VERSION ""

NS_ :

BS_:

BU_:  Inverter  Battery  Charger  Host

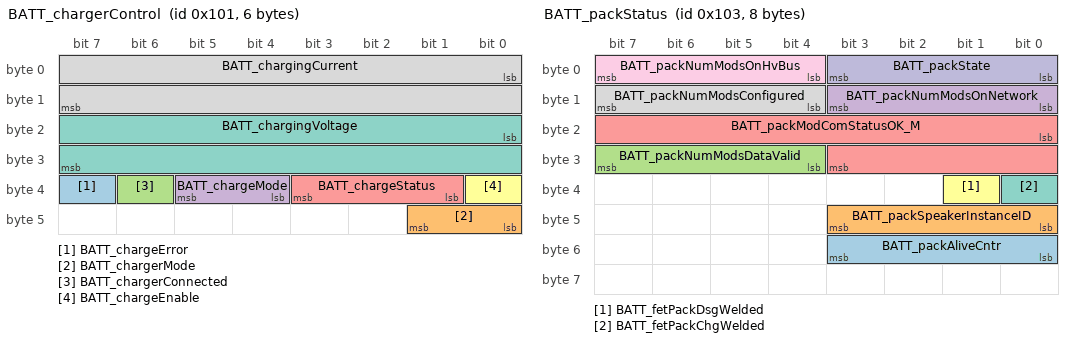
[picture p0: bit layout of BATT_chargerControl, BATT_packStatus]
BO_ 257 BATT_chargerControl: 6 Battery
 SG_ BATT_chargeError : 39|1@1+ (1,0) [0|1] "" Battery,Host
 SG_ BATT_chargerMode : 40|2@1+ (1,0) [0|3] "" Host
 SG_ BATT_chargerConnected : 38|1@1+ (1,0) [0|1] "" Battery,Host
 SG_ BATT_chargeMode : 36|2@1+ (1,0) [0|3] "" Host
 SG_ BATT_chargeStatus : 33|3@1+ (1,0) [0|4] "" Charger,Host
 SG_ BATT_chargeEnable : 32|1@1+ (1,0) [0|1] "" Charger,Host
 SG_ BATT_chargingVoltage : 16|16@1+ (0.005,0) [0|70] "V" Charger,Host
 SG_ BATT_chargingCurrent : 0|16@1+ (0.01,0) [0|40.95] "A" Charger,Host

BO_ 259 BATT_packStatus: 8 Battery
 SG_ BATT_packAliveCntr : 48|4@1+ (1,0) [0|15] "" Host
 SG_ BATT_packSpeakerInstanceID : 40|4@1+ (1,0) [0|15] "" Host
 SG_ BATT_packNumModsDataValid : 28|4@1+ (1,0) [0|15] "" Host
 SG_ BATT_packNumModsOnNetwork : 8|4@1+ (1,0) [0|15] "" Host
 SG_ BATT_packModComStatusOK_M : 16|12@1+ (1,0) [0|4095] "" Host
 SG_ BATT_fetPackDsgWelded : 33|1@1+ (1,0) [0|1] "" Host
 SG_ BATT_fetPackChgWelded : 32|1@1+ (1,0) [0|1] "" Host
 SG_ BATT_packNumModsConfigured : 12|4@1+ (1,0) [0|15] "" Host
 SG_ BATT_packNumModsOnHvBus : 4|4@1+ (1,0) [0|15] "" Host
 SG_ BATT_packState : 0|4@1+ (1,0) [0|15] "" Host

BO_ 260 BATT_packCapacity: 4 Battery
 SG_ BATT_packRemainingCap_Ah : 16|16@1+ (0.005,0) [0|327.675] "Ah" Host
 SG_ BATT_packFullChargeCap_Ah : 0|16@1+ (0.005,0) [0|327.675] "Ah" Host

BO_ 261 BATT_packSOC: 4 Battery
 SG_ BATT_packUserSOC : 0|16@1+ (0.1,0) [0|102.3] "%" Host
 SG_ BATT_packSOC : 16|16@1+ (0.1,0) [0|102.3] "%" Host

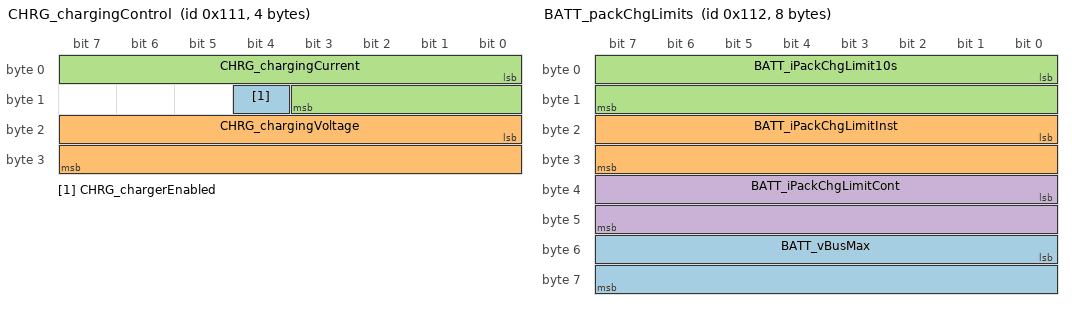
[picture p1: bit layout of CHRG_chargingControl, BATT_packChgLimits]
BO_ 273 CHRG_chargingControl: 4 Charger
 SG_ CHRG_chargerEnabled : 12|1@1+ (1,0) [0|1] "" Battery
 SG_ CHRG_chargingVoltage : 16|16@1+ (0.00076,0) [0|49.8066] "V" Battery
 SG_ CHRG_chargingCurrent : 0|12@1+ (0.01,0) [0|40.95] "A" Battery

BO_ 274 BATT_packChgLimits: 8 Battery
 SG_ BATT_vBusMax : 48|16@1+ (0.005,0) [0|70] "V" Inverter,Host
 SG_ BATT_iPackChgLimitInst : 16|16@1+ (0.01,0) [0|650] "A" Inverter,Host
 SG_ BATT_iPackChgLimit10s : 0|16@1+ (0.01,0) [0|650] "A" Inverter,Host
 SG_ BATT_iPackChgLimitCont : 32|16@1+ (0.01,0) [0|650] "A" Inverter,Host

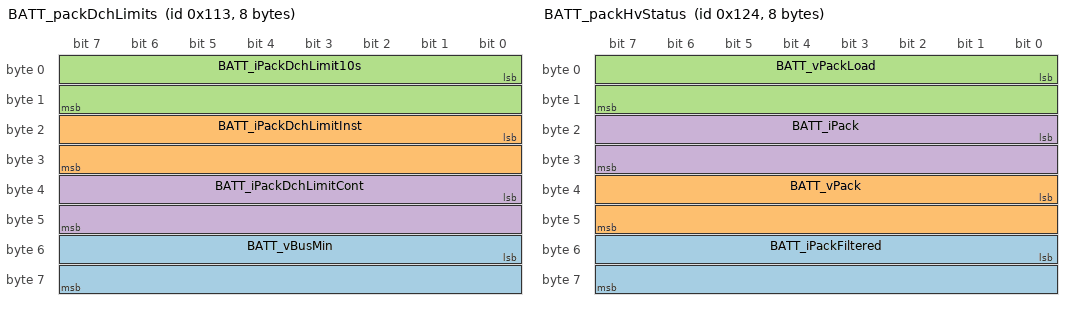
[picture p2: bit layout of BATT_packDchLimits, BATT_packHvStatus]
BO_ 275 BATT_packDchLimits: 8 Battery
 SG_ BATT_vBusMin : 48|16@1+ (0.005,0) [0|70] "V" Inverter,Host
 SG_ BATT_iPackDchLimitInst : 16|16@1- (0.03,0) [-1600|4] "A" Inverter,Host
 SG_ BATT_iPackDchLimit10s : 0|16@1- (0.03,0) [-1600|4] "A" Inverter,Host
 SG_ BATT_iPackDchLimitCont : 32|16@1- (0.03,0) [-1600|4] "A" Inverter,Host

BO_ 276 BATT_packPwrAvailable: 4 Battery
 SG_ BATT_pwrPackDchLimit : 16|16@1+ (0.02,0) [0|1200] "kW" Inverter,Host
 SG_ BATT_pwrPackChgLimit : 0|16@1+ (0.02,0) [0|1200] "kW" Inverter,Host

BO_ 277 INV_power: 4 Inverter
 SG_ INV_voltage : 0|16@1+ (0.00076,0) [0|49.8066] "V" Battery
 SG_ INV_current : 16|12@1+ (0.01,0) [0|40.95] "A" Battery

BO_ 292 BATT_packHvStatus: 8 Battery
 SG_ BATT_iPackFiltered : 48|16@1- (0.02,0) [-480|240] "A" Host
 SG_ BATT_vPack : 32|16@1+ (0.01,0) [0|70] "V" Host
 SG_ BATT_vPackLoad : 0|16@1+ (0.01,0) [0|70] "V" Host
 SG_ BATT_iPack : 16|16@1- (0.02,0) [-480|240] "" Host

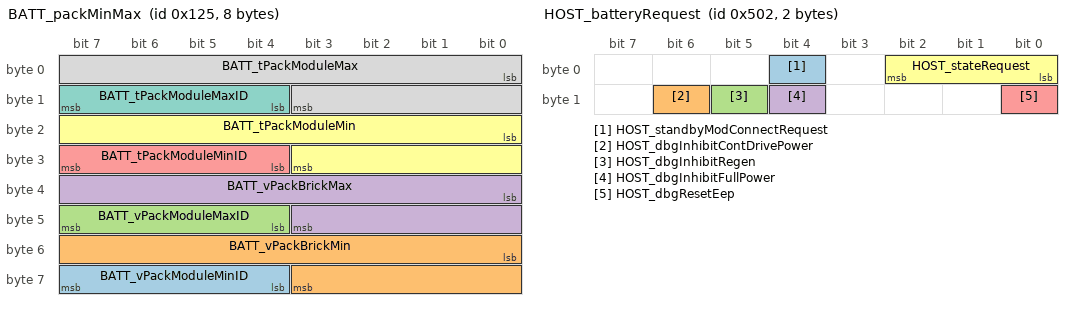
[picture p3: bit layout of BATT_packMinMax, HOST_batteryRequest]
BO_ 293 BATT_packMinMax: 8 Battery
 SG_ BATT_vPackModuleMinID : 60|4@1+ (1,0) [0|10] "" Host
 SG_ BATT_vPackBrickMin : 48|12@1+ (0.002,0) [0|4.98066] "V" Host
 SG_ BATT_vPackModuleMaxID : 44|4@1+ (1,0) [0|10] "" Host
 SG_ BATT_vPackBrickMax : 32|12@1+ (0.002,0) [0|4.98066] "V" Host
 SG_ BATT_tPackModuleMinID : 28|4@1+ (1,0) [0|10] "" Host
 SG_ BATT_tPackModuleMin : 16|12@1- (0.1,0) [-40|125] "deg C" Host
 SG_ BATT_tPackModuleMaxID : 12|4@1+ (1,0) [0|10] "" Host
 SG_ BATT_tPackModuleMax : 0|12@1- (0.1,0) [-40|125] "deg C" Host

BO_ 1282 HOST_batteryRequest: 2 Host
 SG_ HOST_standbyModConnectRequest : 4|1@1+ (1,0) [0|1] "" Battery
 SG_ HOST_dbgInhibitContDrivePower : 14|1@1+ (1,0) [0|1] "" Battery
 SG_ HOST_dbgInhibitRegen : 13|1@1+ (1,0) [0|1] "" Battery
 SG_ HOST_dbgInhibitFullPower : 12|1@1+ (1,0) [0|1] "" Battery
 SG_ HOST_dbgResetEep : 8|1@1+ (1,0) [0|1] "" Battery
 SG_ HOST_stateRequest : 0|3@1+ (1,0) [0|4] "" Battery

BO_ 1296 HOST_boardIO: 4 Host
 SG_ HOST_boardIO_PROTECTION_CHECK : 11|1@1+ (1,0) [0|0] "" Battery
 SG_ HOST_boardIO_BAL14 : 29|1@1+ (1,0) [0|0] "" Battery
 SG_ HOST_boardIO_BAL13 : 28|1@1+ (1,0) [0|0] "" Battery
 SG_ HOST_boardIO_BAL12 : 27|1@1+ (1,0) [0|0] "" Battery
 SG_ HOST_boardIO_BAL11 : 26|1@1+ (1,0) [0|0] "" Battery
 SG_ HOST_boardIO_BAL10 : 25|1@1+ (1,0) [0|0] "" Battery
 SG_ HOST_boardIO_BAL09 : 24|1@1+ (1,0) [0|0] "" Battery
 SG_ HOST_boardIO_BAL08 : 23|1@1+ (1,0) [0|0] "" Battery
 SG_ HOST_boardIO_BAL07 : 22|1@1+ (1,0) [0|0] "" Battery
 SG_ HOST_boardIO_BAL06 : 21|1@1+ (1,0) [0|0] "" Battery
 SG_ HOST_boardIO_BAL05 : 20|1@1+ (1,0) [0|0] "" Battery
 SG_ HOST_boardIO_BAL04 : 19|1@1+ (1,0) [0|0] "" Battery
 SG_ HOST_boardIO_BAL03 : 18|1@1+ (1,0) [0|0] "" Battery
 SG_ HOST_boardIO_BAL02 : 17|1@1+ (1,0) [0|0] "" Battery
 SG_ HOST_boardIO_BAL01 : 16|1@1+ (1,0) [0|0] "" Battery
 SG_ HOST_boardIO_LED4 : 8|1@1+ (1,0) [0|0] "" Battery
 SG_ HOST_boardIO_LED3 : 6|1@1+ (1,0) [0|0] "" Battery
 SG_ HOST_boardIO_LED2 : 2|1@1+ (1,0) [0|0] "" Battery
 SG_ HOST_boardIO_LED1 : 0|1@1+ (1,0) [0|0] "" Battery
 SG_ HOST_boardIO_PCHG : 7|1@1+ (1,0) [0|0] "" Battery
 SG_ HOST_boardIO_nFLT_CLR : 5|1@1+ (1,0) [0|0] "" Battery
 SG_ HOST_boardIO_DSG_EN : 4|1@1+ (1,0) [0|0] "" Battery
 SG_ HOST_boardIO_CHG_EN : 1|1@1+ (1,0) [0|0] "" Battery

BO_ 1632 BATT_BOOT_INFO_MSG_0: 8 Battery

BO_ 1633 BATT_BOOT_INFO_MSG_1: 8 Battery

BO_ 1634 BATT_BOOT_INFO_MSG_2: 8 Battery

BO_ 1635 BATT_BOOT_INFO_MSG_3: 8 Battery

BO_ 1636 BATT_BOOT_INFO_MSG_4: 8 Battery

BO_ 1637 BATT_BOOT_INFO_MSG_5: 8 Battery

BO_ 1638 BATT_BOOT_INFO_MSG_6: 8 Battery

BO_ 1639 BATT_BOOT_INFO_MSG_7: 8 Battery

BO_ 1640 BATT_BOOT_INFO_MSG_8: 8 Battery

BO_ 1641 BATT_BOOT_INFO_MSG_9: 8 Battery

BO_ 1642 BATT_BOOT_INFO_MSG_10: 8 Battery

BO_ 1643 BATT_BOOT_INFO_MSG_11: 8 Battery

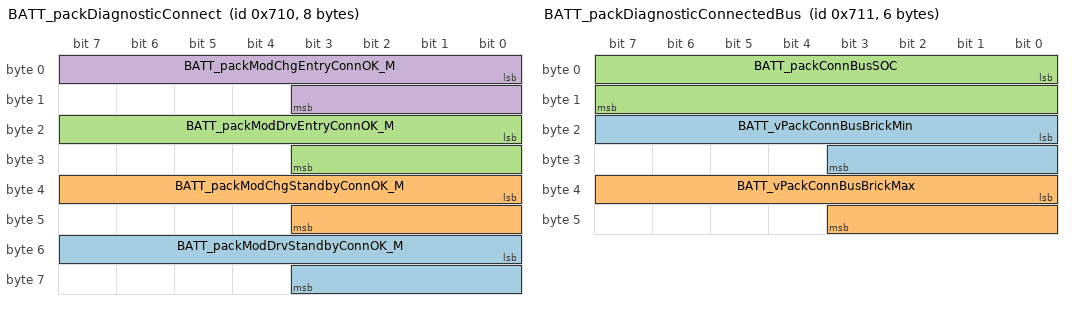
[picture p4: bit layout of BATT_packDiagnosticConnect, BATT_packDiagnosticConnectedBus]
BO_ 1808 BATT_packDiagnosticConnect: 8 Battery
 SG_ BATT_packModDrvStandbyConnOK_M : 48|12@1+ (1,0) [0|4095] "" Host
 SG_ BATT_packModChgStandbyConnOK_M : 32|12@1+ (1,0) [0|4095] "" Host
 SG_ BATT_packModDrvEntryConnOK_M : 16|12@1+ (1,0) [0|4095] "" Host
 SG_ BATT_packModChgEntryConnOK_M : 0|12@1+ (1,0) [0|4095] "" Host

BO_ 1809 BATT_packDiagnosticConnectedBus: 6 Battery
 SG_ BATT_vPackConnBusBrickMin : 16|12@1+ (0.002,0) [0|4.98066] "V" Host
 SG_ BATT_vPackConnBusBrickMax : 32|12@1+ (0.002,0) [0|4.98066] "V" Host
 SG_ BATT_packConnBusSOC : 0|16@1+ (0.1,0) [0|102.3] "%" Host

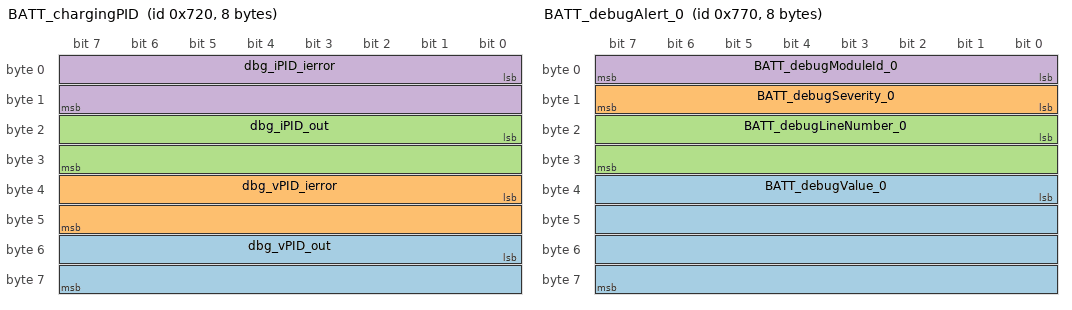
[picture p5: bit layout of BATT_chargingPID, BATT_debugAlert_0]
BO_ 1824 BATT_chargingPID: 8 Battery
 SG_ dbg_vPID_out : 48|16@1+ (0.01,0) [0|100] "" Host
 SG_ dbg_vPID_ierror : 32|16@1+ (0.1,0) [0|2000] "" Host
 SG_ dbg_iPID_out : 16|16@1+ (0.01,0) [0|100] "" Host
 SG_ dbg_iPID_ierror : 0|16@1+ (0.1,0) [0|2000] "" Host

BO_ 1904 BATT_debugAlert_0: 8 Battery
 SG_ BATT_debugValue_0 : 32|32@1+ (1,0) [0|4294967295] "" Host
 SG_ BATT_debugSeverity_0 : 8|8@1+ (1,0) [0|255] "" Host
 SG_ BATT_debugLineNumber_0 : 16|16@1+ (1,0) [0|65535] "" Host
 SG_ BATT_debugModuleId_0 : 0|8@1+ (1,0) [0|255] "" Host

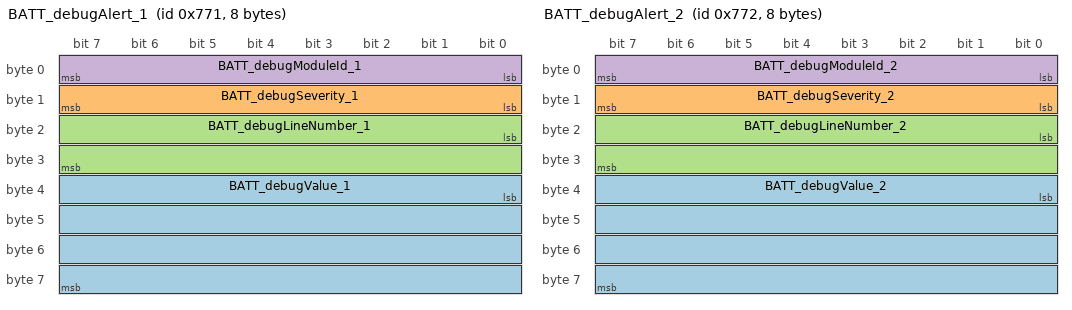
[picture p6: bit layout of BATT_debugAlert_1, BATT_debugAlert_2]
BO_ 1905 BATT_debugAlert_1: 8 Battery
 SG_ BATT_debugValue_1 : 32|32@1+ (1,0) [0|4294967295] "" Host
 SG_ BATT_debugSeverity_1 : 8|8@1+ (1,0) [0|255] "" Host
 SG_ BATT_debugLineNumber_1 : 16|16@1+ (1,0) [0|65535] "" Host
 SG_ BATT_debugModuleId_1 : 0|8@1+ (1,0) [0|255] "" Host

BO_ 1906 BATT_debugAlert_2: 8 Battery
 SG_ BATT_debugValue_2 : 32|32@1+ (1,0) [0|4294967295] "" Host
 SG_ BATT_debugSeverity_2 : 8|8@1+ (1,0) [0|255] "" Host
 SG_ BATT_debugLineNumber_2 : 16|16@1+ (1,0) [0|65535] "" Host
 SG_ BATT_debugModuleId_2 : 0|8@1+ (1,0) [0|255] "" Host

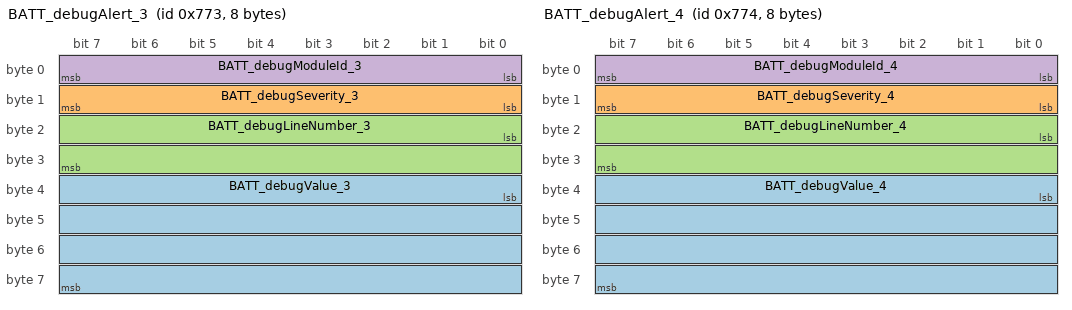
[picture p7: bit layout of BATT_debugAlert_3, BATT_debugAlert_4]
BO_ 1907 BATT_debugAlert_3: 8 Battery
 SG_ BATT_debugValue_3 : 32|32@1+ (1,0) [0|4294967295] "" Host
 SG_ BATT_debugSeverity_3 : 8|8@1+ (1,0) [0|255] "" Host
 SG_ BATT_debugLineNumber_3 : 16|16@1+ (1,0) [0|65535] "" Host
 SG_ BATT_debugModuleId_3 : 0|8@1+ (1,0) [0|255] "" Host

BO_ 1908 BATT_debugAlert_4: 8 Battery
 SG_ BATT_debugValue_4 : 32|32@1+ (1,0) [0|4294967295] "" Host
 SG_ BATT_debugSeverity_4 : 8|8@1+ (1,0) [0|255] "" Host
 SG_ BATT_debugLineNumber_4 : 16|16@1+ (1,0) [0|65535] "" Host
 SG_ BATT_debugModuleId_4 : 0|8@1+ (1,0) [0|255] "" Host

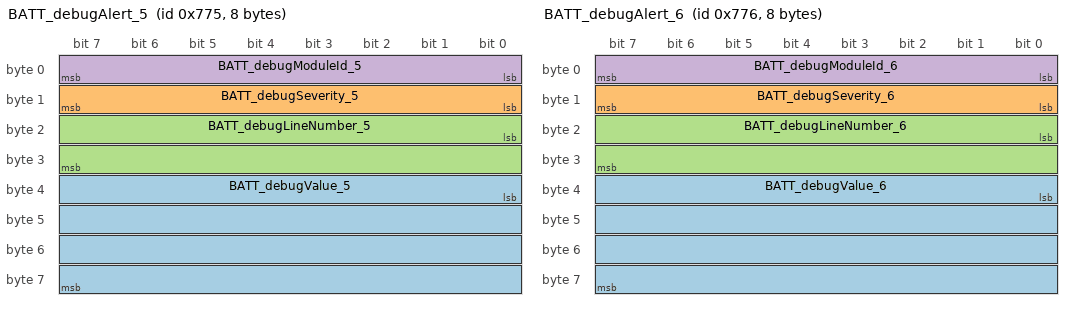
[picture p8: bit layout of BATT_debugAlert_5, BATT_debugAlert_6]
BO_ 1909 BATT_debugAlert_5: 8 Battery
 SG_ BATT_debugValue_5 : 32|32@1+ (1,0) [0|4294967295] "" Host
 SG_ BATT_debugSeverity_5 : 8|8@1+ (1,0) [0|255] "" Host
 SG_ BATT_debugLineNumber_5 : 16|16@1+ (1,0) [0|65535] "" Host
 SG_ BATT_debugModuleId_5 : 0|8@1+ (1,0) [0|255] "" Host

BO_ 1910 BATT_debugAlert_6: 8 Battery
 SG_ BATT_debugValue_6 : 32|32@1+ (1,0) [0|4294967295] "" Host
 SG_ BATT_debugSeverity_6 : 8|8@1+ (1,0) [0|255] "" Host
 SG_ BATT_debugLineNumber_6 : 16|16@1+ (1,0) [0|65535] "" Host
 SG_ BATT_debugModuleId_6 : 0|8@1+ (1,0) [0|255] "" Host

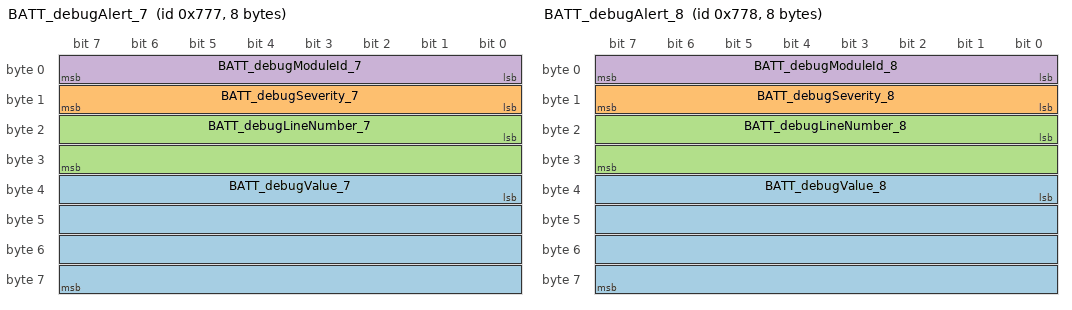
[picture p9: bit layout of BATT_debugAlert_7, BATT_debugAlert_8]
BO_ 1911 BATT_debugAlert_7: 8 Battery
 SG_ BATT_debugValue_7 : 32|32@1+ (1,0) [0|4294967295] "" Host
 SG_ BATT_debugSeverity_7 : 8|8@1+ (1,0) [0|255] "" Host
 SG_ BATT_debugLineNumber_7 : 16|16@1+ (1,0) [0|65535] "" Host
 SG_ BATT_debugModuleId_7 : 0|8@1+ (1,0) [0|255] "" Host

BO_ 1912 BATT_debugAlert_8: 8 Battery
 SG_ BATT_debugValue_8 : 32|32@1+ (1,0) [0|4294967295] "" Host
 SG_ BATT_debugSeverity_8 : 8|8@1+ (1,0) [0|255] "" Host
 SG_ BATT_debugLineNumber_8 : 16|16@1+ (1,0) [0|65535] "" Host
 SG_ BATT_debugModuleId_8 : 0|8@1+ (1,0) [0|255] "" Host

BO_ 1913 BATT_debugAlert_9: 8 Battery
 SG_ BATT_debugValue_9 : 32|32@1+ (1,0) [0|4294967295] "" Host
 SG_ BATT_debugSeverity_9 : 8|8@1+ (1,0) [0|255] "" Host
 SG_ BATT_debugLineNumber_9 : 16|16@1+ (1,0) [0|65535] "" Host
 SG_ BATT_debugModuleId_9 : 0|8@1+ (1,0) [0|255] "" Host

BO_ 1914 BATT_debugAlert_10: 8 Battery
 SG_ BATT_debugValue_10 : 32|32@1+ (1,0) [0|4294967295] "" Host
 SG_ BATT_debugSeverity_10 : 8|8@1+ (1,0) [0|255] "" Host
 SG_ BATT_debugLineNumber_10 : 16|16@1+ (1,0) [0|65535] "" Host
 SG_ BATT_debugModuleId_10 : 0|8@1+ (1,0) [0|255] "" Host

BO_ 1915 BATT_debugAlert_11: 8 Battery
 SG_ BATT_debugValue_11 : 32|32@1+ (1,0) [0|4294967295] "" Host
 SG_ BATT_debugSeverity_11 : 8|8@1+ (1,0) [0|255] "" Host
 SG_ BATT_debugLineNumber_11 : 16|16@1+ (1,0) [0|65535] "" Host
 SG_ BATT_debugModuleId_11 : 0|8@1+ (1,0) [0|255] "" Host

BO_ 1952 HOST_dbgChargePID: 8 Host
 SG_ dbg_iPID_ki : 48|16@1+ (0.01,0) [0|10] "" Battery
 SG_ dbg_iPID_kp : 32|16@1+ (0.01,0) [0|10] "" Battery
 SG_ dbg_vPID_ki : 16|16@1+ (0.01,0) [0|10] "" Battery
 SG_ dbg_vPID_kp : 0|16@1+ (0.01,0) [0|10] "" Battery

BO_ 1953 HOST_dbgChargeCtrl: 8 Host
 SG_ dbg_chargeCtrl_vTarget : 16|16@1+ (7.6e-05,0) [0|4.98066] "V" Battery
 SG_ dbg_chargeCtrl_iChgLimit : 0|16@1+ (0.01,0) [0|16] "A" Battery

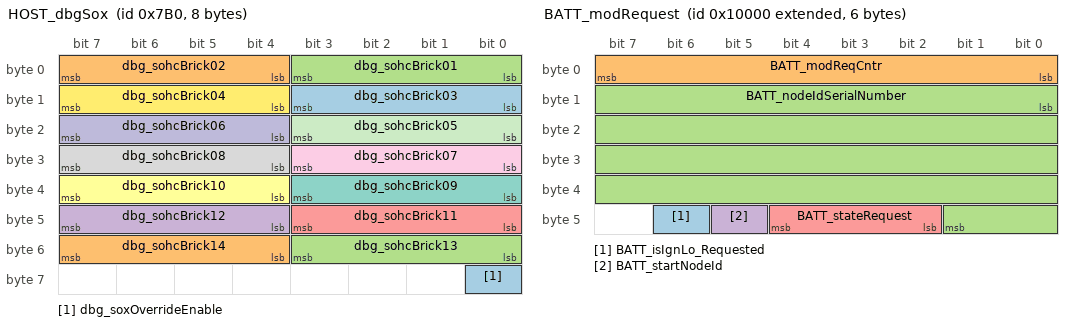
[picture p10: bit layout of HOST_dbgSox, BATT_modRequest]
BO_ 1968 HOST_dbgSox: 8 Host
 SG_ dbg_soxOverrideEnable : 56|1@1+ (1,0) [0|1] "" Battery
 SG_ dbg_sohcBrick14 : 52|4@1+ (0.015,0.775) [0.775|1] "" Battery
 SG_ dbg_sohcBrick13 : 48|4@1+ (0.015,0.775) [0.775|1] "" Battery
 SG_ dbg_sohcBrick12 : 44|4@1+ (0.015,0.775) [0.775|1] "" Battery
 SG_ dbg_sohcBrick11 : 40|4@1+ (0.015,0.775) [0.775|1] "" Battery
 SG_ dbg_sohcBrick10 : 36|4@1+ (0.015,0.775) [0.775|1] "" Battery
 SG_ dbg_sohcBrick09 : 32|4@1+ (0.015,0.775) [0.775|1] "" Battery
 SG_ dbg_sohcBrick08 : 28|4@1+ (0.015,0.775) [0.775|1] "" Battery
 SG_ dbg_sohcBrick07 : 24|4@1+ (0.015,0.775) [0.775|1] "" Battery
 SG_ dbg_sohcBrick06 : 20|4@1+ (0.015,0.775) [0.775|1] "" Battery
 SG_ dbg_sohcBrick05 : 16|4@1+ (0.015,0.775) [0.775|1] "" Battery
 SG_ dbg_sohcBrick04 : 12|4@1+ (0.015,0.775) [0.775|1] "" Battery
 SG_ dbg_sohcBrick03 : 8|4@1+ (0.015,0.775) [0.775|1] "" Battery
 SG_ dbg_sohcBrick02 : 4|4@1+ (0.015,0.775) [0.775|1] "" Battery
 SG_ dbg_sohcBrick01 : 0|4@1+ (0.015,0.775) [0.775|1] "" Battery

BO_ 2147500032 NODE_ID_CLAIM: 8 Battery
 SG_ NODE_ID_CLAIM_RND : 34|30@1+ (1,0) [0|4294967295] "" Battery,Host
 SG_ NODE_ID_CLAIM_SN : 0|34@1+ (1,0) [0|4294967295] "" Battery,Host

BO_ 2147516416 HOST_nodeRequest: 8 Host
 SG_ HOST_securityKey : 16|48@1+ (1,0) [0|281474976710655] "" Battery
 SG_ HOST_startNodeId : 0|1@1+ (1,0) [0|1] "" Battery

BO_ 2147549184 BATT_modRequest: 6 Battery
 SG_ BATT_isIgnLo_Requested : 46|1@1+ (1,0) [0|1] "" Battery,Host
 SG_ BATT_modReqCntr : 0|8@1+ (1,0) [0|255] "" Battery,Host
 SG_ BATT_nodeIdSerialNumber : 8|34@1+ (1,0) [0|17179869183] "" Battery,Host
 SG_ BATT_startNodeId : 45|1@1+ (1,0) [0|1] "" Battery,Host
 SG_ BATT_stateRequest : 42|3@1+ (1,0) [0|7] "" Battery,Host

BO_ 2176909312 BATT_diagnosticModBusStatus_0: 2 Battery
 SG_ BATT_timeBusQuietStandby_0 : 0|10@1+ (1,0) [0|1023] "seconds" Host
 SG_ BATT_timeBusQuietSleep_0 : 10|6@1+ (1,0) [0|63] "seconds" Host

BO_ 2176909313 BATT_diagnosticModBusStatus_1: 2 Battery
 SG_ BATT_timeBusQuietStandby_1 : 0|10@1+ (1,0) [0|1023] "seconds" Host
 SG_ BATT_timeBusQuietSleep_1 : 10|6@1+ (1,0) [0|63] "seconds" Host

BO_ 2176909314 BATT_diagnosticModBusStatus_2: 2 Battery
 SG_ BATT_timeBusQuietStandby_2 : 0|10@1+ (1,0) [0|1023] "seconds" Host
 SG_ BATT_timeBusQuietSleep_2 : 10|6@1+ (1,0) [0|63] "seconds" Host

BO_ 2176909315 BATT_diagnosticModBusStatus_3: 2 Battery
 SG_ BATT_timeBusQuietStandby_3 : 0|10@1+ (1,0) [0|1023] "seconds" Host
 SG_ BATT_timeBusQuietSleep_3 : 10|6@1+ (1,0) [0|63] "seconds" Host

BO_ 2176909316 BATT_diagnosticModBusStatus_4: 2 Battery
 SG_ BATT_timeBusQuietStandby_4 : 0|10@1+ (1,0) [0|1023] "seconds" Host
 SG_ BATT_timeBusQuietSleep_4 : 10|6@1+ (1,0) [0|63] "seconds" Host

BO_ 2176909317 BATT_diagnosticModBusStatus_5: 2 Battery
 SG_ BATT_timeBusQuietStandby_5 : 0|10@1+ (1,0) [0|1023] "seconds" Host
 SG_ BATT_timeBusQuietSleep_5 : 10|6@1+ (1,0) [0|63] "seconds" Host

BO_ 2176909318 BATT_diagnosticModBusStatus_6: 2 Battery
 SG_ BATT_timeBusQuietStandby_6 : 0|10@1+ (1,0) [0|1023] "seconds" Host
 SG_ BATT_timeBusQuietSleep_6 : 10|6@1+ (1,0) [0|63] "seconds" Host

BO_ 2176909319 BATT_diagnosticModBusStatus_7: 2 Battery
 SG_ BATT_timeBusQuietStandby_7 : 0|10@1+ (1,0) [0|1023] "seconds" Host
 SG_ BATT_timeBusQuietSleep_7 : 10|6@1+ (1,0) [0|63] "seconds" Host

BO_ 2176909320 BATT_diagnosticModBusStatus_8: 2 Battery
 SG_ BATT_timeBusQuietStandby_8 : 0|10@1+ (1,0) [0|1023] "seconds" Host
 SG_ BATT_timeBusQuietSleep_8 : 10|6@1+ (1,0) [0|63] "seconds" Host

BO_ 2176909321 BATT_diagnosticModBusStatus_9: 2 Battery
 SG_ BATT_timeBusQuietStandby_9 : 0|10@1+ (1,0) [0|1023] "seconds" Host
 SG_ BATT_timeBusQuietSleep_9 : 10|6@1+ (1,0) [0|63] "seconds" Host

BO_ 2176909322 BATT_diagnosticModBusStatus_10: 2 Battery
 SG_ BATT_timeBusQuietStandby_10 : 0|10@1+ (1,0) [0|1023] "seconds" Host
 SG_ BATT_timeBusQuietSleep_10 : 10|6@1+ (1,0) [0|63] "seconds" Host

BO_ 2176909323 BATT_diagnosticModBusStatus_11: 2 Battery
 SG_ BATT_timeBusQuietStandby_11 : 0|10@1+ (1,0) [0|1023] "seconds" Host
 SG_ BATT_timeBusQuietSleep_11 : 10|6@1+ (1,0) [0|63] "seconds" Host

BO_ 2215116800 BATT_modCapacity_0: 8 Battery
 SG_ BATT_modFullChargeCap_Ah_0 : 16|16@1+ (0.005,0) [0|327.675] "Ah" Battery,Host
 SG_ BATT_modRemainingCap_Ah_0 : 0|16@1+ (0.005,0) [0|327.675] "Ah" Battery,Host

BO_ 2215116801 BATT_modCapacity_1: 8 Battery
 SG_ BATT_modFullChargeCap_Ah_1 : 16|16@1+ (0.005,0) [0|327.675] "Ah" Battery,Host
 SG_ BATT_modRemainingCap_Ah_1 : 0|16@1+ (0.005,0) [0|327.675] "Ah" Battery,Host

BO_ 2215116802 BATT_modCapacity_2: 8 Battery
 SG_ BATT_modFullChargeCap_Ah_2 : 16|16@1+ (0.005,0) [0|327.675] "Ah" Battery,Host
 SG_ BATT_modRemainingCap_Ah_2 : 0|16@1+ (0.005,0) [0|327.675] "Ah" Battery,Host

BO_ 2215116803 BATT_modCapacity_3: 8 Battery
 SG_ BATT_modFullChargeCap_Ah_3 : 16|16@1+ (0.005,0) [0|327.675] "Ah" Battery,Host
 SG_ BATT_modRemainingCap_Ah_3 : 0|16@1+ (0.005,0) [0|327.675] "Ah" Battery,Host

BO_ 2215116804 BATT_modCapacity_4: 8 Battery
 SG_ BATT_modFullChargeCap_Ah_4 : 16|16@1+ (0.005,0) [0|327.675] "Ah" Battery,Host
 SG_ BATT_modRemainingCap_Ah_4 : 0|16@1+ (0.005,0) [0|327.675] "Ah" Battery,Host

BO_ 2215116805 BATT_modCapacity_5: 8 Battery
 SG_ BATT_modFullChargeCap_Ah_5 : 16|16@1+ (0.005,0) [0|327.675] "Ah" Battery,Host
 SG_ BATT_modRemainingCap_Ah_5 : 0|16@1+ (0.005,0) [0|327.675] "Ah" Battery,Host

BO_ 2215116806 BATT_modCapacity_6: 8 Battery
 SG_ BATT_modFullChargeCap_Ah_6 : 16|16@1+ (0.005,0) [0|327.675] "Ah" Battery,Host
 SG_ BATT_modRemainingCap_Ah_6 : 0|16@1+ (0.005,0) [0|327.675] "Ah" Battery,Host

BO_ 2215116807 BATT_modCapacity_7: 8 Battery
 SG_ BATT_modFullChargeCap_Ah_7 : 16|16@1+ (0.005,0) [0|327.675] "Ah" Battery,Host
 SG_ BATT_modRemainingCap_Ah_7 : 0|16@1+ (0.005,0) [0|327.675] "Ah" Battery,Host

BO_ 2215116808 BATT_modCapacity_8: 8 Battery
 SG_ BATT_modFullChargeCap_Ah_8 : 16|16@1+ (0.005,0) [0|327.675] "Ah" Battery,Host
 SG_ BATT_modRemainingCap_Ah_8 : 0|16@1+ (0.005,0) [0|327.675] "Ah" Battery,Host

BO_ 2215116809 BATT_modCapacity_9: 8 Battery
 SG_ BATT_modFullChargeCap_Ah_9 : 16|16@1+ (0.005,0) [0|327.675] "Ah" Battery,Host
 SG_ BATT_modRemainingCap_Ah_9 : 0|16@1+ (0.005,0) [0|327.675] "Ah" Battery,Host

BO_ 2215116810 BATT_modCapacity_10: 8 Battery
 SG_ BATT_modFullChargeCap_Ah_10 : 16|16@1+ (0.005,0) [0|327.675] "Ah" Battery,Host
 SG_ BATT_modRemainingCap_Ah_10 : 0|16@1+ (0.005,0) [0|327.675] "Ah" Battery,Host

BO_ 2215116811 BATT_modCapacity_11: 8 Battery
 SG_ BATT_modFullChargeCap_Ah_11 : 16|16@1+ (0.005,0) [0|327.675] "Ah" Battery,Host
 SG_ BATT_modRemainingCap_Ah_11 : 0|16@1+ (0.005,0) [0|327.675] "Ah" Battery,Host

BO_ 2215378944 BATT_modHvStatus_0: 8 Battery
 SG_ BATT_vMod_0 : 32|16@1+ (0.01,0) [0|70] "V" Battery,Host
 SG_ BATT_vModSumOfCells_0 : 48|16@1+ (0.01,0) [0|70] "V" Battery,Host
 SG_ BATT_iMod_0 : 16|16@1- (0.005,0) [-120|60] "A" Battery,Host
 SG_ BATT_iModFiltered_0 : 0|16@1- (0.005,0) [-120|60] "A" Battery,Host

BO_ 2215378945 BATT_modHvStatus_1: 8 Battery
 SG_ BATT_vMod_1 : 32|16@1+ (0.01,0) [0|70] "V" Battery,Host
 SG_ BATT_vModSumOfCells_1 : 48|16@1+ (0.01,0) [0|70] "V" Battery,Host
 SG_ BATT_iMod_1 : 16|16@1- (0.005,0) [-120|60] "A" Battery,Host
 SG_ BATT_iModFiltered_1 : 0|16@1- (0.005,0) [-120|60] "A" Battery,Host

BO_ 2215378946 BATT_modHvStatus_2: 8 Battery
 SG_ BATT_vMod_2 : 32|16@1+ (0.01,0) [0|70] "V" Battery,Host
 SG_ BATT_vModSumOfCells_2 : 48|16@1+ (0.01,0) [0|70] "V" Battery,Host
 SG_ BATT_iMod_2 : 16|16@1- (0.005,0) [-120|60] "A" Battery,Host
 SG_ BATT_iModFiltered_2 : 0|16@1- (0.005,0) [-120|60] "A" Battery,Host

BO_ 2215378947 BATT_modHvStatus_3: 8 Battery
 SG_ BATT_vMod_3 : 32|16@1+ (0.01,0) [0|70] "V" Battery,Host
 SG_ BATT_vModSumOfCells_3 : 48|16@1+ (0.01,0) [0|70] "V" Battery,Host
 SG_ BATT_iMod_3 : 16|16@1- (0.005,0) [-120|60] "A" Battery,Host
 SG_ BATT_iModFiltered_3 : 0|16@1- (0.005,0) [-120|60] "A" Battery,Host

BO_ 2215378948 BATT_modHvStatus_4: 8 Battery
 SG_ BATT_vMod_4 : 32|16@1+ (0.01,0) [0|70] "V" Battery,Host
 SG_ BATT_vModSumOfCells_4 : 48|16@1+ (0.01,0) [0|70] "V" Battery,Host
 SG_ BATT_iMod_4 : 16|16@1- (0.005,0) [-120|60] "A" Battery,Host
 SG_ BATT_iModFiltered_4 : 0|16@1- (0.005,0) [-120|60] "A" Battery,Host

BO_ 2215378949 BATT_modHvStatus_5: 8 Battery
 SG_ BATT_vMod_5 : 32|16@1+ (0.01,0) [0|70] "V" Battery,Host
 SG_ BATT_vModSumOfCells_5 : 48|16@1+ (0.01,0) [0|70] "V" Battery,Host
 SG_ BATT_iMod_5 : 16|16@1- (0.005,0) [-120|60] "A" Battery,Host
 SG_ BATT_iModFiltered_5 : 0|16@1- (0.005,0) [-120|60] "A" Battery,Host

BO_ 2215378950 BATT_modHvStatus_6: 8 Battery
 SG_ BATT_vMod_6 : 32|16@1+ (0.01,0) [0|70] "V" Battery,Host
 SG_ BATT_vModSumOfCells_6 : 48|16@1+ (0.01,0) [0|70] "V" Battery,Host
 SG_ BATT_iMod_6 : 16|16@1- (0.005,0) [-120|60] "A" Battery,Host
 SG_ BATT_iModFiltered_6 : 0|16@1- (0.005,0) [-120|60] "A" Battery,Host

BO_ 2215378951 BATT_modHvStatus_7: 8 Battery
 SG_ BATT_vMod_7 : 32|16@1+ (0.01,0) [0|70] "V" Battery,Host
 SG_ BATT_vModSumOfCells_7 : 48|16@1+ (0.01,0) [0|70] "V" Battery,Host
 SG_ BATT_iMod_7 : 16|16@1- (0.005,0) [-120|60] "A" Battery,Host
 SG_ BATT_iModFiltered_7 : 0|16@1- (0.005,0) [-120|60] "A" Battery,Host

BO_ 2215378952 BATT_modHvStatus_8: 8 Battery
 SG_ BATT_vMod_8 : 32|16@1+ (0.01,0) [0|70] "V" Battery,Host
 SG_ BATT_vModSumOfCells_8 : 48|16@1+ (0.01,0) [0|70] "V" Battery,Host
 SG_ BATT_iMod_8 : 16|16@1- (0.005,0) [-120|60] "A" Battery,Host
 SG_ BATT_iModFiltered_8 : 0|16@1- (0.005,0) [-120|60] "A" Battery,Host

BO_ 2215378953 BATT_modHvStatus_9: 8 Battery
 SG_ BATT_vMod_9 : 32|16@1+ (0.01,0) [0|70] "V" Battery,Host
 SG_ BATT_vModSumOfCells_9 : 48|16@1+ (0.01,0) [0|70] "V" Battery,Host
 SG_ BATT_iMod_9 : 16|16@1- (0.005,0) [-120|60] "A" Battery,Host
 SG_ BATT_iModFiltered_9 : 0|16@1- (0.005,0) [-120|60] "A" Battery,Host

BO_ 2215378954 BATT_modHvStatus_10: 8 Battery
 SG_ BATT_vMod_10 : 32|16@1+ (0.01,0) [0|70] "V" Battery,Host
 SG_ BATT_vModSumOfCells_10 : 48|16@1+ (0.01,0) [0|70] "V" Battery,Host
 SG_ BATT_iMod_10 : 16|16@1- (0.005,0) [-120|60] "A" Battery,Host
 SG_ BATT_iModFiltered_10 : 0|16@1- (0.005,0) [-120|60] "A" Battery,Host

BO_ 2215378955 BATT_modHvStatus_11: 8 Battery
 SG_ BATT_vMod_11 : 32|16@1+ (0.01,0) [0|70] "V" Battery,Host
 SG_ BATT_vModSumOfCells_11 : 48|16@1+ (0.01,0) [0|70] "V" Battery,Host
 SG_ BATT_iMod_11 : 16|16@1- (0.005,0) [-120|60] "A" Battery,Host
 SG_ BATT_iModFiltered_11 : 0|16@1- (0.005,0) [-120|60] "A" Battery,Host

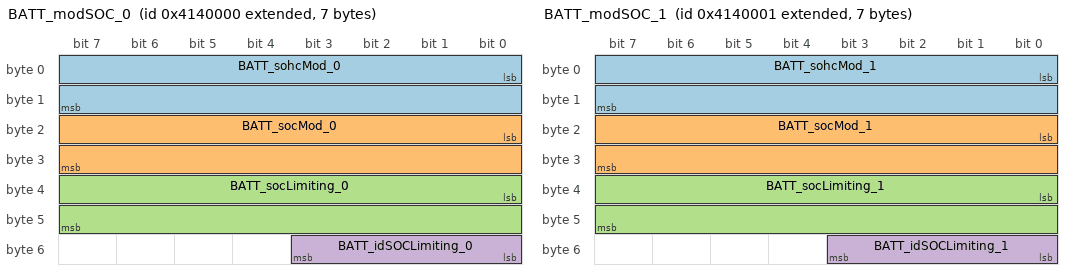
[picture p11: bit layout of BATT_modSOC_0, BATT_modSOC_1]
BO_ 2215903232 BATT_modSOC_0: 7 Battery
 SG_ BATT_sohcMod_0 : 0|16@1+ (0.01,0) [0|100] "%" Battery,Host
 SG_ BATT_socMod_0 : 16|16@1+ (0.01,0) [0|102.3] "%" Battery,Host
 SG_ BATT_socLimiting_0 : 32|16@1+ (0.01,0) [0|102.3] "%" Battery,Host
 SG_ BATT_idSOCLimiting_0 : 48|4@1+ (1,0) [0|14] "" Battery,Host

BO_ 2215903233 BATT_modSOC_1: 7 Battery
 SG_ BATT_sohcMod_1 : 0|16@1+ (0.01,0) [0|100] "%" Battery,Host
 SG_ BATT_socMod_1 : 16|16@1+ (0.01,0) [0|102.3] "%" Battery,Host
 SG_ BATT_socLimiting_1 : 32|16@1+ (0.01,0) [0|102.3] "%" Battery,Host
 SG_ BATT_idSOCLimiting_1 : 48|4@1+ (1,0) [0|14] "" Battery,Host

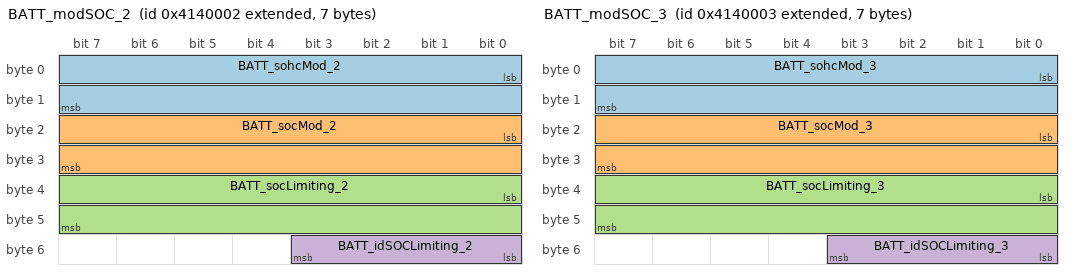
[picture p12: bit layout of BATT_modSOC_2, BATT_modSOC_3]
BO_ 2215903234 BATT_modSOC_2: 7 Battery
 SG_ BATT_sohcMod_2 : 0|16@1+ (0.01,0) [0|100] "%" Battery,Host
 SG_ BATT_socMod_2 : 16|16@1+ (0.01,0) [0|102.3] "%" Battery,Host
 SG_ BATT_socLimiting_2 : 32|16@1+ (0.01,0) [0|102.3] "%" Battery,Host
 SG_ BATT_idSOCLimiting_2 : 48|4@1+ (1,0) [0|14] "" Battery,Host

BO_ 2215903235 BATT_modSOC_3: 7 Battery
 SG_ BATT_sohcMod_3 : 0|16@1+ (0.01,0) [0|100] "%" Battery,Host
 SG_ BATT_socMod_3 : 16|16@1+ (0.01,0) [0|102.3] "%" Battery,Host
 SG_ BATT_socLimiting_3 : 32|16@1+ (0.01,0) [0|102.3] "%" Battery,Host
 SG_ BATT_idSOCLimiting_3 : 48|4@1+ (1,0) [0|14] "" Battery,Host

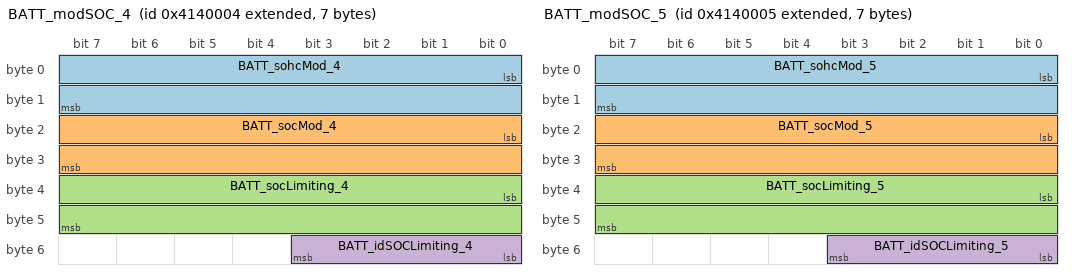
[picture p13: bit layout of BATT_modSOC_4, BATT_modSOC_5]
BO_ 2215903236 BATT_modSOC_4: 7 Battery
 SG_ BATT_sohcMod_4 : 0|16@1+ (0.01,0) [0|100] "%" Battery,Host
 SG_ BATT_socMod_4 : 16|16@1+ (0.01,0) [0|102.3] "%" Battery,Host
 SG_ BATT_socLimiting_4 : 32|16@1+ (0.01,0) [0|102.3] "%" Battery,Host
 SG_ BATT_idSOCLimiting_4 : 48|4@1+ (1,0) [0|14] "" Battery,Host

BO_ 2215903237 BATT_modSOC_5: 7 Battery
 SG_ BATT_sohcMod_5 : 0|16@1+ (0.01,0) [0|100] "%" Battery,Host
 SG_ BATT_socMod_5 : 16|16@1+ (0.01,0) [0|102.3] "%" Battery,Host
 SG_ BATT_socLimiting_5 : 32|16@1+ (0.01,0) [0|102.3] "%" Battery,Host
 SG_ BATT_idSOCLimiting_5 : 48|4@1+ (1,0) [0|14] "" Battery,Host

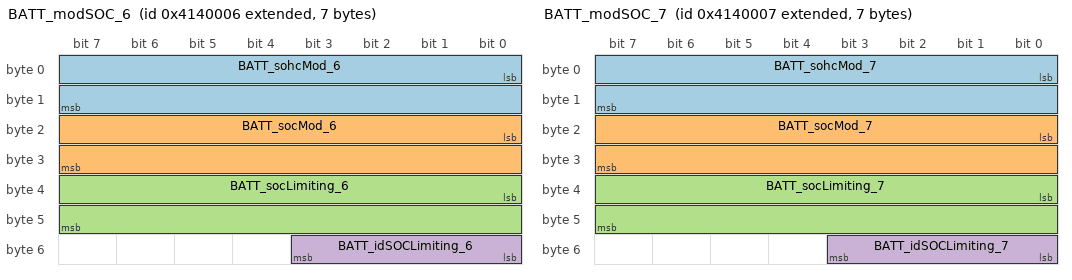
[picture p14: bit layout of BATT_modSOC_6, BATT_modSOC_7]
BO_ 2215903238 BATT_modSOC_6: 7 Battery
 SG_ BATT_sohcMod_6 : 0|16@1+ (0.01,0) [0|100] "%" Battery,Host
 SG_ BATT_socMod_6 : 16|16@1+ (0.01,0) [0|102.3] "%" Battery,Host
 SG_ BATT_socLimiting_6 : 32|16@1+ (0.01,0) [0|102.3] "%" Battery,Host
 SG_ BATT_idSOCLimiting_6 : 48|4@1+ (1,0) [0|14] "" Battery,Host

BO_ 2215903239 BATT_modSOC_7: 7 Battery
 SG_ BATT_sohcMod_7 : 0|16@1+ (0.01,0) [0|100] "%" Battery,Host
 SG_ BATT_socMod_7 : 16|16@1+ (0.01,0) [0|102.3] "%" Battery,Host
 SG_ BATT_socLimiting_7 : 32|16@1+ (0.01,0) [0|102.3] "%" Battery,Host
 SG_ BATT_idSOCLimiting_7 : 48|4@1+ (1,0) [0|14] "" Battery,Host

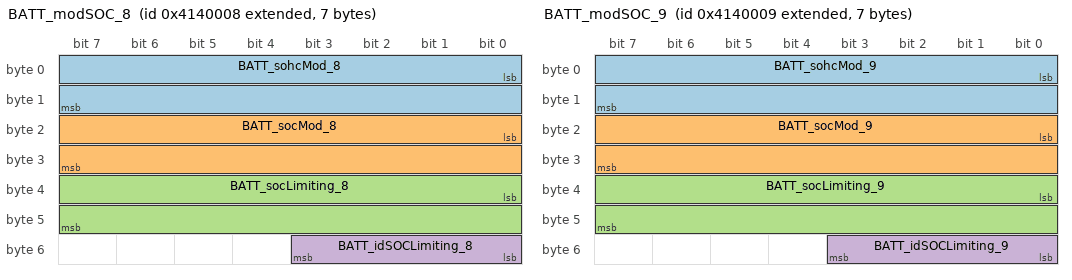
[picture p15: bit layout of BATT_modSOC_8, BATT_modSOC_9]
BO_ 2215903240 BATT_modSOC_8: 7 Battery
 SG_ BATT_sohcMod_8 : 0|16@1+ (0.01,0) [0|100] "%" Battery,Host
 SG_ BATT_socMod_8 : 16|16@1+ (0.01,0) [0|102.3] "%" Battery,Host
 SG_ BATT_socLimiting_8 : 32|16@1+ (0.01,0) [0|102.3] "%" Battery,Host
 SG_ BATT_idSOCLimiting_8 : 48|4@1+ (1,0) [0|14] "" Battery,Host

BO_ 2215903241 BATT_modSOC_9: 7 Battery
 SG_ BATT_sohcMod_9 : 0|16@1+ (0.01,0) [0|100] "%" Battery,Host
 SG_ BATT_socMod_9 : 16|16@1+ (0.01,0) [0|102.3] "%" Battery,Host
 SG_ BATT_socLimiting_9 : 32|16@1+ (0.01,0) [0|102.3] "%" Battery,Host
 SG_ BATT_idSOCLimiting_9 : 48|4@1+ (1,0) [0|14] "" Battery,Host

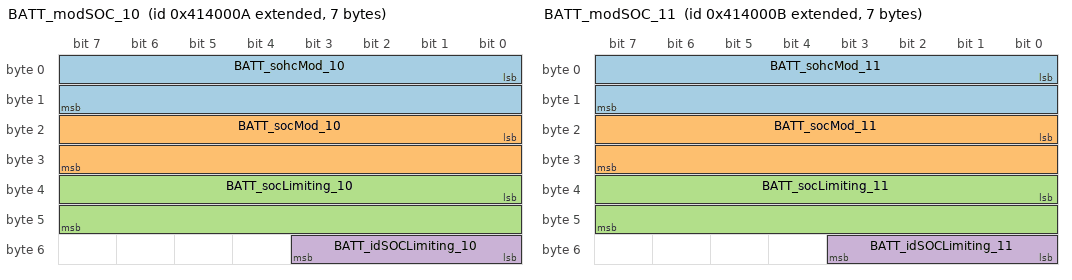
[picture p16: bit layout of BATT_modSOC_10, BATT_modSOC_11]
BO_ 2215903242 BATT_modSOC_10: 7 Battery
 SG_ BATT_sohcMod_10 : 0|16@1+ (0.01,0) [0|100] "%" Battery,Host
 SG_ BATT_socMod_10 : 16|16@1+ (0.01,0) [0|102.3] "%" Battery,Host
 SG_ BATT_socLimiting_10 : 32|16@1+ (0.01,0) [0|102.3] "%" Battery,Host
 SG_ BATT_idSOCLimiting_10 : 48|4@1+ (1,0) [0|14] "" Battery,Host

BO_ 2215903243 BATT_modSOC_11: 7 Battery
 SG_ BATT_sohcMod_11 : 0|16@1+ (0.01,0) [0|100] "%" Battery,Host
 SG_ BATT_socMod_11 : 16|16@1+ (0.01,0) [0|102.3] "%" Battery,Host
 SG_ BATT_socLimiting_11 : 32|16@1+ (0.01,0) [0|102.3] "%" Battery,Host
 SG_ BATT_idSOCLimiting_11 : 48|4@1+ (1,0) [0|14] "" Battery,Host

BO_ 2219376640 BATT_modChgLimits_0: 8 Battery
 SG_ BATT_vModChgLimit_0 : 48|16@1+ (0.005,0) [0|70] "V" Host,Battery
 SG_ BATT_iModChgLimitInst_0 : 32|16@1+ (0.01,0) [0|75] "A" Host,Battery
 SG_ BATT_iModChgLimit10s_0 : 0|16@1+ (0.01,0) [0|75] "A" Host,Battery
 SG_ BATT_iModChgLimitCont_0 : 16|16@1+ (0.01,0) [0|60] "A" Battery,Host

BO_ 2219376641 BATT_modChgLimits_1: 8 Battery
 SG_ BATT_vModChgLimit_1 : 48|16@1+ (0.005,0) [0|70] "V" Host,Battery
 SG_ BATT_iModChgLimitInst_1 : 32|16@1+ (0.01,0) [0|75] "A" Host,Battery
 SG_ BATT_iModChgLimit10s_1 : 0|16@1+ (0.01,0) [0|75] "A" Host,Battery
 SG_ BATT_iModChgLimitCont_1 : 16|16@1+ (0.01,0) [0|60] "A" Battery,Host

BO_ 2219376642 BATT_modChgLimits_2: 8 Battery
 SG_ BATT_vModChgLimit_2 : 48|16@1+ (0.005,0) [0|70] "V" Host,Battery
 SG_ BATT_iModChgLimitInst_2 : 32|16@1+ (0.01,0) [0|75] "A" Host,Battery
 SG_ BATT_iModChgLimit10s_2 : 0|16@1+ (0.01,0) [0|75] "A" Host,Battery
 SG_ BATT_iModChgLimitCont_2 : 16|16@1+ (0.01,0) [0|60] "A" Battery,Host

BO_ 2219376643 BATT_modChgLimits_3: 8 Battery
 SG_ BATT_vModChgLimit_3 : 48|16@1+ (0.005,0) [0|70] "V" Host,Battery
 SG_ BATT_iModChgLimitInst_3 : 32|16@1+ (0.01,0) [0|75] "A" Host,Battery
 SG_ BATT_iModChgLimit10s_3 : 0|16@1+ (0.01,0) [0|75] "A" Host,Battery
 SG_ BATT_iModChgLimitCont_3 : 16|16@1+ (0.01,0) [0|60] "A" Battery,Host

BO_ 2219376644 BATT_modChgLimits_4: 8 Battery
 SG_ BATT_vModChgLimit_4 : 48|16@1+ (0.005,0) [0|70] "V" Host,Battery
 SG_ BATT_iModChgLimitInst_4 : 32|16@1+ (0.01,0) [0|75] "A" Host,Battery
 SG_ BATT_iModChgLimit10s_4 : 0|16@1+ (0.01,0) [0|75] "A" Host,Battery
 SG_ BATT_iModChgLimitCont_4 : 16|16@1+ (0.01,0) [0|60] "A" Battery,Host

BO_ 2219376645 BATT_modChgLimits_5: 8 Battery
 SG_ BATT_vModChgLimit_5 : 48|16@1+ (0.005,0) [0|70] "V" Host,Battery
 SG_ BATT_iModChgLimitInst_5 : 32|16@1+ (0.01,0) [0|75] "A" Host,Battery
 SG_ BATT_iModChgLimit10s_5 : 0|16@1+ (0.01,0) [0|75] "A" Host,Battery
 SG_ BATT_iModChgLimitCont_5 : 16|16@1+ (0.01,0) [0|60] "A" Battery,Host

BO_ 2219376646 BATT_modChgLimits_6: 8 Battery
 SG_ BATT_vModChgLimit_6 : 48|16@1+ (0.005,0) [0|70] "V" Host,Battery
 SG_ BATT_iModChgLimitInst_6 : 32|16@1+ (0.01,0) [0|75] "A" Host,Battery
 SG_ BATT_iModChgLimit10s_6 : 0|16@1+ (0.01,0) [0|75] "A" Host,Battery
 SG_ BATT_iModChgLimitCont_6 : 16|16@1+ (0.01,0) [0|60] "A" Battery,Host

BO_ 2219376647 BATT_modChgLimits_7: 8 Battery
 SG_ BATT_vModChgLimit_7 : 48|16@1+ (0.005,0) [0|70] "V" Host,Battery
 SG_ BATT_iModChgLimitInst_7 : 32|16@1+ (0.01,0) [0|75] "A" Host,Battery
 SG_ BATT_iModChgLimit10s_7 : 0|16@1+ (0.01,0) [0|75] "A" Host,Battery
 SG_ BATT_iModChgLimitCont_7 : 16|16@1+ (0.01,0) [0|60] "A" Battery,Host

BO_ 2219376648 BATT_modChgLimits_8: 8 Battery
 SG_ BATT_vModChgLimit_8 : 48|16@1+ (0.005,0) [0|70] "V" Host,Battery
 SG_ BATT_iModChgLimitInst_8 : 32|16@1+ (0.01,0) [0|75] "A" Host,Battery
 SG_ BATT_iModChgLimit10s_8 : 0|16@1+ (0.01,0) [0|75] "A" Host,Battery
 SG_ BATT_iModChgLimitCont_8 : 16|16@1+ (0.01,0) [0|60] "A" Battery,Host

BO_ 2219376649 BATT_modChgLimits_9: 8 Battery
 SG_ BATT_vModChgLimit_9 : 48|16@1+ (0.005,0) [0|70] "V" Host,Battery
 SG_ BATT_iModChgLimitInst_9 : 32|16@1+ (0.01,0) [0|75] "A" Host,Battery
 SG_ BATT_iModChgLimit10s_9 : 0|16@1+ (0.01,0) [0|75] "A" Host,Battery
 SG_ BATT_iModChgLimitCont_9 : 16|16@1+ (0.01,0) [0|60] "A" Battery,Host

BO_ 2219376650 BATT_modChgLimits_10: 8 Battery
 SG_ BATT_vModChgLimit_10 : 48|16@1+ (0.005,0) [0|70] "V" Host,Battery
 SG_ BATT_iModChgLimitInst_10 : 32|16@1+ (0.01,0) [0|75] "A" Host,Battery
 SG_ BATT_iModChgLimit10s_10 : 0|16@1+ (0.01,0) [0|75] "A" Host,Battery
 SG_ BATT_iModChgLimitCont_10 : 16|16@1+ (0.01,0) [0|60] "A" Battery,Host

BO_ 2219376651 BATT_modChgLimits_11: 8 Battery
 SG_ BATT_vModChgLimit_11 : 48|16@1+ (0.005,0) [0|70] "V" Host,Battery
 SG_ BATT_iModChgLimitInst_11 : 32|16@1+ (0.01,0) [0|75] "A" Host,Battery
 SG_ BATT_iModChgLimit10s_11 : 0|16@1+ (0.01,0) [0|75] "A" Host,Battery
 SG_ BATT_iModChgLimitCont_11 : 16|16@1+ (0.01,0) [0|60] "A" Battery,Host

BO_ 2219573248 BATT_modDchLimits_0: 8 Battery
 SG_ BATT_vModDchLimit_0 : 48|16@1+ (0.005,0) [0|70] "V" Host,Battery
 SG_ BATT_iModDchLimitInst_0 : 32|16@1- (0.01,0) [-200|1] "A" Host,Battery
 SG_ BATT_iModDchLimit10s_0 : 16|16@1- (0.01,0) [-200|1] "A" Host,Battery
 SG_ BATT_iModDchLimitCont_0 : 0|16@1- (0.01,0) [-120|1] "A" Host,Battery

BO_ 2219573249 BATT_modDchLimits_1: 8 Battery
 SG_ BATT_vModDchLimit_1 : 48|16@1+ (0.005,0) [0|70] "V" Host,Battery
 SG_ BATT_iModDchLimitInst_1 : 32|16@1- (0.01,0) [-200|1] "A" Host,Battery
 SG_ BATT_iModDchLimit10s_1 : 16|16@1- (0.01,0) [-200|1] "A" Host,Battery
 SG_ BATT_iModDchLimitCont_1 : 0|16@1- (0.01,0) [-120|1] "A" Host,Battery

BO_ 2219573250 BATT_modDchLimits_2: 8 Battery
 SG_ BATT_vModDchLimit_2 : 48|16@1+ (0.005,0) [0|70] "V" Host,Battery
 SG_ BATT_iModDchLimitInst_2 : 32|16@1- (0.01,0) [-200|1] "A" Host,Battery
 SG_ BATT_iModDchLimit10s_2 : 16|16@1- (0.01,0) [-200|1] "A" Host,Battery
 SG_ BATT_iModDchLimitCont_2 : 0|16@1- (0.01,0) [-120|1] "A" Host,Battery

BO_ 2219573251 BATT_modDchLimits_3: 8 Battery
 SG_ BATT_vModDchLimit_3 : 48|16@1+ (0.005,0) [0|70] "V" Host,Battery
 SG_ BATT_iModDchLimitInst_3 : 32|16@1- (0.01,0) [-200|1] "A" Host,Battery
 SG_ BATT_iModDchLimit10s_3 : 16|16@1- (0.01,0) [-200|1] "A" Host,Battery
 SG_ BATT_iModDchLimitCont_3 : 0|16@1- (0.01,0) [-120|1] "A" Host,Battery

BO_ 2219573252 BATT_modDchLimits_4: 8 Battery
 SG_ BATT_vModDchLimit_4 : 48|16@1+ (0.005,0) [0|70] "V" Host,Battery
 SG_ BATT_iModDchLimitInst_4 : 32|16@1- (0.01,0) [-200|1] "A" Host,Battery
 SG_ BATT_iModDchLimit10s_4 : 16|16@1- (0.01,0) [-200|1] "A" Host,Battery
 SG_ BATT_iModDchLimitCont_4 : 0|16@1- (0.01,0) [-120|1] "A" Host,Battery

BO_ 2219573253 BATT_modDchLimits_5: 8 Battery
 SG_ BATT_vModDchLimit_5 : 48|16@1+ (0.005,0) [0|70] "V" Host,Battery
 SG_ BATT_iModDchLimitInst_5 : 32|16@1- (0.01,0) [-200|1] "A" Host,Battery
 SG_ BATT_iModDchLimit10s_5 : 16|16@1- (0.01,0) [-200|1] "A" Host,Battery
 SG_ BATT_iModDchLimitCont_5 : 0|16@1- (0.01,0) [-120|1] "A" Host,Battery

BO_ 2219573254 BATT_modDchLimits_6: 8 Battery
 SG_ BATT_vModDchLimit_6 : 48|16@1+ (0.005,0) [0|70] "V" Host,Battery
 SG_ BATT_iModDchLimitInst_6 : 32|16@1- (0.01,0) [-200|1] "A" Host,Battery
 SG_ BATT_iModDchLimit10s_6 : 16|16@1- (0.01,0) [-200|1] "A" Host,Battery
 SG_ BATT_iModDchLimitCont_6 : 0|16@1- (0.01,0) [-120|1] "A" Host,Battery

BO_ 2219573255 BATT_modDchLimits_7: 8 Battery
 SG_ BATT_vModDchLimit_7 : 48|16@1+ (0.005,0) [0|70] "V" Host,Battery
 SG_ BATT_iModDchLimitInst_7 : 32|16@1- (0.01,0) [-200|1] "A" Host,Battery
 SG_ BATT_iModDchLimit10s_7 : 16|16@1- (0.01,0) [-200|1] "A" Host,Battery
 SG_ BATT_iModDchLimitCont_7 : 0|16@1- (0.01,0) [-120|1] "A" Host,Battery

BO_ 2219573256 BATT_modDchLimits_8: 8 Battery
 SG_ BATT_vModDchLimit_8 : 48|16@1+ (0.005,0) [0|70] "V" Host,Battery
 SG_ BATT_iModDchLimitInst_8 : 32|16@1- (0.01,0) [-200|1] "A" Host,Battery
 SG_ BATT_iModDchLimit10s_8 : 16|16@1- (0.01,0) [-200|1] "A" Host,Battery
 SG_ BATT_iModDchLimitCont_8 : 0|16@1- (0.01,0) [-120|1] "A" Host,Battery

BO_ 2219573257 BATT_modDchLimits_9: 8 Battery
 SG_ BATT_vModDchLimit_9 : 48|16@1+ (0.005,0) [0|70] "V" Host,Battery
 SG_ BATT_iModDchLimitInst_9 : 32|16@1- (0.01,0) [-200|1] "A" Host,Battery
 SG_ BATT_iModDchLimit10s_9 : 16|16@1- (0.01,0) [-200|1] "A" Host,Battery
 SG_ BATT_iModDchLimitCont_9 : 0|16@1- (0.01,0) [-120|1] "A" Host,Battery

BO_ 2219573258 BATT_modDchLimits_10: 8 Battery
 SG_ BATT_vModDchLimit_10 : 48|16@1+ (0.005,0) [0|70] "V" Host,Battery
 SG_ BATT_iModDchLimitInst_10 : 32|16@1- (0.01,0) [-200|1] "A" Host,Battery
 SG_ BATT_iModDchLimit10s_10 : 16|16@1- (0.01,0) [-200|1] "A" Host,Battery
 SG_ BATT_iModDchLimitCont_10 : 0|16@1- (0.01,0) [-120|1] "A" Host,Battery

BO_ 2219573259 BATT_modDchLimits_11: 8 Battery
 SG_ BATT_vModDchLimit_11 : 48|16@1+ (0.005,0) [0|70] "V" Host,Battery
 SG_ BATT_iModDchLimitInst_11 : 32|16@1- (0.01,0) [-200|1] "A" Host,Battery
 SG_ BATT_iModDchLimit10s_11 : 16|16@1- (0.01,0) [-200|1] "A" Host,Battery
 SG_ BATT_iModDchLimitCont_11 : 0|16@1- (0.01,0) [-120|1] "A" Host,Battery

BO_ 2219835392 BATT_modPwrAvailable_0: 4 Battery
 SG_ BATT_pwrModDchLimit_0 : 16|16@1+ (0.01,0) [0|655.35] "kW" Host,Battery
 SG_ BATT_pwrModChgLimit_0 : 0|16@1+ (0.01,0) [0|655.35] "kW" Host,Battery

BO_ 2219835393 BATT_modPwrAvailable_1: 4 Battery
 SG_ BATT_pwrModDchLimit_1 : 16|16@1+ (0.01,0) [0|655.35] "kW" Host,Battery
 SG_ BATT_pwrModChgLimit_1 : 0|16@1+ (0.01,0) [0|655.35] "kW" Host,Battery

BO_ 2219835394 BATT_modPwrAvailable_2: 4 Battery
 SG_ BATT_pwrModDchLimit_2 : 16|16@1+ (0.01,0) [0|655.35] "kW" Host,Battery
 SG_ BATT_pwrModChgLimit_2 : 0|16@1+ (0.01,0) [0|655.35] "kW" Host,Battery

BO_ 2219835395 BATT_modPwrAvailable_3: 4 Battery
 SG_ BATT_pwrModDchLimit_3 : 16|16@1+ (0.01,0) [0|655.35] "kW" Host,Battery
 SG_ BATT_pwrModChgLimit_3 : 0|16@1+ (0.01,0) [0|655.35] "kW" Host,Battery

BO_ 2219835396 BATT_modPwrAvailable_4: 4 Battery
 SG_ BATT_pwrModDchLimit_4 : 16|16@1+ (0.01,0) [0|655.35] "kW" Host,Battery
 SG_ BATT_pwrModChgLimit_4 : 0|16@1+ (0.01,0) [0|655.35] "kW" Host,Battery

BO_ 2219835397 BATT_modPwrAvailable_5: 4 Battery
 SG_ BATT_pwrModDchLimit_5 : 16|16@1+ (0.01,0) [0|655.35] "kW" Host,Battery
 SG_ BATT_pwrModChgLimit_5 : 0|16@1+ (0.01,0) [0|655.35] "kW" Host,Battery

BO_ 2219835398 BATT_modPwrAvailable_6: 4 Battery
 SG_ BATT_pwrModDchLimit_6 : 16|16@1+ (0.01,0) [0|655.35] "kW" Host,Battery
 SG_ BATT_pwrModChgLimit_6 : 0|16@1+ (0.01,0) [0|655.35] "kW" Host,Battery

BO_ 2219835399 BATT_modPwrAvailable_7: 4 Battery
 SG_ BATT_pwrModDchLimit_7 : 16|16@1+ (0.01,0) [0|655.35] "kW" Host,Battery
 SG_ BATT_pwrModChgLimit_7 : 0|16@1+ (0.01,0) [0|655.35] "kW" Host,Battery

BO_ 2219835400 BATT_modPwrAvailable_8: 4 Battery
 SG_ BATT_pwrModDchLimit_8 : 16|16@1+ (0.01,0) [0|655.35] "kW" Host,Battery
 SG_ BATT_pwrModChgLimit_8 : 0|16@1+ (0.01,0) [0|655.35] "kW" Host,Battery

BO_ 2219835401 BATT_modPwrAvailable_9: 4 Battery
 SG_ BATT_pwrModDchLimit_9 : 16|16@1+ (0.01,0) [0|655.35] "kW" Host,Battery
 SG_ BATT_pwrModChgLimit_9 : 0|16@1+ (0.01,0) [0|655.35] "kW" Host,Battery

BO_ 2219835402 BATT_modPwrAvailable_10: 4 Battery
 SG_ BATT_pwrModDchLimit_10 : 16|16@1+ (0.01,0) [0|655.35] "kW" Host,Battery
 SG_ BATT_pwrModChgLimit_10 : 0|16@1+ (0.01,0) [0|655.35] "kW" Host,Battery

BO_ 2219835403 BATT_modPwrAvailable_11: 4 Battery
 SG_ BATT_pwrModDchLimit_11 : 16|16@1+ (0.01,0) [0|655.35] "kW" Host,Battery
 SG_ BATT_pwrModChgLimit_11 : 0|16@1+ (0.01,0) [0|655.35] "kW" Host,Battery

BO_ 2221146112 BATT_modTemperaturesA_0: 8 Battery
 SG_ BATT_tModule2_0 : 32|16@1- (0.1,0) [-40|125] "deg C" Host
 SG_ BATT_tModule1_0 : 16|16@1- (0.1,0) [-40|125] "deg C" Host
 SG_ BATT_tAmbient_0 : 0|16@1- (0.1,0) [-40|125] "deg C" Host

BO_ 2221146113 BATT_modTemperaturesA_1: 8 Battery
 SG_ BATT_tModule2_1 : 32|16@1- (0.1,0) [-40|125] "deg C" Host
 SG_ BATT_tModule1_1 : 16|16@1- (0.1,0) [-40|125] "deg C" Host
 SG_ BATT_tAmbient_1 : 0|16@1- (0.1,0) [-40|125] "deg C" Host

BO_ 2221146114 BATT_modTemperaturesA_2: 8 Battery
 SG_ BATT_tModule2_2 : 32|16@1- (0.1,0) [-40|125] "deg C" Host
 SG_ BATT_tModule1_2 : 16|16@1- (0.1,0) [-40|125] "deg C" Host
 SG_ BATT_tAmbient_2 : 0|16@1- (0.1,0) [-40|125] "deg C" Host

BO_ 2221146115 BATT_modTemperaturesA_3: 8 Battery
 SG_ BATT_tModule2_3 : 32|16@1- (0.1,0) [-40|125] "deg C" Host
 SG_ BATT_tModule1_3 : 16|16@1- (0.1,0) [-40|125] "deg C" Host
 SG_ BATT_tAmbient_3 : 0|16@1- (0.1,0) [-40|125] "deg C" Host

BO_ 2221146116 BATT_modTemperaturesA_4: 8 Battery
 SG_ BATT_tModule2_4 : 32|16@1- (0.1,0) [-40|125] "deg C" Host
 SG_ BATT_tModule1_4 : 16|16@1- (0.1,0) [-40|125] "deg C" Host
 SG_ BATT_tAmbient_4 : 0|16@1- (0.1,0) [-40|125] "deg C" Host

BO_ 2221146117 BATT_modTemperaturesA_5: 8 Battery
 SG_ BATT_tModule2_5 : 32|16@1- (0.1,0) [-40|125] "deg C" Host
 SG_ BATT_tModule1_5 : 16|16@1- (0.1,0) [-40|125] "deg C" Host
 SG_ BATT_tAmbient_5 : 0|16@1- (0.1,0) [-40|125] "deg C" Host

BO_ 2221146118 BATT_modTemperaturesA_6: 8 Battery
 SG_ BATT_tModule2_6 : 32|16@1- (0.1,0) [-40|125] "deg C" Host
 SG_ BATT_tModule1_6 : 16|16@1- (0.1,0) [-40|125] "deg C" Host
 SG_ BATT_tAmbient_6 : 0|16@1- (0.1,0) [-40|125] "deg C" Host

BO_ 2221146119 BATT_modTemperaturesA_7: 8 Battery
 SG_ BATT_tModule2_7 : 32|16@1- (0.1,0) [-40|125] "deg C" Host
 SG_ BATT_tModule1_7 : 16|16@1- (0.1,0) [-40|125] "deg C" Host
 SG_ BATT_tAmbient_7 : 0|16@1- (0.1,0) [-40|125] "deg C" Host

BO_ 2221146120 BATT_modTemperaturesA_8: 8 Battery
 SG_ BATT_tModule2_8 : 32|16@1- (0.1,0) [-40|125] "deg C" Host
 SG_ BATT_tModule1_8 : 16|16@1- (0.1,0) [-40|125] "deg C" Host
 SG_ BATT_tAmbient_8 : 0|16@1- (0.1,0) [-40|125] "deg C" Host

BO_ 2221146121 BATT_modTemperaturesA_9: 8 Battery
 SG_ BATT_tModule2_9 : 32|16@1- (0.1,0) [-40|125] "deg C" Host
 SG_ BATT_tModule1_9 : 16|16@1- (0.1,0) [-40|125] "deg C" Host
 SG_ BATT_tAmbient_9 : 0|16@1- (0.1,0) [-40|125] "deg C" Host

BO_ 2221146122 BATT_modTemperaturesA_10: 8 Battery
 SG_ BATT_tModule2_10 : 32|16@1- (0.1,0) [-40|125] "deg C" Host
 SG_ BATT_tModule1_10 : 16|16@1- (0.1,0) [-40|125] "deg C" Host
 SG_ BATT_tAmbient_10 : 0|16@1- (0.1,0) [-40|125] "deg C" Host

BO_ 2221146123 BATT_modTemperaturesA_11: 8 Battery
 SG_ BATT_tModule2_11 : 32|16@1- (0.1,0) [-40|125] "deg C" Host
 SG_ BATT_tModule1_11 : 16|16@1- (0.1,0) [-40|125] "deg C" Host
 SG_ BATT_tAmbient_11 : 0|16@1- (0.1,0) [-40|125] "deg C" Host

BO_ 2222981120 BATT_modTemperaturesB_0: 8 Battery
 SG_ BATT_tShunt_0 : 48|16@1- (0.1,0) [-40|125] "deg C" Host
 SG_ BATT_tFET_0 : 32|16@1- (0.1,0) [-40|125] "deg C" Host

BO_ 2222981121 BATT_modTemperaturesB_1: 8 Battery
 SG_ BATT_tShunt_1 : 48|16@1- (0.1,0) [-40|125] "deg C" Host
 SG_ BATT_tFET_1 : 32|16@1- (0.1,0) [-40|125] "deg C" Host

BO_ 2222981122 BATT_modTemperaturesB_2: 8 Battery
 SG_ BATT_tShunt_2 : 48|16@1- (0.1,0) [-40|125] "deg C" Host
 SG_ BATT_tFET_2 : 32|16@1- (0.1,0) [-40|125] "deg C" Host

BO_ 2222981123 BATT_modTemperaturesB_3: 8 Battery
 SG_ BATT_tShunt_3 : 48|16@1- (0.1,0) [-40|125] "deg C" Host
 SG_ BATT_tFET_3 : 32|16@1- (0.1,0) [-40|125] "deg C" Host

BO_ 2222981124 BATT_modTemperaturesB_4: 8 Battery
 SG_ BATT_tShunt_4 : 48|16@1- (0.1,0) [-40|125] "deg C" Host
 SG_ BATT_tFET_4 : 32|16@1- (0.1,0) [-40|125] "deg C" Host

BO_ 2222981125 BATT_modTemperaturesB_5: 8 Battery
 SG_ BATT_tShunt_5 : 48|16@1- (0.1,0) [-40|125] "deg C" Host
 SG_ BATT_tFET_5 : 32|16@1- (0.1,0) [-40|125] "deg C" Host

BO_ 2222981126 BATT_modTemperaturesB_6: 8 Battery
 SG_ BATT_tShunt_6 : 48|16@1- (0.1,0) [-40|125] "deg C" Host
 SG_ BATT_tFET_6 : 32|16@1- (0.1,0) [-40|125] "deg C" Host

BO_ 2222981127 BATT_modTemperaturesB_7: 8 Battery
 SG_ BATT_tShunt_7 : 48|16@1- (0.1,0) [-40|125] "deg C" Host
 SG_ BATT_tFET_7 : 32|16@1- (0.1,0) [-40|125] "deg C" Host

BO_ 2222981128 BATT_modTemperaturesB_8: 8 Battery
 SG_ BATT_tShunt_8 : 48|16@1- (0.1,0) [-40|125] "deg C" Host
 SG_ BATT_tFET_8 : 32|16@1- (0.1,0) [-40|125] "deg C" Host

BO_ 2222981129 BATT_modTemperaturesB_9: 8 Battery
 SG_ BATT_tShunt_9 : 48|16@1- (0.1,0) [-40|125] "deg C" Host
 SG_ BATT_tFET_9 : 32|16@1- (0.1,0) [-40|125] "deg C" Host

BO_ 2222981130 BATT_modTemperaturesB_10: 8 Battery
 SG_ BATT_tShunt_10 : 48|16@1- (0.1,0) [-40|125] "deg C" Host
 SG_ BATT_tFET_10 : 32|16@1- (0.1,0) [-40|125] "deg C" Host

BO_ 2222981131 BATT_modTemperaturesB_11: 8 Battery
 SG_ BATT_tShunt_11 : 48|16@1- (0.1,0) [-40|125] "deg C" Host
 SG_ BATT_tFET_11 : 32|16@1- (0.1,0) [-40|125] "deg C" Host

BO_ 2224029696 BATT_modLoadStatus_0: 6 Battery
 SG_ BATT_resMod_0 : 32|16@1+ (0.01,0) [0|655.35] "mOhms" Host
 SG_ BATT_voirMod_0 : 16|16@1+ (0.01,0) [0|70] "V" Host
 SG_ BATT_vModLoad_0 : 0|16@1+ (0.01,0) [0|70] "V" Battery,Host

BO_ 2224029697 BATT_modLoadStatus_1: 6 Battery
 SG_ BATT_resMod_1 : 32|16@1+ (0.01,0) [0|655.35] "mOhms" Host
 SG_ BATT_voirMod_1 : 16|16@1+ (0.01,0) [0|70] "V" Host
 SG_ BATT_vModLoad_1 : 0|16@1+ (0.01,0) [0|70] "V" Battery,Host

BO_ 2224029698 BATT_modLoadStatus_2: 6 Battery
 SG_ BATT_resMod_2 : 32|16@1+ (0.01,0) [0|655.35] "mOhms" Host
 SG_ BATT_voirMod_2 : 16|16@1+ (0.01,0) [0|70] "V" Host
 SG_ BATT_vModLoad_2 : 0|16@1+ (0.01,0) [0|70] "V" Battery,Host

BO_ 2224029699 BATT_modLoadStatus_3: 6 Battery
 SG_ BATT_resMod_3 : 32|16@1+ (0.01,0) [0|655.35] "mOhms" Host
 SG_ BATT_voirMod_3 : 16|16@1+ (0.01,0) [0|70] "V" Host
 SG_ BATT_vModLoad_3 : 0|16@1+ (0.01,0) [0|70] "V" Battery,Host

BO_ 2224029700 BATT_modLoadStatus_4: 6 Battery
 SG_ BATT_resMod_4 : 32|16@1+ (0.01,0) [0|655.35] "mOhms" Host
 SG_ BATT_voirMod_4 : 16|16@1+ (0.01,0) [0|70] "V" Host
 SG_ BATT_vModLoad_4 : 0|16@1+ (0.01,0) [0|70] "V" Battery,Host

BO_ 2224029701 BATT_modLoadStatus_5: 6 Battery
 SG_ BATT_resMod_5 : 32|16@1+ (0.01,0) [0|655.35] "mOhms" Host
 SG_ BATT_voirMod_5 : 16|16@1+ (0.01,0) [0|70] "V" Host
 SG_ BATT_vModLoad_5 : 0|16@1+ (0.01,0) [0|70] "V" Battery,Host

BO_ 2224029702 BATT_modLoadStatus_6: 6 Battery
 SG_ BATT_resMod_6 : 32|16@1+ (0.01,0) [0|655.35] "mOhms" Host
 SG_ BATT_voirMod_6 : 16|16@1+ (0.01,0) [0|70] "V" Host
 SG_ BATT_vModLoad_6 : 0|16@1+ (0.01,0) [0|70] "V" Battery,Host

BO_ 2224029703 BATT_modLoadStatus_7: 6 Battery
 SG_ BATT_resMod_7 : 32|16@1+ (0.01,0) [0|655.35] "mOhms" Host
 SG_ BATT_voirMod_7 : 16|16@1+ (0.01,0) [0|70] "V" Host
 SG_ BATT_vModLoad_7 : 0|16@1+ (0.01,0) [0|70] "V" Battery,Host

BO_ 2224029704 BATT_modLoadStatus_8: 6 Battery
 SG_ BATT_resMod_8 : 32|16@1+ (0.01,0) [0|655.35] "mOhms" Host
 SG_ BATT_voirMod_8 : 16|16@1+ (0.01,0) [0|70] "V" Host
 SG_ BATT_vModLoad_8 : 0|16@1+ (0.01,0) [0|70] "V" Battery,Host

BO_ 2224029705 BATT_modLoadStatus_9: 6 Battery
 SG_ BATT_resMod_9 : 32|16@1+ (0.01,0) [0|655.35] "mOhms" Host
 SG_ BATT_voirMod_9 : 16|16@1+ (0.01,0) [0|70] "V" Host
 SG_ BATT_vModLoad_9 : 0|16@1+ (0.01,0) [0|70] "V" Battery,Host

BO_ 2224029706 BATT_modLoadStatus_10: 6 Battery
 SG_ BATT_resMod_10 : 32|16@1+ (0.01,0) [0|655.35] "mOhms" Host
 SG_ BATT_voirMod_10 : 16|16@1+ (0.01,0) [0|70] "V" Host
 SG_ BATT_vModLoad_10 : 0|16@1+ (0.01,0) [0|70] "V" Battery,Host

BO_ 2224029707 BATT_modLoadStatus_11: 6 Battery
 SG_ BATT_resMod_11 : 32|16@1+ (0.01,0) [0|655.35] "mOhms" Host
 SG_ BATT_voirMod_11 : 16|16@1+ (0.01,0) [0|70] "V" Host
 SG_ BATT_vModLoad_11 : 0|16@1+ (0.01,0) [0|70] "V" Battery,Host

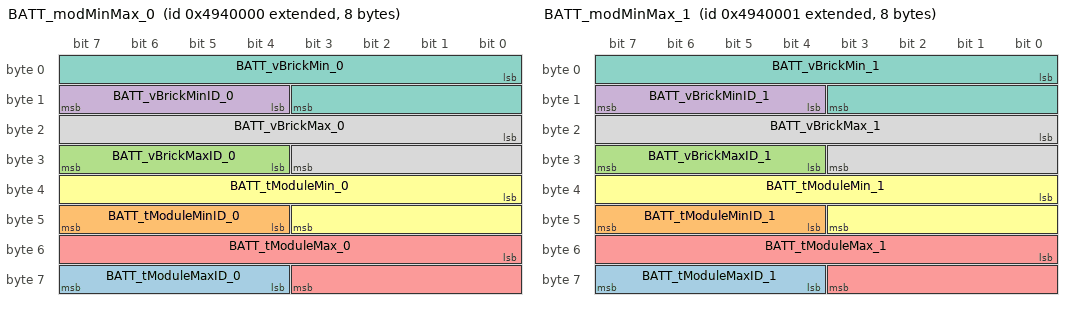
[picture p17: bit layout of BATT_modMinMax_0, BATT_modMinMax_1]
BO_ 2224291840 BATT_modMinMax_0: 8 Battery
 SG_ BATT_tModuleMaxID_0 : 60|4@1+ (1,0) [0|14] "" Battery,Host
 SG_ BATT_tModuleMinID_0 : 44|4@1+ (1,0) [0|14] "" Battery,Host
 SG_ BATT_vBrickMaxID_0 : 28|4@1+ (1,0) [0|14] "" Battery,Host
 SG_ BATT_vBrickMinID_0 : 12|4@1+ (1,0) [0|14] "" Battery,Host
 SG_ BATT_tModuleMax_0 : 48|12@1- (0.1,0) [-40|125] "deg C" Battery,Host
 SG_ BATT_tModuleMin_0 : 32|12@1- (0.1,0) [-40|125] "deg C" Battery,Host
 SG_ BATT_vBrickMin_0 : 0|12@1+ (0.002,0) [0|4.98066] "V" Battery,Host
 SG_ BATT_vBrickMax_0 : 16|12@1+ (0.002,0) [0|4.98066] "V" Battery,Host

BO_ 2224291841 BATT_modMinMax_1: 8 Battery
 SG_ BATT_tModuleMaxID_1 : 60|4@1+ (1,0) [0|14] "" Battery,Host
 SG_ BATT_tModuleMinID_1 : 44|4@1+ (1,0) [0|14] "" Battery,Host
 SG_ BATT_vBrickMaxID_1 : 28|4@1+ (1,0) [0|14] "" Battery,Host
 SG_ BATT_vBrickMinID_1 : 12|4@1+ (1,0) [0|14] "" Battery,Host
 SG_ BATT_tModuleMax_1 : 48|12@1- (0.1,0) [-40|125] "deg C" Battery,Host
 SG_ BATT_tModuleMin_1 : 32|12@1- (0.1,0) [-40|125] "deg C" Battery,Host
 SG_ BATT_vBrickMin_1 : 0|12@1+ (0.002,0) [0|4.98066] "V" Battery,Host
 SG_ BATT_vBrickMax_1 : 16|12@1+ (0.002,0) [0|4.98066] "V" Battery,Host

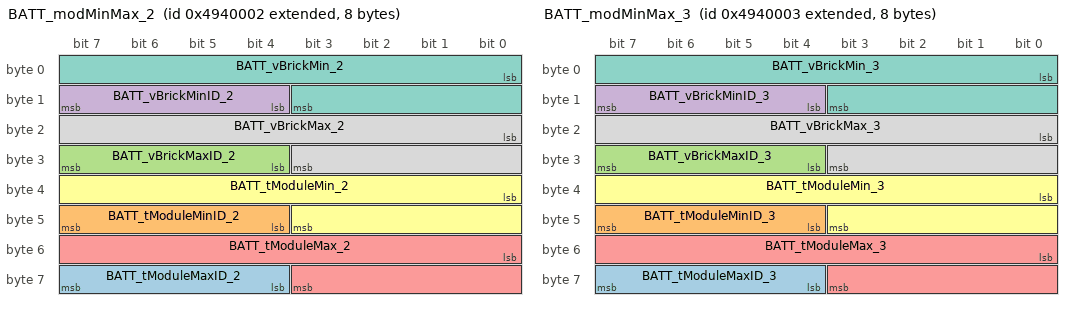
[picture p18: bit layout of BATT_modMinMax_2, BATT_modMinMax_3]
BO_ 2224291842 BATT_modMinMax_2: 8 Battery
 SG_ BATT_tModuleMaxID_2 : 60|4@1+ (1,0) [0|14] "" Battery,Host
 SG_ BATT_tModuleMinID_2 : 44|4@1+ (1,0) [0|14] "" Battery,Host
 SG_ BATT_vBrickMaxID_2 : 28|4@1+ (1,0) [0|14] "" Battery,Host
 SG_ BATT_vBrickMinID_2 : 12|4@1+ (1,0) [0|14] "" Battery,Host
 SG_ BATT_tModuleMax_2 : 48|12@1- (0.1,0) [-40|125] "deg C" Battery,Host
 SG_ BATT_tModuleMin_2 : 32|12@1- (0.1,0) [-40|125] "deg C" Battery,Host
 SG_ BATT_vBrickMin_2 : 0|12@1+ (0.002,0) [0|4.98066] "V" Battery,Host
 SG_ BATT_vBrickMax_2 : 16|12@1+ (0.002,0) [0|4.98066] "V" Battery,Host

BO_ 2224291843 BATT_modMinMax_3: 8 Battery
 SG_ BATT_tModuleMaxID_3 : 60|4@1+ (1,0) [0|14] "" Battery,Host
 SG_ BATT_tModuleMinID_3 : 44|4@1+ (1,0) [0|14] "" Battery,Host
 SG_ BATT_vBrickMaxID_3 : 28|4@1+ (1,0) [0|14] "" Battery,Host
 SG_ BATT_vBrickMinID_3 : 12|4@1+ (1,0) [0|14] "" Battery,Host
 SG_ BATT_tModuleMax_3 : 48|12@1- (0.1,0) [-40|125] "deg C" Battery,Host
 SG_ BATT_tModuleMin_3 : 32|12@1- (0.1,0) [-40|125] "deg C" Battery,Host
 SG_ BATT_vBrickMin_3 : 0|12@1+ (0.002,0) [0|4.98066] "V" Battery,Host
 SG_ BATT_vBrickMax_3 : 16|12@1+ (0.002,0) [0|4.98066] "V" Battery,Host

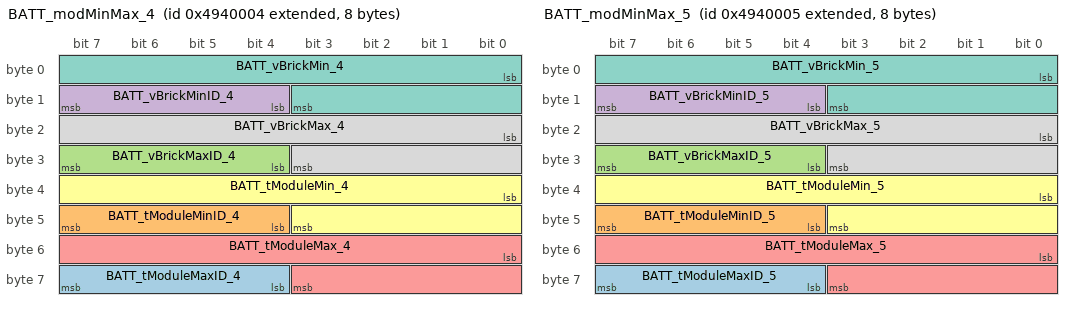
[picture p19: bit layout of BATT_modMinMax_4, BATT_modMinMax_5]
BO_ 2224291844 BATT_modMinMax_4: 8 Battery
 SG_ BATT_tModuleMaxID_4 : 60|4@1+ (1,0) [0|14] "" Battery,Host
 SG_ BATT_tModuleMinID_4 : 44|4@1+ (1,0) [0|14] "" Battery,Host
 SG_ BATT_vBrickMaxID_4 : 28|4@1+ (1,0) [0|14] "" Battery,Host
 SG_ BATT_vBrickMinID_4 : 12|4@1+ (1,0) [0|14] "" Battery,Host
 SG_ BATT_tModuleMax_4 : 48|12@1- (0.1,0) [-40|125] "deg C" Battery,Host
 SG_ BATT_tModuleMin_4 : 32|12@1- (0.1,0) [-40|125] "deg C" Battery,Host
 SG_ BATT_vBrickMin_4 : 0|12@1+ (0.002,0) [0|4.98066] "V" Battery,Host
 SG_ BATT_vBrickMax_4 : 16|12@1+ (0.002,0) [0|4.98066] "V" Battery,Host

BO_ 2224291845 BATT_modMinMax_5: 8 Battery
 SG_ BATT_tModuleMaxID_5 : 60|4@1+ (1,0) [0|14] "" Battery,Host
 SG_ BATT_tModuleMinID_5 : 44|4@1+ (1,0) [0|14] "" Battery,Host
 SG_ BATT_vBrickMaxID_5 : 28|4@1+ (1,0) [0|14] "" Battery,Host
 SG_ BATT_vBrickMinID_5 : 12|4@1+ (1,0) [0|14] "" Battery,Host
 SG_ BATT_tModuleMax_5 : 48|12@1- (0.1,0) [-40|125] "deg C" Battery,Host
 SG_ BATT_tModuleMin_5 : 32|12@1- (0.1,0) [-40|125] "deg C" Battery,Host
 SG_ BATT_vBrickMin_5 : 0|12@1+ (0.002,0) [0|4.98066] "V" Battery,Host
 SG_ BATT_vBrickMax_5 : 16|12@1+ (0.002,0) [0|4.98066] "V" Battery,Host

CM_ "Version 0.2.0";
CM_ SG_ 257 BATT_chargeError "0 - NO Charge Error
1 - Charge Error";
CM_ SG_ 257 BATT_chargerMode "Charge Mode (CC-CV)";
CM_ SG_ 257 BATT_chargerConnected "Charger connected status";
CM_ SG_ 257 BATT_chargeMode "Charge Mode (CC-CV)";
CM_ SG_ 257 BATT_chargeStatus "Charge Status";
CM_ SG_ 257 BATT_chargeEnable "0 - Request to disable charger if enabled
1 - Request to enable charger if disabled";
CM_ SG_ 257 BATT_chargingVoltage "Charger output voltage as measured by battery";
CM_ SG_ 257 BATT_chargingCurrent "Maximum charger output current as requested by battery";
CM_ SG_ 259 BATT_packAliveCntr "Battery Pack Alive Counter";
CM_ SG_ 259 BATT_packSpeakerInstanceID "Battery Pack Master Module Instance ID";
CM_ SG_ 259 BATT_packNumModsDataValid "Number of parallel modules with valid data";
CM_ SG_ 259 BATT_packNumModsOnNetwork "Number of modules on the network";
CM_ SG_ 259 BATT_packModComStatusOK_M "Bit mask for module communications status (1 = OK)";
CM_ SG_ 259 BATT_fetPackDsgWelded "Pack DSG FETs welded status";
CM_ SG_ 259 BATT_fetPackChgWelded "Pack CHG FETs welded status";
CM_ SG_ 259 BATT_packNumModsConfigured "Number of parallel modules configured for the pack";
CM_ SG_ 259 BATT_packNumModsOnHvBus "Number of modules on the HV bus";
CM_ SG_ 259 BATT_packState "Reports the current state of the battery";
CM_ BO_ 260 "Pack capacity";
CM_ SG_ 260 BATT_packRemainingCap_Ah "Remaining charge";
CM_ SG_ 260 BATT_packFullChargeCap_Ah "Estimated full charge capacity";
CM_ SG_ 261 BATT_packUserSOC "User state of charge for the battery pack";
CM_ SG_ 261 BATT_packSOC "State of Charge for the battery pack";
CM_ SG_ 273 CHRG_chargerEnabled "0 - Charger is disabled
1 - Charger is enabled";
CM_ SG_ 273 CHRG_chargingVoltage "Output voltage from charger";
CM_ SG_ 273 CHRG_chargingCurrent "Output current from charger";
CM_ BO_ 274 "Battery limits";
CM_ SG_ 274 BATT_vBusMax "Maximum voltage limit sent to inverter";
CM_ SG_ 274 BATT_iPackChgLimitInst "Current recharge limit in A";
CM_ SG_ 274 BATT_iPackChgLimit10s "Current recharge limit in A";
CM_ SG_ 274 BATT_iPackChgLimitCont "Current recharge limit in A";
CM_ BO_ 275 "Battery limits";
CM_ SG_ 275 BATT_vBusMin "Minimum voltage limit sent to inverter";
CM_ SG_ 275 BATT_iPackDchLimitInst "Current discharge limit in A";
CM_ SG_ 275 BATT_iPackDchLimit10s "Current discharge limit in A";
CM_ SG_ 275 BATT_iPackDchLimitCont "Current discharge limit in A";
CM_ BO_ 276 "Pack power available";
CM_ SG_ 276 BATT_pwrPackDchLimit "Pack discharge power available in kW";
CM_ SG_ 276 BATT_pwrPackChgLimit "Pack charge power available in kW";
CM_ SG_ 277 INV_voltage "Voltage measured by motor";
CM_ SG_ 277 INV_current "Current measured by motor";
CM_ SG_ 292 BATT_iPackFiltered "Filtered charge/discharge rate in ampere - positive for charge, negative for discharge.";
CM_ SG_ 292 BATT_vPack "Voltage of the pack";
CM_ SG_ 292 BATT_vPackLoad "Voltage measured across load";
CM_ SG_ 292 BATT_iPack "Pack current - combined current of all modules";
CM_ BO_ 293 "Battery min-max data";
CM_ SG_ 293 BATT_vPackModuleMinID "ID of minimum brick voltage ";
CM_ SG_ 293 BATT_vPackBrickMin "Minimum brick voltage ";
CM_ SG_ 293 BATT_vPackModuleMaxID "ID of maximum brick voltage ";
CM_ SG_ 293 BATT_vPackBrickMax "Maximum brick voltage ";
CM_ SG_ 293 BATT_tPackModuleMinID "ID of minimum Battery temperature ";
CM_ SG_ 293 BATT_tPackModuleMin "Minimum Battery temperature";
CM_ SG_ 293 BATT_tPackModuleMaxID "ID of maximum Battery temperature ";
CM_ SG_ 293 BATT_tPackModuleMax "Maximum Battery temperature";
CM_ BO_ 1282 "HOST battery request";
CM_ SG_ 1282 HOST_standbyModConnectRequest "Multi-module request standby module to join bus";
CM_ SG_ 1282 HOST_dbgInhibitContDrivePower "Debug Force Inhibit Allow Continuous Drive Power";
CM_ SG_ 1282 HOST_dbgInhibitRegen "Debug Force Inhibit Allow Regen";
CM_ SG_ 1282 HOST_dbgInhibitFullPower "Debug Force Inhibit Allow Full Power";
CM_ SG_ 1282 HOST_dbgResetEep "Debug reset EEPROM (1 = reset)";
CM_ SG_ 1282 HOST_stateRequest "State to be requested from battery by host";
CM_ SG_ 1296 HOST_boardIO_PROTECTION_CHECK "PROTECTION_CHECK output control state";
CM_ SG_ 1296 HOST_boardIO_BAL14 "BAL14 output control state";
CM_ SG_ 1296 HOST_boardIO_BAL13 "BAL13 output control state";
CM_ SG_ 1296 HOST_boardIO_BAL12 "BAL12 output control state";
CM_ SG_ 1296 HOST_boardIO_BAL11 "BAL11 output control state";
CM_ SG_ 1296 HOST_boardIO_BAL10 "BAL10 output control state";
CM_ SG_ 1296 HOST_boardIO_BAL09 "BAL08 output control state";
CM_ SG_ 1296 HOST_boardIO_BAL08 "BAL08 output control state";
CM_ SG_ 1296 HOST_boardIO_BAL07 "BAL07 output control state";
CM_ SG_ 1296 HOST_boardIO_BAL06 "BAL06 output control state";
CM_ SG_ 1296 HOST_boardIO_BAL05 "BAL05 output control state";
CM_ SG_ 1296 HOST_boardIO_BAL04 "BAL04 output control state";
CM_ SG_ 1296 HOST_boardIO_BAL03 "BAL03 output control state";
CM_ SG_ 1296 HOST_boardIO_BAL02 "BAL02 output control state";
CM_ SG_ 1296 HOST_boardIO_BAL01 "BAL01 output control state";
CM_ SG_ 1296 HOST_boardIO_LED4 "LED4 output control state";
CM_ SG_ 1296 HOST_boardIO_LED3 "LED3 output control state";
CM_ SG_ 1296 HOST_boardIO_LED2 "LED2 output control state";
CM_ SG_ 1296 HOST_boardIO_LED1 "LED1 output control state";
CM_ SG_ 1296 HOST_boardIO_PCHG "PCHG output control state";
CM_ SG_ 1296 HOST_boardIO_nFLT_CLR "nFLT_CLR output control state";
CM_ SG_ 1296 HOST_boardIO_DSG_EN "DSG_EN output control state";
CM_ SG_ 1296 HOST_boardIO_CHG_EN "CHG_EN output control state";
CM_ BO_ 1808 "Pack diagnostic status";
CM_ SG_ 1808 BATT_packModDrvStandbyConnOK_M "Bit mask for modules permitted to enter drive from standby during drive (1 = permit drive)";
CM_ SG_ 1808 BATT_packModChgStandbyConnOK_M "Bit mask for modules permitted to enter charge from standby during charge (1 = permit charge)";
CM_ SG_ 1808 BATT_packModDrvEntryConnOK_M "Bit mask for modules permitted to enter drive (1 = permit drive)";
CM_ SG_ 1808 BATT_packModChgEntryConnOK_M "Bit mask for modules permitted to enter charge (1 = permit charge)";
CM_ BO_ 1809 "Pack connected data diagnostic";
CM_ SG_ 1809 BATT_vPackConnBusBrickMin "Minimum brick voltage (connected modules only)";
CM_ SG_ 1809 BATT_vPackConnBusBrickMax "Maximum brick voltage (connected modules only)";
CM_ SG_ 1809 BATT_packConnBusSOC "State of Charge for the battery pack (connected modules only)";
CM_ BO_ 1904 "Debug Alert msg";
CM_ BO_ 1905 "Debug Alert msg";
CM_ BO_ 1906 "Debug Alert msg";
CM_ BO_ 1907 "Debug Alert msg";
CM_ BO_ 1908 "Debug Alert msg";
CM_ BO_ 1909 "Debug Alert msg";
CM_ BO_ 1910 "Debug Alert msg";
CM_ BO_ 1911 "Debug Alert msg";
CM_ BO_ 1912 "Debug Alert msg";
CM_ BO_ 1913 "Debug Alert msg";
CM_ BO_ 1914 "Debug Alert msg";
CM_ BO_ 1915 "Debug Alert msg";
CM_ SG_ 2147500032 NODE_ID_CLAIM_RND "Node ID Claim Number RND";
CM_ SG_ 2147500032 NODE_ID_CLAIM_SN "Node ID Claim Number SN";
CM_ BO_ 2147516416 "HOST node request";
CM_ SG_ 2147516416 HOST_securityKey "Security Key";
CM_ SG_ 2147516416 HOST_startNodeId "Start node ID claim flag";
CM_ BO_ 2147549184 "BATT battery request";
CM_ SG_ 2147549184 BATT_isIgnLo_Requested "0 if IGN_LO pin is NOT triggered
1 if IGN_LO pin is triggered ";
CM_ SG_ 2147549184 BATT_modReqCntr "BATT_modRequest msg counter";
CM_ SG_ 2147549184 BATT_nodeIdSerialNumber "Unique serial number";
CM_ SG_ 2147549184 BATT_startNodeId "Start node ID claim flag from BATT";
CM_ SG_ 2147549184 BATT_stateRequest "State to be requested from battery module";
CM_ BO_ 2176909312 "Balancing status";
CM_ SG_ 2176909312 BATT_timeBusQuietStandby_0 "Bus quiet standby time";
CM_ SG_ 2176909312 BATT_timeBusQuietSleep_0 "Bus quiet sleep time";
CM_ BO_ 2176909313 "Balancing status";
CM_ SG_ 2176909313 BATT_timeBusQuietStandby_1 "Bus quiet standby time";
CM_ SG_ 2176909313 BATT_timeBusQuietSleep_1 "Bus quiet sleep time";
CM_ BO_ 2176909314 "Balancing status";
CM_ SG_ 2176909314 BATT_timeBusQuietStandby_2 "Bus quiet standby time";
CM_ SG_ 2176909314 BATT_timeBusQuietSleep_2 "Bus quiet sleep time";
CM_ BO_ 2176909315 "Balancing status";
CM_ SG_ 2176909315 BATT_timeBusQuietStandby_3 "Bus quiet standby time";
CM_ SG_ 2176909315 BATT_timeBusQuietSleep_3 "Bus quiet sleep time";
CM_ BO_ 2176909316 "Balancing status";
CM_ SG_ 2176909316 BATT_timeBusQuietStandby_4 "Bus quiet standby time";
CM_ SG_ 2176909316 BATT_timeBusQuietSleep_4 "Bus quiet sleep time";
CM_ BO_ 2176909317 "Balancing status";
CM_ SG_ 2176909317 BATT_timeBusQuietStandby_5 "Bus quiet standby time";
CM_ SG_ 2176909317 BATT_timeBusQuietSleep_5 "Bus quiet sleep time";
CM_ BO_ 2176909318 "Balancing status";
CM_ SG_ 2176909318 BATT_timeBusQuietStandby_6 "Bus quiet standby time";
CM_ SG_ 2176909318 BATT_timeBusQuietSleep_6 "Bus quiet sleep time";
CM_ BO_ 2176909319 "Balancing status";
CM_ SG_ 2176909319 BATT_timeBusQuietStandby_7 "Bus quiet standby time";
CM_ SG_ 2176909319 BATT_timeBusQuietSleep_7 "Bus quiet sleep time";
CM_ BO_ 2176909320 "Balancing status";
CM_ SG_ 2176909320 BATT_timeBusQuietStandby_8 "Bus quiet standby time";
CM_ SG_ 2176909320 BATT_timeBusQuietSleep_8 "Bus quiet sleep time";
CM_ BO_ 2176909321 "Balancing status";
CM_ SG_ 2176909321 BATT_timeBusQuietStandby_9 "Bus quiet standby time";
CM_ SG_ 2176909321 BATT_timeBusQuietSleep_9 "Bus quiet sleep time";
CM_ BO_ 2176909322 "Balancing status";
CM_ SG_ 2176909322 BATT_timeBusQuietStandby_10 "Bus quiet standby time";
CM_ SG_ 2176909322 BATT_timeBusQuietSleep_10 "Bus quiet sleep time";
CM_ BO_ 2176909323 "Balancing status";
CM_ SG_ 2176909323 BATT_timeBusQuietStandby_11 "Bus quiet standby time";
CM_ SG_ 2176909323 BATT_timeBusQuietSleep_11 "Bus quiet sleep time";
CM_ BO_ 2215116800 "Battery capacity";
CM_ SG_ 2215116800 BATT_modFullChargeCap_Ah_0 "Estimated full charge capacity";
CM_ SG_ 2215116800 BATT_modRemainingCap_Ah_0 "Remaining charge";
CM_ BO_ 2215116801 "Battery capacity";
CM_ SG_ 2215116801 BATT_modFullChargeCap_Ah_1 "Estimated full charge capacity";
CM_ SG_ 2215116801 BATT_modRemainingCap_Ah_1 "Remaining charge";
CM_ BO_ 2215116802 "Battery capacity";
CM_ SG_ 2215116802 BATT_modFullChargeCap_Ah_2 "Estimated full charge capacity";
CM_ SG_ 2215116802 BATT_modRemainingCap_Ah_2 "Remaining charge";
CM_ BO_ 2215116803 "Battery capacity";
CM_ SG_ 2215116803 BATT_modFullChargeCap_Ah_3 "Estimated full charge capacity";
CM_ SG_ 2215116803 BATT_modRemainingCap_Ah_3 "Remaining charge";
CM_ BO_ 2215116804 "Battery capacity";
CM_ SG_ 2215116804 BATT_modFullChargeCap_Ah_4 "Estimated full charge capacity";
CM_ SG_ 2215116804 BATT_modRemainingCap_Ah_4 "Remaining charge";
CM_ BO_ 2215116805 "Battery capacity";
CM_ SG_ 2215116805 BATT_modFullChargeCap_Ah_5 "Estimated full charge capacity";
CM_ SG_ 2215116805 BATT_modRemainingCap_Ah_5 "Remaining charge";
CM_ BO_ 2215116806 "Battery capacity";
CM_ SG_ 2215116806 BATT_modFullChargeCap_Ah_6 "Estimated full charge capacity";
CM_ SG_ 2215116806 BATT_modRemainingCap_Ah_6 "Remaining charge";
CM_ BO_ 2215116807 "Battery capacity";
CM_ SG_ 2215116807 BATT_modFullChargeCap_Ah_7 "Estimated full charge capacity";
CM_ SG_ 2215116807 BATT_modRemainingCap_Ah_7 "Remaining charge";
CM_ BO_ 2215116808 "Battery capacity";
CM_ SG_ 2215116808 BATT_modFullChargeCap_Ah_8 "Estimated full charge capacity";
CM_ SG_ 2215116808 BATT_modRemainingCap_Ah_8 "Remaining charge";
CM_ BO_ 2215116809 "Battery capacity";
CM_ SG_ 2215116809 BATT_modFullChargeCap_Ah_9 "Estimated full charge capacity";
CM_ SG_ 2215116809 BATT_modRemainingCap_Ah_9 "Remaining charge";
CM_ BO_ 2215116810 "Battery capacity";
CM_ SG_ 2215116810 BATT_modFullChargeCap_Ah_10 "Estimated full charge capacity";
CM_ SG_ 2215116810 BATT_modRemainingCap_Ah_10 "Remaining charge";
CM_ BO_ 2215116811 "Battery capacity";
CM_ SG_ 2215116811 BATT_modFullChargeCap_Ah_11 "Estimated full charge capacity";
CM_ SG_ 2215116811 BATT_modRemainingCap_Ah_11 "Remaining charge";
CM_ SG_ 2215378944 BATT_vMod_0 "Battery terminal voltage";
CM_ SG_ 2215378944 BATT_vModSumOfCells_0 "Battery pack voltage in volts, sum of brick voltages";
CM_ SG_ 2215378944 BATT_iMod_0 "Charge/discharge rate in ampere - positive for charge, negative for discharge.";
CM_ SG_ 2215378944 BATT_iModFiltered_0 "Filtered charge/discharge rate in ampere - positive for charge, negative for discharge.";
CM_ SG_ 2215378945 BATT_vMod_1 "Battery terminal voltage";
CM_ SG_ 2215378945 BATT_vModSumOfCells_1 "Battery pack voltage in volts, sum of brick voltages";
CM_ SG_ 2215378945 BATT_iMod_1 "Charge/discharge rate in ampere - positive for charge, negative for discharge.";
CM_ SG_ 2215378945 BATT_iModFiltered_1 "Filtered charge/discharge rate in ampere - positive for charge, negative for discharge.";
CM_ SG_ 2215378946 BATT_vMod_2 "Battery terminal voltage";
CM_ SG_ 2215378946 BATT_vModSumOfCells_2 "Battery pack voltage in volts, sum of brick voltages";
CM_ SG_ 2215378946 BATT_iMod_2 "Charge/discharge rate in ampere - positive for charge, negative for discharge.";
CM_ SG_ 2215378946 BATT_iModFiltered_2 "Filtered charge/discharge rate in ampere - positive for charge, negative for discharge.";
CM_ SG_ 2215378947 BATT_vMod_3 "Battery terminal voltage";
CM_ SG_ 2215378947 BATT_vModSumOfCells_3 "Battery pack voltage in volts, sum of brick voltages";
CM_ SG_ 2215378947 BATT_iMod_3 "Charge/discharge rate in ampere - positive for charge, negative for discharge.";
CM_ SG_ 2215378947 BATT_iModFiltered_3 "Filtered charge/discharge rate in ampere - positive for charge, negative for discharge.";
CM_ SG_ 2215378948 BATT_vMod_4 "Battery terminal voltage";
CM_ SG_ 2215378948 BATT_vModSumOfCells_4 "Battery pack voltage in volts, sum of brick voltages";
CM_ SG_ 2215378948 BATT_iMod_4 "Charge/discharge rate in ampere - positive for charge, negative for discharge.";
CM_ SG_ 2215378948 BATT_iModFiltered_4 "Filtered charge/discharge rate in ampere - positive for charge, negative for discharge.";
CM_ SG_ 2215378949 BATT_vMod_5 "Battery terminal voltage";
CM_ SG_ 2215378949 BATT_vModSumOfCells_5 "Battery pack voltage in volts, sum of brick voltages";
CM_ SG_ 2215378949 BATT_iMod_5 "Charge/discharge rate in ampere - positive for charge, negative for discharge.";
CM_ SG_ 2215378949 BATT_iModFiltered_5 "Filtered charge/discharge rate in ampere - positive for charge, negative for discharge.";
CM_ SG_ 2215378950 BATT_vMod_6 "Battery terminal voltage";
CM_ SG_ 2215378950 BATT_vModSumOfCells_6 "Battery pack voltage in volts, sum of brick voltages";
CM_ SG_ 2215378950 BATT_iMod_6 "Charge/discharge rate in ampere - positive for charge, negative for discharge.";
CM_ SG_ 2215378950 BATT_iModFiltered_6 "Filtered charge/discharge rate in ampere - positive for charge, negative for discharge.";
CM_ SG_ 2215378951 BATT_vMod_7 "Battery terminal voltage";
CM_ SG_ 2215378951 BATT_vModSumOfCells_7 "Battery pack voltage in volts, sum of brick voltages";
CM_ SG_ 2215378951 BATT_iMod_7 "Charge/discharge rate in ampere - positive for charge, negative for discharge.";
CM_ SG_ 2215378951 BATT_iModFiltered_7 "Filtered charge/discharge rate in ampere - positive for charge, negative for discharge.";
CM_ SG_ 2215378952 BATT_vMod_8 "Battery terminal voltage";
CM_ SG_ 2215378952 BATT_vModSumOfCells_8 "Battery pack voltage in volts, sum of brick voltages";
CM_ SG_ 2215378952 BATT_iMod_8 "Charge/discharge rate in ampere - positive for charge, negative for discharge.";
CM_ SG_ 2215378952 BATT_iModFiltered_8 "Filtered charge/discharge rate in ampere - positive for charge, negative for discharge.";
CM_ SG_ 2215378953 BATT_vMod_9 "Battery terminal voltage";
CM_ SG_ 2215378953 BATT_vModSumOfCells_9 "Battery pack voltage in volts, sum of brick voltages";
CM_ SG_ 2215378953 BATT_iMod_9 "Charge/discharge rate in ampere - positive for charge, negative for discharge.";
CM_ SG_ 2215378953 BATT_iModFiltered_9 "Filtered charge/discharge rate in ampere - positive for charge, negative for discharge.";
CM_ SG_ 2215378954 BATT_vMod_10 "Battery terminal voltage";
CM_ SG_ 2215378954 BATT_vModSumOfCells_10 "Battery pack voltage in volts, sum of brick voltages";
CM_ SG_ 2215378954 BATT_iMod_10 "Charge/discharge rate in ampere - positive for charge, negative for discharge.";
CM_ SG_ 2215378954 BATT_iModFiltered_10 "Filtered charge/discharge rate in ampere - positive for charge, negative for discharge.";
CM_ SG_ 2215378955 BATT_vMod_11 "Battery terminal voltage";
CM_ SG_ 2215378955 BATT_vModSumOfCells_11 "Battery pack voltage in volts, sum of brick voltages";
CM_ SG_ 2215378955 BATT_iMod_11 "Charge/discharge rate in ampere - positive for charge, negative for discharge.";
CM_ SG_ 2215378955 BATT_iModFiltered_11 "Filtered charge/discharge rate in ampere - positive for charge, negative for discharge.";
CM_ BO_ 2215903232 "Battery SOC";
CM_ SG_ 2215903232 BATT_sohcMod_0 "State of Charge for the battery pack";
CM_ SG_ 2215903232 BATT_socMod_0 "State of Charge for the battery pack";
CM_ SG_ 2215903232 BATT_socLimiting_0 "State of charge of battery brick which is the limiting";
CM_ SG_ 2215903232 BATT_idSOCLimiting_0 "ID of limiting brick";
CM_ BO_ 2215903233 "Battery SOC";
CM_ SG_ 2215903233 BATT_sohcMod_1 "State of Charge for the battery pack";
CM_ SG_ 2215903233 BATT_socMod_1 "State of Charge for the battery pack";
CM_ SG_ 2215903233 BATT_socLimiting_1 "State of charge of battery brick which is the limiting";
CM_ SG_ 2215903233 BATT_idSOCLimiting_1 "ID of limiting brick";
CM_ BO_ 2215903234 "Battery SOC";
CM_ SG_ 2215903234 BATT_sohcMod_2 "State of Charge for the battery pack";
CM_ SG_ 2215903234 BATT_socMod_2 "State of Charge for the battery pack";
CM_ SG_ 2215903234 BATT_socLimiting_2 "State of charge of battery brick which is the limiting";
CM_ SG_ 2215903234 BATT_idSOCLimiting_2 "ID of limiting brick";
CM_ BO_ 2215903235 "Battery SOC";
CM_ SG_ 2215903235 BATT_sohcMod_3 "State of Charge for the battery pack";
CM_ SG_ 2215903235 BATT_socMod_3 "State of Charge for the battery pack";
CM_ SG_ 2215903235 BATT_socLimiting_3 "State of charge of battery brick which is the limiting";
CM_ SG_ 2215903235 BATT_idSOCLimiting_3 "ID of limiting brick";
CM_ BO_ 2215903236 "Battery SOC";
CM_ SG_ 2215903236 BATT_sohcMod_4 "State of Charge for the battery pack";
CM_ SG_ 2215903236 BATT_socMod_4 "State of Charge for the battery pack";
CM_ SG_ 2215903236 BATT_socLimiting_4 "State of charge of battery brick which is the limiting";
CM_ SG_ 2215903236 BATT_idSOCLimiting_4 "ID of limiting brick";
CM_ BO_ 2215903237 "Battery SOC";
CM_ SG_ 2215903237 BATT_sohcMod_5 "State of Charge for the battery pack";
CM_ SG_ 2215903237 BATT_socMod_5 "State of Charge for the battery pack";
CM_ SG_ 2215903237 BATT_socLimiting_5 "State of charge of battery brick which is the limiting";
CM_ SG_ 2215903237 BATT_idSOCLimiting_5 "ID of limiting brick";
CM_ BO_ 2215903238 "Battery SOC";
CM_ SG_ 2215903238 BATT_sohcMod_6 "State of Charge for the battery pack";
CM_ SG_ 2215903238 BATT_socMod_6 "State of Charge for the battery pack";
CM_ SG_ 2215903238 BATT_socLimiting_6 "State of charge of battery brick which is the limiting";
CM_ SG_ 2215903238 BATT_idSOCLimiting_6 "ID of limiting brick";
CM_ BO_ 2215903239 "Battery SOC";
CM_ SG_ 2215903239 BATT_sohcMod_7 "State of Charge for the battery pack";
CM_ SG_ 2215903239 BATT_socMod_7 "State of Charge for the battery pack";
CM_ SG_ 2215903239 BATT_socLimiting_7 "State of charge of battery brick which is the limiting";
CM_ SG_ 2215903239 BATT_idSOCLimiting_7 "ID of limiting brick";
CM_ BO_ 2215903240 "Battery SOC";
CM_ SG_ 2215903240 BATT_sohcMod_8 "State of Charge for the battery pack";
CM_ SG_ 2215903240 BATT_socMod_8 "State of Charge for the battery pack";
CM_ SG_ 2215903240 BATT_socLimiting_8 "State of charge of battery brick which is the limiting";
CM_ SG_ 2215903240 BATT_idSOCLimiting_8 "ID of limiting brick";
CM_ BO_ 2215903241 "Battery SOC";
CM_ SG_ 2215903241 BATT_sohcMod_9 "State of Charge for the battery pack";
CM_ SG_ 2215903241 BATT_socMod_9 "State of Charge for the battery pack";
CM_ SG_ 2215903241 BATT_socLimiting_9 "State of charge of battery brick which is the limiting";
CM_ SG_ 2215903241 BATT_idSOCLimiting_9 "ID of limiting brick";
CM_ BO_ 2215903242 "Battery SOC";
CM_ SG_ 2215903242 BATT_sohcMod_10 "State of Charge for the battery pack";
CM_ SG_ 2215903242 BATT_socMod_10 "State of Charge for the battery pack";
CM_ SG_ 2215903242 BATT_socLimiting_10 "State of charge of battery brick which is the limiting";
CM_ SG_ 2215903242 BATT_idSOCLimiting_10 "ID of limiting brick";
CM_ BO_ 2215903243 "Battery SOC";
CM_ SG_ 2215903243 BATT_sohcMod_11 "State of Charge for the battery pack";
CM_ SG_ 2215903243 BATT_socMod_11 "State of Charge for the battery pack";
CM_ SG_ 2215903243 BATT_socLimiting_11 "State of charge of battery brick which is the limiting";
CM_ SG_ 2215903243 BATT_idSOCLimiting_11 "ID of limiting brick";
CM_ BO_ 2219376640 "Battery limits";
CM_ SG_ 2219376640 BATT_vModChgLimit_0 "Voltage recharge limit sent to inverter";
CM_ SG_ 2219376640 BATT_iModChgLimitInst_0 "Current recharge limit in A";
CM_ SG_ 2219376640 BATT_iModChgLimit10s_0 "Current recharge limit in A";
CM_ SG_ 2219376640 BATT_iModChgLimitCont_0 "Current recharge limit in A";
CM_ BO_ 2219376641 "Battery limits";
CM_ SG_ 2219376641 BATT_vModChgLimit_1 "Voltage recharge limit sent to inverter";
CM_ SG_ 2219376641 BATT_iModChgLimitInst_1 "Current recharge limit in A";
CM_ SG_ 2219376641 BATT_iModChgLimit10s_1 "Current recharge limit in A";
CM_ SG_ 2219376641 BATT_iModChgLimitCont_1 "Current recharge limit in A";
CM_ BO_ 2219376642 "Battery limits";
CM_ SG_ 2219376642 BATT_vModChgLimit_2 "Voltage recharge limit sent to inverter";
CM_ SG_ 2219376642 BATT_iModChgLimitInst_2 "Current recharge limit in A";
CM_ SG_ 2219376642 BATT_iModChgLimit10s_2 "Current recharge limit in A";
CM_ SG_ 2219376642 BATT_iModChgLimitCont_2 "Current recharge limit in A";
CM_ BO_ 2219376643 "Battery limits";
CM_ SG_ 2219376643 BATT_vModChgLimit_3 "Voltage recharge limit sent to inverter";
CM_ SG_ 2219376643 BATT_iModChgLimitInst_3 "Current recharge limit in A";
CM_ SG_ 2219376643 BATT_iModChgLimit10s_3 "Current recharge limit in A";
CM_ SG_ 2219376643 BATT_iModChgLimitCont_3 "Current recharge limit in A";
CM_ BO_ 2219376644 "Battery limits";
CM_ SG_ 2219376644 BATT_vModChgLimit_4 "Voltage recharge limit sent to inverter";
CM_ SG_ 2219376644 BATT_iModChgLimitInst_4 "Current recharge limit in A";
CM_ SG_ 2219376644 BATT_iModChgLimit10s_4 "Current recharge limit in A";
CM_ SG_ 2219376644 BATT_iModChgLimitCont_4 "Current recharge limit in A";
CM_ BO_ 2219376645 "Battery limits";
CM_ SG_ 2219376645 BATT_vModChgLimit_5 "Voltage recharge limit sent to inverter";
CM_ SG_ 2219376645 BATT_iModChgLimitInst_5 "Current recharge limit in A";
CM_ SG_ 2219376645 BATT_iModChgLimit10s_5 "Current recharge limit in A";
CM_ SG_ 2219376645 BATT_iModChgLimitCont_5 "Current recharge limit in A";
CM_ BO_ 2219376646 "Battery limits";
CM_ SG_ 2219376646 BATT_vModChgLimit_6 "Voltage recharge limit sent to inverter";
CM_ SG_ 2219376646 BATT_iModChgLimitInst_6 "Current recharge limit in A";
CM_ SG_ 2219376646 BATT_iModChgLimit10s_6 "Current recharge limit in A";
CM_ SG_ 2219376646 BATT_iModChgLimitCont_6 "Current recharge limit in A";
CM_ BO_ 2219376647 "Battery limits";
CM_ SG_ 2219376647 BATT_vModChgLimit_7 "Voltage recharge limit sent to inverter";
CM_ SG_ 2219376647 BATT_iModChgLimitInst_7 "Current recharge limit in A";
CM_ SG_ 2219376647 BATT_iModChgLimit10s_7 "Current recharge limit in A";
CM_ SG_ 2219376647 BATT_iModChgLimitCont_7 "Current recharge limit in A";
CM_ BO_ 2219376648 "Battery limits";
CM_ SG_ 2219376648 BATT_vModChgLimit_8 "Voltage recharge limit sent to inverter";
CM_ SG_ 2219376648 BATT_iModChgLimitInst_8 "Current recharge limit in A";
CM_ SG_ 2219376648 BATT_iModChgLimit10s_8 "Current recharge limit in A";
CM_ SG_ 2219376648 BATT_iModChgLimitCont_8 "Current recharge limit in A";
CM_ BO_ 2219376649 "Battery limits";
CM_ SG_ 2219376649 BATT_vModChgLimit_9 "Voltage recharge limit sent to inverter";
CM_ SG_ 2219376649 BATT_iModChgLimitInst_9 "Current recharge limit in A";
CM_ SG_ 2219376649 BATT_iModChgLimit10s_9 "Current recharge limit in A";
CM_ SG_ 2219376649 BATT_iModChgLimitCont_9 "Current recharge limit in A";
CM_ BO_ 2219376650 "Battery limits";
CM_ SG_ 2219376650 BATT_vModChgLimit_10 "Voltage recharge limit sent to inverter";
CM_ SG_ 2219376650 BATT_iModChgLimitInst_10 "Current recharge limit in A";
CM_ SG_ 2219376650 BATT_iModChgLimit10s_10 "Current recharge limit in A";
CM_ SG_ 2219376650 BATT_iModChgLimitCont_10 "Current recharge limit in A";
CM_ BO_ 2219376651 "Battery limits";
CM_ SG_ 2219376651 BATT_vModChgLimit_11 "Voltage recharge limit sent to inverter";
CM_ SG_ 2219376651 BATT_iModChgLimitInst_11 "Current recharge limit in A";
CM_ SG_ 2219376651 BATT_iModChgLimit10s_11 "Current recharge limit in A";
CM_ SG_ 2219376651 BATT_iModChgLimitCont_11 "Current recharge limit in A";
CM_ BO_ 2219573248 "Battery limits";
CM_ SG_ 2219573248 BATT_vModDchLimit_0 "Voltage discharge limit sent to inverter";
CM_ SG_ 2219573248 BATT_iModDchLimitInst_0 "Current discharge limit in A";
CM_ SG_ 2219573248 BATT_iModDchLimit10s_0 "Current discharge limit in A";
CM_ SG_ 2219573248 BATT_iModDchLimitCont_0 "Current discharge limit in A";
CM_ BO_ 2219573249 "Battery limits";
CM_ SG_ 2219573249 BATT_vModDchLimit_1 "Voltage discharge limit sent to inverter";
CM_ SG_ 2219573249 BATT_iModDchLimitInst_1 "Current discharge limit in A";
CM_ SG_ 2219573249 BATT_iModDchLimit10s_1 "Current discharge limit in A";
CM_ SG_ 2219573249 BATT_iModDchLimitCont_1 "Current discharge limit in A";
CM_ BO_ 2219573250 "Battery limits";
CM_ SG_ 2219573250 BATT_vModDchLimit_2 "Voltage discharge limit sent to inverter";
CM_ SG_ 2219573250 BATT_iModDchLimitInst_2 "Current discharge limit in A";
CM_ SG_ 2219573250 BATT_iModDchLimit10s_2 "Current discharge limit in A";
CM_ SG_ 2219573250 BATT_iModDchLimitCont_2 "Current discharge limit in A";
CM_ BO_ 2219573251 "Battery limits";
CM_ SG_ 2219573251 BATT_vModDchLimit_3 "Voltage discharge limit sent to inverter";
CM_ SG_ 2219573251 BATT_iModDchLimitInst_3 "Current discharge limit in A";
CM_ SG_ 2219573251 BATT_iModDchLimit10s_3 "Current discharge limit in A";
CM_ SG_ 2219573251 BATT_iModDchLimitCont_3 "Current discharge limit in A";
CM_ BO_ 2219573252 "Battery limits";
CM_ SG_ 2219573252 BATT_vModDchLimit_4 "Voltage discharge limit sent to inverter";
CM_ SG_ 2219573252 BATT_iModDchLimitInst_4 "Current discharge limit in A";
CM_ SG_ 2219573252 BATT_iModDchLimit10s_4 "Current discharge limit in A";
CM_ SG_ 2219573252 BATT_iModDchLimitCont_4 "Current discharge limit in A";
CM_ BO_ 2219573253 "Battery limits";
CM_ SG_ 2219573253 BATT_vModDchLimit_5 "Voltage discharge limit sent to inverter";
CM_ SG_ 2219573253 BATT_iModDchLimitInst_5 "Current discharge limit in A";
CM_ SG_ 2219573253 BATT_iModDchLimit10s_5 "Current discharge limit in A";
CM_ SG_ 2219573253 BATT_iModDchLimitCont_5 "Current discharge limit in A";
CM_ BO_ 2219573254 "Battery limits";
CM_ SG_ 2219573254 BATT_vModDchLimit_6 "Voltage discharge limit sent to inverter";
CM_ SG_ 2219573254 BATT_iModDchLimitInst_6 "Current discharge limit in A";
CM_ SG_ 2219573254 BATT_iModDchLimit10s_6 "Current discharge limit in A";
CM_ SG_ 2219573254 BATT_iModDchLimitCont_6 "Current discharge limit in A";
CM_ BO_ 2219573255 "Battery limits";
CM_ SG_ 2219573255 BATT_vModDchLimit_7 "Voltage discharge limit sent to inverter";
CM_ SG_ 2219573255 BATT_iModDchLimitInst_7 "Current discharge limit in A";
CM_ SG_ 2219573255 BATT_iModDchLimit10s_7 "Current discharge limit in A";
CM_ SG_ 2219573255 BATT_iModDchLimitCont_7 "Current discharge limit in A";
CM_ BO_ 2219573256 "Battery limits";
CM_ SG_ 2219573256 BATT_vModDchLimit_8 "Voltage discharge limit sent to inverter";
CM_ SG_ 2219573256 BATT_iModDchLimitInst_8 "Current discharge limit in A";
CM_ SG_ 2219573256 BATT_iModDchLimit10s_8 "Current discharge limit in A";
CM_ SG_ 2219573256 BATT_iModDchLimitCont_8 "Current discharge limit in A";
CM_ BO_ 2219573257 "Battery limits";
CM_ SG_ 2219573257 BATT_vModDchLimit_9 "Voltage discharge limit sent to inverter";
CM_ SG_ 2219573257 BATT_iModDchLimitInst_9 "Current discharge limit in A";
CM_ SG_ 2219573257 BATT_iModDchLimit10s_9 "Current discharge limit in A";
CM_ SG_ 2219573257 BATT_iModDchLimitCont_9 "Current discharge limit in A";
CM_ BO_ 2219573258 "Battery limits";
CM_ SG_ 2219573258 BATT_vModDchLimit_10 "Voltage discharge limit sent to inverter";
CM_ SG_ 2219573258 BATT_iModDchLimitInst_10 "Current discharge limit in A";
CM_ SG_ 2219573258 BATT_iModDchLimit10s_10 "Current discharge limit in A";
CM_ SG_ 2219573258 BATT_iModDchLimitCont_10 "Current discharge limit in A";
CM_ BO_ 2219573259 "Battery limits";
CM_ SG_ 2219573259 BATT_vModDchLimit_11 "Voltage discharge limit sent to inverter";
CM_ SG_ 2219573259 BATT_iModDchLimitInst_11 "Current discharge limit in A";
CM_ SG_ 2219573259 BATT_iModDchLimit10s_11 "Current discharge limit in A";
CM_ SG_ 2219573259 BATT_iModDchLimitCont_11 "Current discharge limit in A";
CM_ BO_ 2219835392 "Module power available";
CM_ SG_ 2219835392 BATT_pwrModDchLimit_0 "Module discharge power available in kW";
CM_ SG_ 2219835392 BATT_pwrModChgLimit_0 "Module charge power available in kW";
CM_ BO_ 2219835393 "Module power available";
CM_ SG_ 2219835393 BATT_pwrModDchLimit_1 "Module discharge power available in kW";
CM_ SG_ 2219835393 BATT_pwrModChgLimit_1 "Module charge power available in kW";
CM_ BO_ 2219835394 "Module power available";
CM_ SG_ 2219835394 BATT_pwrModDchLimit_2 "Module discharge power available in kW";
CM_ SG_ 2219835394 BATT_pwrModChgLimit_2 "Module charge power available in kW";
CM_ BO_ 2219835395 "Module power available";
CM_ SG_ 2219835395 BATT_pwrModDchLimit_3 "Module discharge power available in kW";
CM_ SG_ 2219835395 BATT_pwrModChgLimit_3 "Module charge power available in kW";
CM_ BO_ 2219835396 "Module power available";
CM_ SG_ 2219835396 BATT_pwrModDchLimit_4 "Module discharge power available in kW";
CM_ SG_ 2219835396 BATT_pwrModChgLimit_4 "Module charge power available in kW";
CM_ BO_ 2219835397 "Module power available";
CM_ SG_ 2219835397 BATT_pwrModDchLimit_5 "Module discharge power available in kW";
CM_ SG_ 2219835397 BATT_pwrModChgLimit_5 "Module charge power available in kW";
CM_ BO_ 2219835398 "Module power available";
CM_ SG_ 2219835398 BATT_pwrModDchLimit_6 "Module discharge power available in kW";
CM_ SG_ 2219835398 BATT_pwrModChgLimit_6 "Module charge power available in kW";
CM_ BO_ 2219835399 "Module power available";
CM_ SG_ 2219835399 BATT_pwrModDchLimit_7 "Module discharge power available in kW";
CM_ SG_ 2219835399 BATT_pwrModChgLimit_7 "Module charge power available in kW";
CM_ BO_ 2219835400 "Module power available";
CM_ SG_ 2219835400 BATT_pwrModDchLimit_8 "Module discharge power available in kW";
CM_ SG_ 2219835400 BATT_pwrModChgLimit_8 "Module charge power available in kW";
CM_ BO_ 2219835401 "Module power available";
CM_ SG_ 2219835401 BATT_pwrModDchLimit_9 "Module discharge power available in kW";
CM_ SG_ 2219835401 BATT_pwrModChgLimit_9 "Module charge power available in kW";
CM_ BO_ 2219835402 "Module power available";
CM_ SG_ 2219835402 BATT_pwrModDchLimit_10 "Module discharge power available in kW";
CM_ SG_ 2219835402 BATT_pwrModChgLimit_10 "Module charge power available in kW";
CM_ BO_ 2219835403 "Module power available";
CM_ SG_ 2219835403 BATT_pwrModDchLimit_11 "Module discharge power available in kW";
CM_ SG_ 2219835403 BATT_pwrModChgLimit_11 "Module charge power available in kW";
CM_ SG_ 2221146112 BATT_tModule2_0 "Battery temperature as measured by thermistor two";
CM_ SG_ 2221146112 BATT_tModule1_0 "Battery temperature as measured by thermistor one";
CM_ SG_ 2221146112 BATT_tAmbient_0 "Ambient/Board temperature measured";
CM_ SG_ 2221146113 BATT_tModule2_1 "Battery temperature as measured by thermistor two";
CM_ SG_ 2221146113 BATT_tModule1_1 "Battery temperature as measured by thermistor one";
CM_ SG_ 2221146113 BATT_tAmbient_1 "Ambient/Board temperature measured";
CM_ SG_ 2221146114 BATT_tModule2_2 "Battery temperature as measured by thermistor two";
CM_ SG_ 2221146114 BATT_tModule1_2 "Battery temperature as measured by thermistor one";
CM_ SG_ 2221146114 BATT_tAmbient_2 "Ambient/Board temperature measured";
CM_ SG_ 2221146115 BATT_tModule2_3 "Battery temperature as measured by thermistor two";
CM_ SG_ 2221146115 BATT_tModule1_3 "Battery temperature as measured by thermistor one";
CM_ SG_ 2221146115 BATT_tAmbient_3 "Ambient/Board temperature measured";
CM_ SG_ 2221146116 BATT_tModule2_4 "Battery temperature as measured by thermistor two";
CM_ SG_ 2221146116 BATT_tModule1_4 "Battery temperature as measured by thermistor one";
CM_ SG_ 2221146116 BATT_tAmbient_4 "Ambient/Board temperature measured";
CM_ SG_ 2221146117 BATT_tModule2_5 "Battery temperature as measured by thermistor two";
CM_ SG_ 2221146117 BATT_tModule1_5 "Battery temperature as measured by thermistor one";
CM_ SG_ 2221146117 BATT_tAmbient_5 "Ambient/Board temperature measured";
CM_ SG_ 2221146118 BATT_tModule2_6 "Battery temperature as measured by thermistor two";
CM_ SG_ 2221146118 BATT_tModule1_6 "Battery temperature as measured by thermistor one";
CM_ SG_ 2221146118 BATT_tAmbient_6 "Ambient/Board temperature measured";
CM_ SG_ 2221146119 BATT_tModule2_7 "Battery temperature as measured by thermistor two";
CM_ SG_ 2221146119 BATT_tModule1_7 "Battery temperature as measured by thermistor one";
CM_ SG_ 2221146119 BATT_tAmbient_7 "Ambient/Board temperature measured";
CM_ SG_ 2221146120 BATT_tModule2_8 "Battery temperature as measured by thermistor two";
CM_ SG_ 2221146120 BATT_tModule1_8 "Battery temperature as measured by thermistor one";
CM_ SG_ 2221146120 BATT_tAmbient_8 "Ambient/Board temperature measured";
CM_ SG_ 2221146121 BATT_tModule2_9 "Battery temperature as measured by thermistor two";
CM_ SG_ 2221146121 BATT_tModule1_9 "Battery temperature as measured by thermistor one";
CM_ SG_ 2221146121 BATT_tAmbient_9 "Ambient/Board temperature measured";
CM_ SG_ 2221146122 BATT_tModule2_10 "Battery temperature as measured by thermistor two";
CM_ SG_ 2221146122 BATT_tModule1_10 "Battery temperature as measured by thermistor one";
CM_ SG_ 2221146122 BATT_tAmbient_10 "Ambient/Board temperature measured";
CM_ SG_ 2221146123 BATT_tModule2_11 "Battery temperature as measured by thermistor two";
CM_ SG_ 2221146123 BATT_tModule1_11 "Battery temperature as measured by thermistor one";
CM_ SG_ 2221146123 BATT_tAmbient_11 "Ambient/Board temperature measured";
CM_ SG_ 2222981120 BATT_tShunt_0 "Temperature of current shunt";
CM_ SG_ 2222981120 BATT_tFET_0 "Temperature of FETs";
CM_ SG_ 2222981121 BATT_tShunt_1 "Temperature of current shunt";
CM_ SG_ 2222981121 BATT_tFET_1 "Temperature of FETs";
CM_ SG_ 2222981122 BATT_tShunt_2 "Temperature of current shunt";
CM_ SG_ 2222981122 BATT_tFET_2 "Temperature of FETs";
CM_ SG_ 2222981123 BATT_tShunt_3 "Temperature of current shunt";
CM_ SG_ 2222981123 BATT_tFET_3 "Temperature of FETs";
CM_ SG_ 2222981124 BATT_tShunt_4 "Temperature of current shunt";
CM_ SG_ 2222981124 BATT_tFET_4 "Temperature of FETs";
CM_ SG_ 2222981125 BATT_tShunt_5 "Temperature of current shunt";
CM_ SG_ 2222981125 BATT_tFET_5 "Temperature of FETs";
CM_ SG_ 2222981126 BATT_tShunt_6 "Temperature of current shunt";
CM_ SG_ 2222981126 BATT_tFET_6 "Temperature of FETs";
CM_ SG_ 2222981127 BATT_tShunt_7 "Temperature of current shunt";
CM_ SG_ 2222981127 BATT_tFET_7 "Temperature of FETs";
CM_ SG_ 2222981128 BATT_tShunt_8 "Temperature of current shunt";
CM_ SG_ 2222981128 BATT_tFET_8 "Temperature of FETs";
CM_ SG_ 2222981129 BATT_tShunt_9 "Temperature of current shunt";
CM_ SG_ 2222981129 BATT_tFET_9 "Temperature of FETs";
CM_ SG_ 2222981130 BATT_tShunt_10 "Temperature of current shunt";
CM_ SG_ 2222981130 BATT_tFET_10 "Temperature of FETs";
CM_ SG_ 2222981131 BATT_tShunt_11 "Temperature of current shunt";
CM_ SG_ 2222981131 BATT_tFET_11 "Temperature of FETs";
CM_ BO_ 2224029696 "Battery load status";
CM_ SG_ 2224029696 BATT_resMod_0 "Impedance of module";
CM_ SG_ 2224029696 BATT_voirMod_0 "Battery Voir Voltage";
CM_ SG_ 2224029696 BATT_vModLoad_0 "Voltage measured across load";
CM_ BO_ 2224029697 "Battery load status";
CM_ SG_ 2224029697 BATT_resMod_1 "Impedance of module";
CM_ SG_ 2224029697 BATT_voirMod_1 "Battery Voir Voltage";
CM_ SG_ 2224029697 BATT_vModLoad_1 "Voltage measured across load";
CM_ BO_ 2224029698 "Battery load status";
CM_ SG_ 2224029698 BATT_resMod_2 "Impedance of module";
CM_ SG_ 2224029698 BATT_voirMod_2 "Battery Voir Voltage";
CM_ SG_ 2224029698 BATT_vModLoad_2 "Voltage measured across load";
CM_ BO_ 2224029699 "Battery load status";
CM_ SG_ 2224029699 BATT_resMod_3 "Impedance of module";
CM_ SG_ 2224029699 BATT_voirMod_3 "Battery Voir Voltage";
CM_ SG_ 2224029699 BATT_vModLoad_3 "Voltage measured across load";
CM_ BO_ 2224029700 "Battery load status";
CM_ SG_ 2224029700 BATT_resMod_4 "Impedance of module";
CM_ SG_ 2224029700 BATT_voirMod_4 "Battery Voir Voltage";
CM_ SG_ 2224029700 BATT_vModLoad_4 "Voltage measured across load";
CM_ BO_ 2224029701 "Battery load status";
CM_ SG_ 2224029701 BATT_resMod_5 "Impedance of module";
CM_ SG_ 2224029701 BATT_voirMod_5 "Battery Voir Voltage";
CM_ SG_ 2224029701 BATT_vModLoad_5 "Voltage measured across load";
CM_ BO_ 2224029702 "Battery load status";
CM_ SG_ 2224029702 BATT_resMod_6 "Impedance of module";
CM_ SG_ 2224029702 BATT_voirMod_6 "Battery Voir Voltage";
CM_ SG_ 2224029702 BATT_vModLoad_6 "Voltage measured across load";
CM_ BO_ 2224029703 "Battery load status";
CM_ SG_ 2224029703 BATT_resMod_7 "Impedance of module";
CM_ SG_ 2224029703 BATT_voirMod_7 "Battery Voir Voltage";
CM_ SG_ 2224029703 BATT_vModLoad_7 "Voltage measured across load";
CM_ BO_ 2224029704 "Battery load status";
CM_ SG_ 2224029704 BATT_resMod_8 "Impedance of module";
CM_ SG_ 2224029704 BATT_voirMod_8 "Battery Voir Voltage";
CM_ SG_ 2224029704 BATT_vModLoad_8 "Voltage measured across load";
CM_ BO_ 2224029705 "Battery load status";
CM_ SG_ 2224029705 BATT_resMod_9 "Impedance of module";
CM_ SG_ 2224029705 BATT_voirMod_9 "Battery Voir Voltage";
CM_ SG_ 2224029705 BATT_vModLoad_9 "Voltage measured across load";
CM_ BO_ 2224029706 "Battery load status";
CM_ SG_ 2224029706 BATT_resMod_10 "Impedance of module";
CM_ SG_ 2224029706 BATT_voirMod_10 "Battery Voir Voltage";
CM_ SG_ 2224029706 BATT_vModLoad_10 "Voltage measured across load";
CM_ BO_ 2224029707 "Battery load status";
CM_ SG_ 2224029707 BATT_resMod_11 "Impedance of module";
CM_ SG_ 2224029707 BATT_voirMod_11 "Battery Voir Voltage";
CM_ SG_ 2224029707 BATT_vModLoad_11 "Voltage measured across load";
CM_ BO_ 2224291840 "Battery min-max data";
CM_ SG_ 2224291840 BATT_tModuleMaxID_0 "ID of maximum Battery temperature ";
CM_ SG_ 2224291840 BATT_tModuleMinID_0 "ID of minimum Battery temperature ";
CM_ SG_ 2224291840 BATT_vBrickMaxID_0 "ID of maximum brick voltage ";
CM_ SG_ 2224291840 BATT_vBrickMinID_0 "ID of minimum brick voltage ";
CM_ SG_ 2224291840 BATT_tModuleMax_0 "Maximum Battery temperature";
CM_ SG_ 2224291840 BATT_tModuleMin_0 "Minimum Battery temperature";
CM_ SG_ 2224291840 BATT_vBrickMin_0 "Minimum brick voltage ";
CM_ SG_ 2224291840 BATT_vBrickMax_0 "Maximum brick voltage ";
CM_ BO_ 2224291841 "Battery min-max data";
CM_ SG_ 2224291841 BATT_tModuleMaxID_1 "ID of maximum Battery temperature ";
CM_ SG_ 2224291841 BATT_tModuleMinID_1 "ID of minimum Battery temperature ";
CM_ SG_ 2224291841 BATT_vBrickMaxID_1 "ID of maximum brick voltage ";
CM_ SG_ 2224291841 BATT_vBrickMinID_1 "ID of minimum brick voltage ";
CM_ SG_ 2224291841 BATT_tModuleMax_1 "Maximum Battery temperature";
CM_ SG_ 2224291841 BATT_tModuleMin_1 "Minimum Battery temperature";
CM_ SG_ 2224291841 BATT_vBrickMin_1 "Minimum brick voltage ";
CM_ SG_ 2224291841 BATT_vBrickMax_1 "Maximum brick voltage ";
CM_ BO_ 2224291842 "Battery min-max data";
CM_ SG_ 2224291842 BATT_tModuleMaxID_2 "ID of maximum Battery temperature ";
CM_ SG_ 2224291842 BATT_tModuleMinID_2 "ID of minimum Battery temperature ";
CM_ SG_ 2224291842 BATT_vBrickMaxID_2 "ID of maximum brick voltage ";
CM_ SG_ 2224291842 BATT_vBrickMinID_2 "ID of minimum brick voltage ";
CM_ SG_ 2224291842 BATT_tModuleMax_2 "Maximum Battery temperature";
CM_ SG_ 2224291842 BATT_tModuleMin_2 "Minimum Battery temperature";
CM_ SG_ 2224291842 BATT_vBrickMin_2 "Minimum brick voltage ";
CM_ SG_ 2224291842 BATT_vBrickMax_2 "Maximum brick voltage ";
CM_ BO_ 2224291843 "Battery min-max data";
CM_ SG_ 2224291843 BATT_tModuleMaxID_3 "ID of maximum Battery temperature ";
CM_ SG_ 2224291843 BATT_tModuleMinID_3 "ID of minimum Battery temperature ";
CM_ SG_ 2224291843 BATT_vBrickMaxID_3 "ID of maximum brick voltage ";
CM_ SG_ 2224291843 BATT_vBrickMinID_3 "ID of minimum brick voltage ";
CM_ SG_ 2224291843 BATT_tModuleMax_3 "Maximum Battery temperature";
CM_ SG_ 2224291843 BATT_tModuleMin_3 "Minimum Battery temperature";
CM_ SG_ 2224291843 BATT_vBrickMin_3 "Minimum brick voltage ";
CM_ SG_ 2224291843 BATT_vBrickMax_3 "Maximum brick voltage ";
CM_ BO_ 2224291844 "Battery min-max data";
CM_ SG_ 2224291844 BATT_tModuleMaxID_4 "ID of maximum Battery temperature ";
CM_ SG_ 2224291844 BATT_tModuleMinID_4 "ID of minimum Battery temperature ";
CM_ SG_ 2224291844 BATT_vBrickMaxID_4 "ID of maximum brick voltage ";
CM_ SG_ 2224291844 BATT_vBrickMinID_4 "ID of minimum brick voltage ";
CM_ SG_ 2224291844 BATT_tModuleMax_4 "Maximum Battery temperature";
CM_ SG_ 2224291844 BATT_tModuleMin_4 "Minimum Battery temperature";
CM_ SG_ 2224291844 BATT_vBrickMin_4 "Minimum brick voltage ";
CM_ SG_ 2224291844 BATT_vBrickMax_4 "Maximum brick voltage ";
CM_ BO_ 2224291845 "Battery min-max data";
CM_ SG_ 2224291845 BATT_tModuleMaxID_5 "ID of maximum Battery temperature ";
CM_ SG_ 2224291845 BATT_tModuleMinID_5 "ID of minimum Battery temperature ";
CM_ SG_ 2224291845 BATT_vBrickMaxID_5 "ID of maximum brick voltage ";
CM_ SG_ 2224291845 BATT_vBrickMinID_5 "ID of minimum brick voltage ";
CM_ SG_ 2224291845 BATT_tModuleMax_5 "Maximum Battery temperature";
CM_ SG_ 2224291845 BATT_tModuleMin_5 "Minimum Battery temperature";
CM_ SG_ 2224291845 BATT_vBrickMin_5 "Minimum brick voltage ";
CM_ SG_ 2224291845 BATT_vBrickMax_5 "Maximum brick voltage ";

BA_DEF_ BO_  "GenMsgDiag" ENUM "No","Yes";
BA_DEF_ BU_  "GenNodeInstanceBitWidth" INT 0 0;
BA_DEF_ BO_  "GenMsgInstanced" STRING ;
BA_DEF_ SG_  "GenSigType" ENUM "Extended","Diagnostic","Standard","Modified";
BA_DEF_ BO_  "GenMsgCycleTime" INT 0 0;
BA_DEF_ SG_  "GenSigSNA" INT 0 65535;
BA_DEF_ SG_  "Access" ENUM "r","rw";
BA_DEF_  "BusType" STRING ;
BA_DEF_DEF_  "GenMsgDiag" "No";
BA_DEF_DEF_  "GenNodeInstanceBitWidth" 0;
BA_DEF_DEF_  "GenMsgInstanced" "No";
BA_DEF_DEF_  "GenSigType" "Standard";
BA_DEF_DEF_  "GenMsgCycleTime" 0;
BA_DEF_DEF_  "GenSigSNA" 0;
BA_DEF_DEF_  "Access" "r";
BA_DEF_DEF_  "BusType" "CAN";
BA_ "GenNodeInstanceBitWidth" BU_ Battery 4;
BA_ "GenMsgDiag" BO_ 1808 1;
BA_ "GenMsgInstanced" BO_ 257 "False";
BA_ "GenMsgInstanced" BO_ 259 "False";
BA_ "GenMsgInstanced" BO_ 260 "False";
BA_ "GenMsgInstanced" BO_ 261 "False";
BA_ "GenMsgInstanced" BO_ 273 "False";
BA_ "GenMsgInstanced" BO_ 274 "False";
BA_ "GenMsgInstanced" BO_ 275 "False";
BA_ "GenMsgInstanced" BO_ 276 "False";
BA_ "GenMsgInstanced" BO_ 277 "False";
BA_ "GenMsgInstanced" BO_ 292 "False";
BA_ "GenMsgInstanced" BO_ 293 "False";
BA_ "GenMsgInstanced" BO_ 1282 "False";
BA_ "GenMsgInstanced" BO_ 1296 "False";
BA_ "GenMsgInstanced" BO_ 1632 "False";
BA_ "GenMsgInstanced" BO_ 1633 "False";
BA_ "GenMsgInstanced" BO_ 1634 "False";
BA_ "GenMsgInstanced" BO_ 1635 "False";
BA_ "GenMsgInstanced" BO_ 1636 "False";
BA_ "GenMsgInstanced" BO_ 1637 "False";
BA_ "GenMsgInstanced" BO_ 1638 "False";
BA_ "GenMsgInstanced" BO_ 1639 "False";
BA_ "GenMsgInstanced" BO_ 1640 "False";
BA_ "GenMsgInstanced" BO_ 1641 "False";
BA_ "GenMsgInstanced" BO_ 1642 "False";
BA_ "GenMsgInstanced" BO_ 1643 "False";
BA_ "GenMsgInstanced" BO_ 1808 "False";
BA_ "GenMsgInstanced" BO_ 1809 "False";
BA_ "GenMsgInstanced" BO_ 1824 "False";
BA_ "GenMsgInstanced" BO_ 1904 "False";
BA_ "GenMsgInstanced" BO_ 1905 "False";
BA_ "GenMsgInstanced" BO_ 1906 "False";
BA_ "GenMsgInstanced" BO_ 1907 "False";
BA_ "GenMsgInstanced" BO_ 1908 "False";
BA_ "GenMsgInstanced" BO_ 1909 "False";
BA_ "GenMsgInstanced" BO_ 1910 "False";
BA_ "GenMsgInstanced" BO_ 1911 "False";
BA_ "GenMsgInstanced" BO_ 1912 "False";
BA_ "GenMsgInstanced" BO_ 1913 "False";
BA_ "GenMsgInstanced" BO_ 1914 "False";
BA_ "GenMsgInstanced" BO_ 1915 "False";
BA_ "GenMsgInstanced" BO_ 1952 "False";
BA_ "GenMsgInstanced" BO_ 1953 "False";
BA_ "GenMsgInstanced" BO_ 1968 "False";
BA_ "GenMsgInstanced" BO_ 2147500032 "False";
BA_ "GenMsgInstanced" BO_ 2147516416 "False";
BA_ "GenMsgInstanced" BO_ 2147549184 "False";
BA_ "GenMsgInstanced" BO_ 2176909312 "False";
BA_ "GenMsgInstanced" BO_ 2176909313 "False";
BA_ "GenMsgInstanced" BO_ 2176909314 "False";
BA_ "GenMsgInstanced" BO_ 2176909315 "False";
BA_ "GenMsgInstanced" BO_ 2176909316 "False";
BA_ "GenMsgInstanced" BO_ 2176909317 "False";
BA_ "GenMsgInstanced" BO_ 2176909318 "False";
BA_ "GenMsgInstanced" BO_ 2176909319 "False";
BA_ "GenMsgInstanced" BO_ 2176909320 "False";
BA_ "GenMsgInstanced" BO_ 2176909321 "False";
BA_ "GenMsgInstanced" BO_ 2176909322 "False";
BA_ "GenMsgInstanced" BO_ 2176909323 "False";
BA_ "GenMsgInstanced" BO_ 2215116800 "False";
BA_ "GenMsgInstanced" BO_ 2215116801 "False";
BA_ "GenMsgInstanced" BO_ 2215116802 "False";
BA_ "GenMsgInstanced" BO_ 2215116803 "False";
BA_ "GenMsgInstanced" BO_ 2215116804 "False";
BA_ "GenMsgInstanced" BO_ 2215116805 "False";
BA_ "GenMsgInstanced" BO_ 2215116806 "False";
BA_ "GenMsgInstanced" BO_ 2215116807 "False";
BA_ "GenMsgInstanced" BO_ 2215116808 "False";
BA_ "GenMsgInstanced" BO_ 2215116809 "False";
BA_ "GenMsgInstanced" BO_ 2215116810 "False";
BA_ "GenMsgInstanced" BO_ 2215116811 "False";
BA_ "GenMsgInstanced" BO_ 2215378944 "False";
BA_ "GenMsgInstanced" BO_ 2215378945 "False";
BA_ "GenMsgInstanced" BO_ 2215378946 "False";
BA_ "GenMsgInstanced" BO_ 2215378947 "False";
BA_ "GenMsgInstanced" BO_ 2215378948 "False";
BA_ "GenMsgInstanced" BO_ 2215378949 "False";
BA_ "GenMsgInstanced" BO_ 2215378950 "False";
BA_ "GenMsgInstanced" BO_ 2215378951 "False";
BA_ "GenMsgInstanced" BO_ 2215378952 "False";
BA_ "GenMsgInstanced" BO_ 2215378953 "False";
BA_ "GenMsgInstanced" BO_ 2215378954 "False";
BA_ "GenMsgInstanced" BO_ 2215378955 "False";
BA_ "GenMsgInstanced" BO_ 2215903232 "False";
BA_ "GenMsgInstanced" BO_ 2215903233 "False";
BA_ "GenMsgInstanced" BO_ 2215903234 "False";
BA_ "GenMsgInstanced" BO_ 2215903235 "False";
BA_ "GenMsgInstanced" BO_ 2215903236 "False";
BA_ "GenMsgInstanced" BO_ 2215903237 "False";
BA_ "GenMsgInstanced" BO_ 2215903238 "False";
BA_ "GenMsgInstanced" BO_ 2215903239 "False";
BA_ "GenMsgInstanced" BO_ 2215903240 "False";
BA_ "GenMsgInstanced" BO_ 2215903241 "False";
BA_ "GenMsgInstanced" BO_ 2215903242 "False";
BA_ "GenMsgInstanced" BO_ 2215903243 "False";
BA_ "GenMsgInstanced" BO_ 2219376640 "False";
BA_ "GenMsgInstanced" BO_ 2219376641 "False";
BA_ "GenMsgInstanced" BO_ 2219376642 "False";
BA_ "GenMsgInstanced" BO_ 2219376643 "False";
BA_ "GenMsgInstanced" BO_ 2219376644 "False";
BA_ "GenMsgInstanced" BO_ 2219376645 "False";
BA_ "GenMsgInstanced" BO_ 2219376646 "False";
BA_ "GenMsgInstanced" BO_ 2219376647 "False";
BA_ "GenMsgInstanced" BO_ 2219376648 "False";
BA_ "GenMsgInstanced" BO_ 2219376649 "False";
BA_ "GenMsgInstanced" BO_ 2219376650 "False";
BA_ "GenMsgInstanced" BO_ 2219376651 "False";
BA_ "GenMsgInstanced" BO_ 2219573248 "False";
BA_ "GenMsgInstanced" BO_ 2219573249 "False";
BA_ "GenMsgInstanced" BO_ 2219573250 "False";
BA_ "GenMsgInstanced" BO_ 2219573251 "False";
BA_ "GenMsgInstanced" BO_ 2219573252 "False";
BA_ "GenMsgInstanced" BO_ 2219573253 "False";
BA_ "GenMsgInstanced" BO_ 2219573254 "False";
BA_ "GenMsgInstanced" BO_ 2219573255 "False";
BA_ "GenMsgInstanced" BO_ 2219573256 "False";
BA_ "GenMsgInstanced" BO_ 2219573257 "False";
BA_ "GenMsgInstanced" BO_ 2219573258 "False";
BA_ "GenMsgInstanced" BO_ 2219573259 "False";
BA_ "GenMsgInstanced" BO_ 2219835392 "False";
BA_ "GenMsgInstanced" BO_ 2219835393 "False";
BA_ "GenMsgInstanced" BO_ 2219835394 "False";
BA_ "GenMsgInstanced" BO_ 2219835395 "False";
BA_ "GenMsgInstanced" BO_ 2219835396 "False";
BA_ "GenMsgInstanced" BO_ 2219835397 "False";
BA_ "GenMsgInstanced" BO_ 2219835398 "False";
BA_ "GenMsgInstanced" BO_ 2219835399 "False";
BA_ "GenMsgInstanced" BO_ 2219835400 "False";
BA_ "GenMsgInstanced" BO_ 2219835401 "False";
BA_ "GenMsgInstanced" BO_ 2219835402 "False";
BA_ "GenMsgInstanced" BO_ 2219835403 "False";
BA_ "GenMsgInstanced" BO_ 2221146112 "False";
BA_ "GenMsgInstanced" BO_ 2221146113 "False";
BA_ "GenMsgInstanced" BO_ 2221146114 "False";
BA_ "GenMsgInstanced" BO_ 2221146115 "False";
BA_ "GenMsgInstanced" BO_ 2221146116 "False";
BA_ "GenMsgInstanced" BO_ 2221146117 "False";
BA_ "GenMsgInstanced" BO_ 2221146118 "False";
BA_ "GenMsgInstanced" BO_ 2221146119 "False";
BA_ "GenMsgInstanced" BO_ 2221146120 "False";
BA_ "GenMsgInstanced" BO_ 2221146121 "False";
BA_ "GenMsgInstanced" BO_ 2221146122 "False";
BA_ "GenMsgInstanced" BO_ 2221146123 "False";
BA_ "GenMsgInstanced" BO_ 2222981120 "False";
BA_ "GenMsgInstanced" BO_ 2222981121 "False";
BA_ "GenMsgInstanced" BO_ 2222981122 "False";
BA_ "GenMsgInstanced" BO_ 2222981123 "False";
BA_ "GenMsgInstanced" BO_ 2222981124 "False";
BA_ "GenMsgInstanced" BO_ 2222981125 "False";
BA_ "GenMsgInstanced" BO_ 2222981126 "False";
BA_ "GenMsgInstanced" BO_ 2222981127 "False";
BA_ "GenMsgInstanced" BO_ 2222981128 "False";
BA_ "GenMsgInstanced" BO_ 2222981129 "False";
BA_ "GenMsgInstanced" BO_ 2222981130 "False";
BA_ "GenMsgInstanced" BO_ 2222981131 "False";
BA_ "GenMsgInstanced" BO_ 2224029696 "False";
BA_ "GenMsgInstanced" BO_ 2224029697 "False";
BA_ "GenMsgInstanced" BO_ 2224029698 "False";
BA_ "GenMsgInstanced" BO_ 2224029699 "False";
BA_ "GenMsgInstanced" BO_ 2224029700 "False";
BA_ "GenMsgInstanced" BO_ 2224029701 "False";
BA_ "GenMsgInstanced" BO_ 2224029702 "False";
BA_ "GenMsgInstanced" BO_ 2224029703 "False";
BA_ "GenMsgInstanced" BO_ 2224029704 "False";
BA_ "GenMsgInstanced" BO_ 2224029705 "False";
BA_ "GenMsgInstanced" BO_ 2224029706 "False";
BA_ "GenMsgInstanced" BO_ 2224029707 "False";
BA_ "GenMsgInstanced" BO_ 2224291840 "False";
BA_ "GenMsgInstanced" BO_ 2224291841 "False";
BA_ "GenMsgInstanced" BO_ 2224291842 "False";
BA_ "GenMsgInstanced" BO_ 2224291843 "False";
BA_ "GenMsgInstanced" BO_ 2224291844 "False";
BA_ "GenMsgInstanced" BO_ 2224291845 "False";
BA_ "GenMsgCycleTime" BO_ 273 1000;
BA_ "GenMsgCycleTime" BO_ 277 1000;
BA_ "GenMsgCycleTime" BO_ 1282 1000;
BA_ "GenMsgCycleTime" BO_ 1296 1000;
BA_ "GenMsgCycleTime" BO_ 1952 1000;
BA_ "GenMsgCycleTime" BO_ 2215116800 1000;
BA_ "GenMsgCycleTime" BO_ 2215116801 1000;
BA_ "GenMsgCycleTime" BO_ 2215116802 1000;
BA_ "GenMsgCycleTime" BO_ 2215116803 1000;
BA_ "GenMsgCycleTime" BO_ 2215116804 1000;
BA_ "GenMsgCycleTime" BO_ 2215116805 1000;
BA_ "GenMsgCycleTime" BO_ 2215116806 1000;
BA_ "GenMsgCycleTime" BO_ 2215116807 1000;
BA_ "GenMsgCycleTime" BO_ 2215116808 1000;
BA_ "GenMsgCycleTime" BO_ 2215116809 1000;
BA_ "GenMsgCycleTime" BO_ 2215116810 1000;
BA_ "GenMsgCycleTime" BO_ 2215116811 1000;
BA_ "GenMsgCycleTime" BO_ 2215378944 100;
BA_ "GenMsgCycleTime" BO_ 2215378945 100;
BA_ "GenMsgCycleTime" BO_ 2215378946 100;
BA_ "GenMsgCycleTime" BO_ 2215378947 100;
BA_ "GenMsgCycleTime" BO_ 2215378948 100;
BA_ "GenMsgCycleTime" BO_ 2215378949 100;
BA_ "GenMsgCycleTime" BO_ 2215378950 100;
BA_ "GenMsgCycleTime" BO_ 2215378951 100;
BA_ "GenMsgCycleTime" BO_ 2215378952 100;
BA_ "GenMsgCycleTime" BO_ 2215378953 100;
BA_ "GenMsgCycleTime" BO_ 2215378954 100;
BA_ "GenMsgCycleTime" BO_ 2215378955 100;
BA_ "GenMsgCycleTime" BO_ 2219376640 100;
BA_ "GenMsgCycleTime" BO_ 2219376641 100;
BA_ "GenMsgCycleTime" BO_ 2219376642 100;
BA_ "GenMsgCycleTime" BO_ 2219376643 100;
BA_ "GenMsgCycleTime" BO_ 2219376644 100;
BA_ "GenMsgCycleTime" BO_ 2219376645 100;
BA_ "GenMsgCycleTime" BO_ 2219376646 100;
BA_ "GenMsgCycleTime" BO_ 2219376647 100;
BA_ "GenMsgCycleTime" BO_ 2219376648 100;
BA_ "GenMsgCycleTime" BO_ 2219376649 100;
BA_ "GenMsgCycleTime" BO_ 2219376650 100;
BA_ "GenMsgCycleTime" BO_ 2219376651 100;
BA_ "GenMsgCycleTime" BO_ 2219573248 100;
BA_ "GenMsgCycleTime" BO_ 2219573249 100;
BA_ "GenMsgCycleTime" BO_ 2219573250 100;
BA_ "GenMsgCycleTime" BO_ 2219573251 100;
BA_ "GenMsgCycleTime" BO_ 2219573252 100;
BA_ "GenMsgCycleTime" BO_ 2219573253 100;
BA_ "GenMsgCycleTime" BO_ 2219573254 100;
BA_ "GenMsgCycleTime" BO_ 2219573255 100;
BA_ "GenMsgCycleTime" BO_ 2219573256 100;
BA_ "GenMsgCycleTime" BO_ 2219573257 100;
BA_ "GenMsgCycleTime" BO_ 2219573258 100;
BA_ "GenMsgCycleTime" BO_ 2219573259 100;
BA_ "GenMsgCycleTime" BO_ 2219835392 100;
BA_ "GenMsgCycleTime" BO_ 2219835393 100;
BA_ "GenMsgCycleTime" BO_ 2219835394 100;
BA_ "GenMsgCycleTime" BO_ 2219835395 100;
BA_ "GenMsgCycleTime" BO_ 2219835396 100;
BA_ "GenMsgCycleTime" BO_ 2219835397 100;
BA_ "GenMsgCycleTime" BO_ 2219835398 100;
BA_ "GenMsgCycleTime" BO_ 2219835399 100;
BA_ "GenMsgCycleTime" BO_ 2219835400 100;
BA_ "GenMsgCycleTime" BO_ 2219835401 100;
BA_ "GenMsgCycleTime" BO_ 2219835402 100;
BA_ "GenMsgCycleTime" BO_ 2219835403 100;
BA_ "GenMsgCycleTime" BO_ 2221146112 1000;
BA_ "GenMsgCycleTime" BO_ 2221146113 1000;
BA_ "GenMsgCycleTime" BO_ 2221146114 1000;
BA_ "GenMsgCycleTime" BO_ 2221146115 1000;
BA_ "GenMsgCycleTime" BO_ 2221146116 1000;
BA_ "GenMsgCycleTime" BO_ 2221146117 1000;
BA_ "GenMsgCycleTime" BO_ 2221146118 1000;
BA_ "GenMsgCycleTime" BO_ 2221146119 1000;
BA_ "GenMsgCycleTime" BO_ 2221146120 1000;
BA_ "GenMsgCycleTime" BO_ 2221146121 1000;
BA_ "GenMsgCycleTime" BO_ 2221146122 1000;
BA_ "GenMsgCycleTime" BO_ 2221146123 1000;
BA_ "GenMsgCycleTime" BO_ 2222981120 1000;
BA_ "GenMsgCycleTime" BO_ 2222981121 1000;
BA_ "GenMsgCycleTime" BO_ 2222981122 1000;
BA_ "GenMsgCycleTime" BO_ 2222981123 1000;
BA_ "GenMsgCycleTime" BO_ 2222981124 1000;
BA_ "GenMsgCycleTime" BO_ 2222981125 1000;
BA_ "GenMsgCycleTime" BO_ 2222981126 1000;
BA_ "GenMsgCycleTime" BO_ 2222981127 1000;
BA_ "GenMsgCycleTime" BO_ 2222981128 1000;
BA_ "GenMsgCycleTime" BO_ 2222981129 1000;
BA_ "GenMsgCycleTime" BO_ 2222981130 1000;
BA_ "GenMsgCycleTime" BO_ 2222981131 1000;
BA_ "GenMsgCycleTime" BO_ 2224029696 100;
BA_ "GenMsgCycleTime" BO_ 2224029697 100;
BA_ "GenMsgCycleTime" BO_ 2224029698 100;
BA_ "GenMsgCycleTime" BO_ 2224029699 100;
BA_ "GenMsgCycleTime" BO_ 2224029700 100;
BA_ "GenMsgCycleTime" BO_ 2224029701 100;
BA_ "GenMsgCycleTime" BO_ 2224029702 100;
BA_ "GenMsgCycleTime" BO_ 2224029703 100;
BA_ "GenMsgCycleTime" BO_ 2224029704 100;
BA_ "GenMsgCycleTime" BO_ 2224029705 100;
BA_ "GenMsgCycleTime" BO_ 2224029706 100;
BA_ "GenMsgCycleTime" BO_ 2224029707 100;
BA_ "GenMsgCycleTime" BO_ 2224291840 100;
BA_ "GenMsgCycleTime" BO_ 2224291841 100;
BA_ "GenMsgCycleTime" BO_ 2224291842 100;
BA_ "GenMsgCycleTime" BO_ 2224291843 100;
BA_ "GenMsgCycleTime" BO_ 2224291844 100;
BA_ "GenMsgCycleTime" BO_ 2224291845 100;
BA_ "GenSigType" SG_ 257 BATT_chargeError 0;
BA_ "GenSigType" SG_ 257 BATT_chargeMode 0;
BA_ "GenSigType" SG_ 257 BATT_chargerMode 0;
BA_ "GenSigType" SG_ 257 BATT_chargeEnable 0;
BA_ "GenSigType" SG_ 257 BATT_chargeStatus 0;
BA_ "GenSigType" SG_ 259 BATT_fetPackDsgWelded 0;
BA_ "GenSigType" SG_ 259 BATT_fetPackChgWelded 0;
BA_ "GenSigType" SG_ 259 BATT_packState 0;
BA_ "GenSigType" SG_ 273 CHRG_chargerEnabled 0;
BA_ "GenSigType" SG_ 273 CHRG_chargingVoltage 0;
BA_ "GenSigType" SG_ 273 CHRG_chargingCurrent 0;
BA_ "GenSigType" SG_ 277 INV_current 0;
BA_ "GenSigType" SG_ 277 INV_voltage 0;
BA_ "GenSigType" SG_ 292 BATT_iPackFiltered 0;
BA_ "GenSigType" SG_ 292 BATT_vPackLoad 0;
BA_ "GenSigType" SG_ 293 BATT_tPackModuleMin 1;
BA_ "GenSigType" SG_ 293 BATT_tPackModuleMax 1;
BA_ "GenSigType" SG_ 1282 HOST_dbgInhibitContDrivePower 0;
BA_ "GenSigType" SG_ 1282 HOST_dbgResetEep 0;
BA_ "GenSigType" SG_ 1282 HOST_dbgInhibitFullPower 0;
BA_ "GenSigType" SG_ 1282 HOST_stateRequest 0;
BA_ "GenSigType" SG_ 1282 HOST_dbgInhibitRegen 0;
BA_ "GenSigType" SG_ 1282 HOST_standbyModConnectRequest 0;
BA_ "GenSigType" SG_ 1809 BATT_vPackConnBusBrickMax 1;
BA_ "GenSigType" SG_ 1809 BATT_vPackConnBusBrickMin 1;
BA_ "GenSigType" SG_ 2147516416 HOST_startNodeId 0;
BA_ "GenSigType" SG_ 2147516416 HOST_securityKey 0;
BA_ "GenSigType" SG_ 2147549184 BATT_isIgnLo_Requested 0;
BA_ "GenSigType" SG_ 2147549184 BATT_modReqCntr 0;
BA_ "GenSigType" SG_ 2147549184 BATT_stateRequest 0;
BA_ "GenSigType" SG_ 2147549184 BATT_startNodeId 0;
BA_ "GenSigType" SG_ 2215378944 BATT_vMod_0 0;
BA_ "GenSigType" SG_ 2215378944 BATT_vModSumOfCells_0 0;
BA_ "GenSigType" SG_ 2215378944 BATT_iMod_0 0;
BA_ "GenSigType" SG_ 2215378944 BATT_iModFiltered_0 0;
BA_ "GenSigType" SG_ 2215378945 BATT_vMod_1 0;
BA_ "GenSigType" SG_ 2215378945 BATT_vModSumOfCells_1 0;
BA_ "GenSigType" SG_ 2215378945 BATT_iMod_1 0;
BA_ "GenSigType" SG_ 2215378945 BATT_iModFiltered_1 0;
BA_ "GenSigType" SG_ 2215378946 BATT_vMod_2 0;
BA_ "GenSigType" SG_ 2215378946 BATT_vModSumOfCells_2 0;
BA_ "GenSigType" SG_ 2215378946 BATT_iMod_2 0;
BA_ "GenSigType" SG_ 2215378946 BATT_iModFiltered_2 0;
BA_ "GenSigType" SG_ 2215378947 BATT_vMod_3 0;
BA_ "GenSigType" SG_ 2215378947 BATT_vModSumOfCells_3 0;
BA_ "GenSigType" SG_ 2215378947 BATT_iMod_3 0;
BA_ "GenSigType" SG_ 2215378947 BATT_iModFiltered_3 0;
BA_ "GenSigType" SG_ 2215378948 BATT_vMod_4 0;
BA_ "GenSigType" SG_ 2215378948 BATT_vModSumOfCells_4 0;
BA_ "GenSigType" SG_ 2215378948 BATT_iMod_4 0;
BA_ "GenSigType" SG_ 2215378948 BATT_iModFiltered_4 0;
BA_ "GenSigType" SG_ 2215378949 BATT_vMod_5 0;
BA_ "GenSigType" SG_ 2215378949 BATT_vModSumOfCells_5 0;
BA_ "GenSigType" SG_ 2215378949 BATT_iMod_5 0;
BA_ "GenSigType" SG_ 2215378949 BATT_iModFiltered_5 0;
BA_ "GenSigType" SG_ 2215378950 BATT_vMod_6 0;
BA_ "GenSigType" SG_ 2215378950 BATT_vModSumOfCells_6 0;
BA_ "GenSigType" SG_ 2215378950 BATT_iMod_6 0;
BA_ "GenSigType" SG_ 2215378950 BATT_iModFiltered_6 0;
BA_ "GenSigType" SG_ 2215378951 BATT_vMod_7 0;
BA_ "GenSigType" SG_ 2215378951 BATT_vModSumOfCells_7 0;
BA_ "GenSigType" SG_ 2215378951 BATT_iMod_7 0;
BA_ "GenSigType" SG_ 2215378951 BATT_iModFiltered_7 0;
BA_ "GenSigType" SG_ 2215378952 BATT_vMod_8 0;
BA_ "GenSigType" SG_ 2215378952 BATT_vModSumOfCells_8 0;
BA_ "GenSigType" SG_ 2215378952 BATT_iMod_8 0;
BA_ "GenSigType" SG_ 2215378952 BATT_iModFiltered_8 0;
BA_ "GenSigType" SG_ 2215378953 BATT_vMod_9 0;
BA_ "GenSigType" SG_ 2215378953 BATT_vModSumOfCells_9 0;
BA_ "GenSigType" SG_ 2215378953 BATT_iMod_9 0;
BA_ "GenSigType" SG_ 2215378953 BATT_iModFiltered_9 0;
BA_ "GenSigType" SG_ 2215378954 BATT_vMod_10 0;
BA_ "GenSigType" SG_ 2215378954 BATT_vModSumOfCells_10 0;
BA_ "GenSigType" SG_ 2215378954 BATT_iMod_10 0;
BA_ "GenSigType" SG_ 2215378954 BATT_iModFiltered_10 0;
BA_ "GenSigType" SG_ 2215378955 BATT_vMod_11 0;
BA_ "GenSigType" SG_ 2215378955 BATT_vModSumOfCells_11 0;
BA_ "GenSigType" SG_ 2215378955 BATT_iMod_11 0;
BA_ "GenSigType" SG_ 2215378955 BATT_iModFiltered_11 0;
BA_ "GenSigType" SG_ 2215903232 BATT_sohcMod_0 0;
BA_ "GenSigType" SG_ 2215903232 BATT_socMod_0 0;
BA_ "GenSigType" SG_ 2215903232 BATT_idSOCLimiting_0 0;
BA_ "GenSigType" SG_ 2215903232 BATT_socLimiting_0 0;
BA_ "GenSigType" SG_ 2215903233 BATT_sohcMod_1 0;
BA_ "GenSigType" SG_ 2215903233 BATT_socLimiting_1 0;
BA_ "GenSigType" SG_ 2215903233 BATT_idSOCLimiting_1 0;
BA_ "GenSigType" SG_ 2215903233 BATT_socMod_1 0;
BA_ "GenSigType" SG_ 2215903234 BATT_sohcMod_2 0;
BA_ "GenSigType" SG_ 2215903234 BATT_socMod_2 0;
BA_ "GenSigType" SG_ 2215903234 BATT_socLimiting_2 0;
BA_ "GenSigType" SG_ 2215903234 BATT_idSOCLimiting_2 0;
BA_ "GenSigType" SG_ 2215903235 BATT_sohcMod_3 0;
BA_ "GenSigType" SG_ 2215903235 BATT_socMod_3 0;
BA_ "GenSigType" SG_ 2215903235 BATT_socLimiting_3 0;
BA_ "GenSigType" SG_ 2215903235 BATT_idSOCLimiting_3 0;
BA_ "GenSigType" SG_ 2215903236 BATT_socMod_4 0;
BA_ "GenSigType" SG_ 2215903236 BATT_socLimiting_4 0;
BA_ "GenSigType" SG_ 2215903236 BATT_idSOCLimiting_4 0;
BA_ "GenSigType" SG_ 2215903236 BATT_sohcMod_4 0;
BA_ "GenSigType" SG_ 2215903237 BATT_sohcMod_5 0;
BA_ "GenSigType" SG_ 2215903237 BATT_socMod_5 0;
BA_ "GenSigType" SG_ 2215903237 BATT_socLimiting_5 0;
BA_ "GenSigType" SG_ 2215903237 BATT_idSOCLimiting_5 0;
BA_ "GenSigType" SG_ 2215903238 BATT_sohcMod_6 0;
BA_ "GenSigType" SG_ 2215903238 BATT_socMod_6 0;
BA_ "GenSigType" SG_ 2215903238 BATT_socLimiting_6 0;
BA_ "GenSigType" SG_ 2215903238 BATT_idSOCLimiting_6 0;
BA_ "GenSigType" SG_ 2215903239 BATT_sohcMod_7 0;
BA_ "GenSigType" SG_ 2215903239 BATT_socMod_7 0;
BA_ "GenSigType" SG_ 2215903239 BATT_socLimiting_7 0;
BA_ "GenSigType" SG_ 2215903239 BATT_idSOCLimiting_7 0;
BA_ "GenSigType" SG_ 2215903240 BATT_sohcMod_8 0;
BA_ "GenSigType" SG_ 2215903240 BATT_socMod_8 0;
BA_ "GenSigType" SG_ 2215903240 BATT_socLimiting_8 0;
BA_ "GenSigType" SG_ 2215903240 BATT_idSOCLimiting_8 0;
BA_ "GenSigType" SG_ 2215903241 BATT_sohcMod_9 0;
BA_ "GenSigType" SG_ 2215903241 BATT_socMod_9 0;
BA_ "GenSigType" SG_ 2215903241 BATT_socLimiting_9 0;
BA_ "GenSigType" SG_ 2215903241 BATT_idSOCLimiting_9 0;
BA_ "GenSigType" SG_ 2215903242 BATT_sohcMod_10 0;
BA_ "GenSigType" SG_ 2215903242 BATT_socMod_10 0;
BA_ "GenSigType" SG_ 2215903242 BATT_socLimiting_10 0;
BA_ "GenSigType" SG_ 2215903242 BATT_idSOCLimiting_10 0;
BA_ "GenSigType" SG_ 2215903243 BATT_sohcMod_11 0;
BA_ "GenSigType" SG_ 2215903243 BATT_socMod_11 0;
BA_ "GenSigType" SG_ 2215903243 BATT_socLimiting_11 0;
BA_ "GenSigType" SG_ 2215903243 BATT_idSOCLimiting_11 0;
BA_ "GenSigType" SG_ 2219376640 BATT_vModChgLimit_0 0;
BA_ "GenSigType" SG_ 2219376640 BATT_iModChgLimitInst_0 0;
BA_ "GenSigType" SG_ 2219376640 BATT_iModChgLimit10s_0 0;
BA_ "GenSigType" SG_ 2219376640 BATT_iModChgLimitCont_0 0;
BA_ "GenSigType" SG_ 2219376641 BATT_vModChgLimit_1 0;
BA_ "GenSigType" SG_ 2219376641 BATT_iModChgLimitInst_1 0;
BA_ "GenSigType" SG_ 2219376641 BATT_iModChgLimit10s_1 0;
BA_ "GenSigType" SG_ 2219376641 BATT_iModChgLimitCont_1 0;
BA_ "GenSigType" SG_ 2219376642 BATT_vModChgLimit_2 0;
BA_ "GenSigType" SG_ 2219376642 BATT_iModChgLimitInst_2 0;
BA_ "GenSigType" SG_ 2219376642 BATT_iModChgLimit10s_2 0;
BA_ "GenSigType" SG_ 2219376642 BATT_iModChgLimitCont_2 0;
BA_ "GenSigType" SG_ 2219376643 BATT_vModChgLimit_3 0;
BA_ "GenSigType" SG_ 2219376643 BATT_iModChgLimitInst_3 0;
BA_ "GenSigType" SG_ 2219376643 BATT_iModChgLimit10s_3 0;
BA_ "GenSigType" SG_ 2219376643 BATT_iModChgLimitCont_3 0;
BA_ "GenSigType" SG_ 2219376644 BATT_vModChgLimit_4 0;
BA_ "GenSigType" SG_ 2219376644 BATT_iModChgLimitInst_4 0;
BA_ "GenSigType" SG_ 2219376644 BATT_iModChgLimit10s_4 0;
BA_ "GenSigType" SG_ 2219376644 BATT_iModChgLimitCont_4 0;
BA_ "GenSigType" SG_ 2219376645 BATT_vModChgLimit_5 0;
BA_ "GenSigType" SG_ 2219376645 BATT_iModChgLimitInst_5 0;
BA_ "GenSigType" SG_ 2219376645 BATT_iModChgLimit10s_5 0;
BA_ "GenSigType" SG_ 2219376645 BATT_iModChgLimitCont_5 0;
BA_ "GenSigType" SG_ 2219376646 BATT_vModChgLimit_6 0;
BA_ "GenSigType" SG_ 2219376646 BATT_iModChgLimitInst_6 0;
BA_ "GenSigType" SG_ 2219376646 BATT_iModChgLimit10s_6 0;
BA_ "GenSigType" SG_ 2219376646 BATT_iModChgLimitCont_6 0;
BA_ "GenSigType" SG_ 2219376647 BATT_vModChgLimit_7 0;
BA_ "GenSigType" SG_ 2219376647 BATT_iModChgLimitInst_7 0;
BA_ "GenSigType" SG_ 2219376647 BATT_iModChgLimit10s_7 0;
BA_ "GenSigType" SG_ 2219376647 BATT_iModChgLimitCont_7 0;
BA_ "GenSigType" SG_ 2219376648 BATT_vModChgLimit_8 0;
BA_ "GenSigType" SG_ 2219376648 BATT_iModChgLimitInst_8 0;
BA_ "GenSigType" SG_ 2219376648 BATT_iModChgLimit10s_8 0;
BA_ "GenSigType" SG_ 2219376648 BATT_iModChgLimitCont_8 0;
BA_ "GenSigType" SG_ 2219376649 BATT_vModChgLimit_9 0;
BA_ "GenSigType" SG_ 2219376649 BATT_iModChgLimitInst_9 0;
BA_ "GenSigType" SG_ 2219376649 BATT_iModChgLimit10s_9 0;
BA_ "GenSigType" SG_ 2219376649 BATT_iModChgLimitCont_9 0;
BA_ "GenSigType" SG_ 2219376650 BATT_vModChgLimit_10 0;
BA_ "GenSigType" SG_ 2219376650 BATT_iModChgLimitInst_10 0;
BA_ "GenSigType" SG_ 2219376650 BATT_iModChgLimit10s_10 0;
BA_ "GenSigType" SG_ 2219376650 BATT_iModChgLimitCont_10 0;
BA_ "GenSigType" SG_ 2219376651 BATT_vModChgLimit_11 0;
BA_ "GenSigType" SG_ 2219376651 BATT_iModChgLimitInst_11 0;
BA_ "GenSigType" SG_ 2219376651 BATT_iModChgLimit10s_11 0;
BA_ "GenSigType" SG_ 2219376651 BATT_iModChgLimitCont_11 0;
BA_ "GenSigType" SG_ 2219573248 BATT_iModDchLimitCont_0 0;
BA_ "GenSigType" SG_ 2219573248 BATT_iModDchLimitInst_0 0;
BA_ "GenSigType" SG_ 2219573248 BATT_vModDchLimit_0 0;
BA_ "GenSigType" SG_ 2219573249 BATT_iModDchLimitInst_1 0;
BA_ "GenSigType" SG_ 2219573249 BATT_vModDchLimit_1 0;
BA_ "GenSigType" SG_ 2219573249 BATT_iModDchLimitCont_1 0;
BA_ "GenSigType" SG_ 2219573250 BATT_vModDchLimit_2 0;
BA_ "GenSigType" SG_ 2219573250 BATT_iModDchLimitInst_2 0;
BA_ "GenSigType" SG_ 2219573250 BATT_iModDchLimitCont_2 0;
BA_ "GenSigType" SG_ 2219573251 BATT_vModDchLimit_3 0;
BA_ "GenSigType" SG_ 2219573251 BATT_iModDchLimitCont_3 0;
BA_ "GenSigType" SG_ 2219573251 BATT_iModDchLimitInst_3 0;
BA_ "GenSigType" SG_ 2219573252 BATT_iModDchLimitInst_4 0;
BA_ "GenSigType" SG_ 2219573252 BATT_vModDchLimit_4 0;
BA_ "GenSigType" SG_ 2219573252 BATT_iModDchLimitCont_4 0;
BA_ "GenSigType" SG_ 2219573253 BATT_vModDchLimit_5 0;
BA_ "GenSigType" SG_ 2219573253 BATT_iModDchLimitInst_5 0;
BA_ "GenSigType" SG_ 2219573253 BATT_iModDchLimitCont_5 0;
BA_ "GenSigType" SG_ 2219573254 BATT_iModDchLimitInst_6 0;
BA_ "GenSigType" SG_ 2219573254 BATT_iModDchLimitCont_6 0;
BA_ "GenSigType" SG_ 2219573254 BATT_vModDchLimit_6 0;
BA_ "GenSigType" SG_ 2219573255 BATT_iModDchLimitCont_7 0;
BA_ "GenSigType" SG_ 2219573255 BATT_iModDchLimitInst_7 0;
BA_ "GenSigType" SG_ 2219573255 BATT_vModDchLimit_7 0;
BA_ "GenSigType" SG_ 2219573256 BATT_iModDchLimitInst_8 0;
BA_ "GenSigType" SG_ 2219573256 BATT_iModDchLimitCont_8 0;
BA_ "GenSigType" SG_ 2219573256 BATT_vModDchLimit_8 0;
BA_ "GenSigType" SG_ 2219573257 BATT_vModDchLimit_9 0;
BA_ "GenSigType" SG_ 2219573257 BATT_iModDchLimitInst_9 0;
BA_ "GenSigType" SG_ 2219573257 BATT_iModDchLimitCont_9 0;
BA_ "GenSigType" SG_ 2219573258 BATT_vModDchLimit_10 0;
BA_ "GenSigType" SG_ 2219573258 BATT_iModDchLimitInst_10 0;
BA_ "GenSigType" SG_ 2219573258 BATT_iModDchLimitCont_10 0;
BA_ "GenSigType" SG_ 2219573259 BATT_vModDchLimit_11 0;
BA_ "GenSigType" SG_ 2219573259 BATT_iModDchLimitCont_11 0;
BA_ "GenSigType" SG_ 2219573259 BATT_iModDchLimitInst_11 0;
BA_ "GenSigType" SG_ 2219835392 BATT_pwrModDchLimit_0 0;
BA_ "GenSigType" SG_ 2219835392 BATT_pwrModChgLimit_0 0;
BA_ "GenSigType" SG_ 2219835393 BATT_pwrModDchLimit_1 0;
BA_ "GenSigType" SG_ 2219835393 BATT_pwrModChgLimit_1 0;
BA_ "GenSigType" SG_ 2219835394 BATT_pwrModDchLimit_2 0;
BA_ "GenSigType" SG_ 2219835394 BATT_pwrModChgLimit_2 0;
BA_ "GenSigType" SG_ 2219835395 BATT_pwrModDchLimit_3 0;
BA_ "GenSigType" SG_ 2219835395 BATT_pwrModChgLimit_3 0;
BA_ "GenSigType" SG_ 2219835396 BATT_pwrModDchLimit_4 0;
BA_ "GenSigType" SG_ 2219835396 BATT_pwrModChgLimit_4 0;
BA_ "GenSigType" SG_ 2219835397 BATT_pwrModDchLimit_5 0;
BA_ "GenSigType" SG_ 2219835397 BATT_pwrModChgLimit_5 0;
BA_ "GenSigType" SG_ 2219835398 BATT_pwrModDchLimit_6 0;
BA_ "GenSigType" SG_ 2219835398 BATT_pwrModChgLimit_6 0;
BA_ "GenSigType" SG_ 2219835399 BATT_pwrModDchLimit_7 0;
BA_ "GenSigType" SG_ 2219835399 BATT_pwrModChgLimit_7 0;
BA_ "GenSigType" SG_ 2219835400 BATT_pwrModDchLimit_8 0;
BA_ "GenSigType" SG_ 2219835400 BATT_pwrModChgLimit_8 0;
BA_ "GenSigType" SG_ 2219835401 BATT_pwrModDchLimit_9 0;
BA_ "GenSigType" SG_ 2219835401 BATT_pwrModChgLimit_9 0;
BA_ "GenSigType" SG_ 2219835402 BATT_pwrModDchLimit_10 0;
BA_ "GenSigType" SG_ 2219835402 BATT_pwrModChgLimit_10 0;
BA_ "GenSigType" SG_ 2219835403 BATT_pwrModDchLimit_11 0;
BA_ "GenSigType" SG_ 2219835403 BATT_pwrModChgLimit_11 0;
BA_ "GenSigType" SG_ 2221146112 BATT_tModule2_0 0;
BA_ "GenSigType" SG_ 2221146112 BATT_tModule1_0 0;
BA_ "GenSigType" SG_ 2221146112 BATT_tAmbient_0 0;
BA_ "GenSigType" SG_ 2221146113 BATT_tModule2_1 0;
BA_ "GenSigType" SG_ 2221146113 BATT_tModule1_1 0;
BA_ "GenSigType" SG_ 2221146113 BATT_tAmbient_1 0;
BA_ "GenSigType" SG_ 2221146114 BATT_tModule1_2 0;
BA_ "GenSigType" SG_ 2221146114 BATT_tModule2_2 0;
BA_ "GenSigType" SG_ 2221146114 BATT_tAmbient_2 0;
BA_ "GenSigType" SG_ 2221146115 BATT_tModule2_3 0;
BA_ "GenSigType" SG_ 2221146115 BATT_tModule1_3 0;
BA_ "GenSigType" SG_ 2221146115 BATT_tAmbient_3 0;
BA_ "GenSigType" SG_ 2221146116 BATT_tModule2_4 0;
BA_ "GenSigType" SG_ 2221146116 BATT_tModule1_4 0;
BA_ "GenSigType" SG_ 2221146116 BATT_tAmbient_4 0;
BA_ "GenSigType" SG_ 2221146117 BATT_tModule2_5 0;
BA_ "GenSigType" SG_ 2221146117 BATT_tModule1_5 0;
BA_ "GenSigType" SG_ 2221146117 BATT_tAmbient_5 0;
BA_ "GenSigType" SG_ 2221146118 BATT_tAmbient_6 0;
BA_ "GenSigType" SG_ 2221146118 BATT_tModule2_6 0;
BA_ "GenSigType" SG_ 2221146118 BATT_tModule1_6 0;
BA_ "GenSigType" SG_ 2221146119 BATT_tModule2_7 0;
BA_ "GenSigType" SG_ 2221146119 BATT_tModule1_7 0;
BA_ "GenSigType" SG_ 2221146119 BATT_tAmbient_7 0;
BA_ "GenSigType" SG_ 2221146120 BATT_tModule2_8 0;
BA_ "GenSigType" SG_ 2221146120 BATT_tModule1_8 0;
BA_ "GenSigType" SG_ 2221146120 BATT_tAmbient_8 0;
BA_ "GenSigType" SG_ 2221146121 BATT_tModule1_9 0;
BA_ "GenSigType" SG_ 2221146121 BATT_tModule2_9 0;
BA_ "GenSigType" SG_ 2221146121 BATT_tAmbient_9 0;
BA_ "GenSigType" SG_ 2221146122 BATT_tAmbient_10 0;
BA_ "GenSigType" SG_ 2221146122 BATT_tModule2_10 0;
BA_ "GenSigType" SG_ 2221146122 BATT_tModule1_10 0;
BA_ "GenSigType" SG_ 2221146123 BATT_tModule1_11 0;
BA_ "GenSigType" SG_ 2221146123 BATT_tAmbient_11 0;
BA_ "GenSigType" SG_ 2221146123 BATT_tModule2_11 0;
BA_ "GenSigType" SG_ 2222981120 BATT_tShunt_0 0;
BA_ "GenSigType" SG_ 2222981120 BATT_tFET_0 0;
BA_ "GenSigType" SG_ 2222981121 BATT_tShunt_1 0;
BA_ "GenSigType" SG_ 2222981121 BATT_tFET_1 0;
BA_ "GenSigType" SG_ 2222981122 BATT_tShunt_2 0;
BA_ "GenSigType" SG_ 2222981122 BATT_tFET_2 0;
BA_ "GenSigType" SG_ 2222981123 BATT_tShunt_3 0;
BA_ "GenSigType" SG_ 2222981123 BATT_tFET_3 0;
BA_ "GenSigType" SG_ 2222981124 BATT_tShunt_4 0;
BA_ "GenSigType" SG_ 2222981124 BATT_tFET_4 0;
BA_ "GenSigType" SG_ 2222981125 BATT_tShunt_5 0;
BA_ "GenSigType" SG_ 2222981125 BATT_tFET_5 0;
BA_ "GenSigType" SG_ 2222981126 BATT_tShunt_6 0;
BA_ "GenSigType" SG_ 2222981126 BATT_tFET_6 0;
BA_ "GenSigType" SG_ 2222981127 BATT_tShunt_7 0;
BA_ "GenSigType" SG_ 2222981127 BATT_tFET_7 0;
BA_ "GenSigType" SG_ 2222981128 BATT_tShunt_8 0;
BA_ "GenSigType" SG_ 2222981128 BATT_tFET_8 0;
BA_ "GenSigType" SG_ 2222981129 BATT_tShunt_9 0;
BA_ "GenSigType" SG_ 2222981129 BATT_tFET_9 0;
BA_ "GenSigType" SG_ 2222981130 BATT_tShunt_10 0;
BA_ "GenSigType" SG_ 2222981130 BATT_tFET_10 0;
BA_ "GenSigType" SG_ 2222981131 BATT_tShunt_11 0;
BA_ "GenSigType" SG_ 2222981131 BATT_tFET_11 0;
BA_ "GenSigType" SG_ 2224029696 BATT_resMod_0 0;
BA_ "GenSigType" SG_ 2224029696 BATT_voirMod_0 0;
BA_ "GenSigType" SG_ 2224029696 BATT_vModLoad_0 0;
BA_ "GenSigType" SG_ 2224029697 BATT_resMod_1 0;
BA_ "GenSigType" SG_ 2224029697 BATT_voirMod_1 0;
BA_ "GenSigType" SG_ 2224029697 BATT_vModLoad_1 0;
BA_ "GenSigType" SG_ 2224029698 BATT_resMod_2 0;
BA_ "GenSigType" SG_ 2224029698 BATT_voirMod_2 0;
BA_ "GenSigType" SG_ 2224029698 BATT_vModLoad_2 0;
BA_ "GenSigType" SG_ 2224029699 BATT_resMod_3 0;
BA_ "GenSigType" SG_ 2224029699 BATT_voirMod_3 0;
BA_ "GenSigType" SG_ 2224029699 BATT_vModLoad_3 0;
BA_ "GenSigType" SG_ 2224029700 BATT_resMod_4 0;
BA_ "GenSigType" SG_ 2224029700 BATT_voirMod_4 0;
BA_ "GenSigType" SG_ 2224029700 BATT_vModLoad_4 0;
BA_ "GenSigType" SG_ 2224029701 BATT_resMod_5 0;
BA_ "GenSigType" SG_ 2224029701 BATT_voirMod_5 0;
BA_ "GenSigType" SG_ 2224029701 BATT_vModLoad_5 0;
BA_ "GenSigType" SG_ 2224029702 BATT_resMod_6 0;
BA_ "GenSigType" SG_ 2224029702 BATT_voirMod_6 0;
BA_ "GenSigType" SG_ 2224029702 BATT_vModLoad_6 0;
BA_ "GenSigType" SG_ 2224029703 BATT_resMod_7 0;
BA_ "GenSigType" SG_ 2224029703 BATT_voirMod_7 0;
BA_ "GenSigType" SG_ 2224029703 BATT_vModLoad_7 0;
BA_ "GenSigType" SG_ 2224029704 BATT_resMod_8 0;
BA_ "GenSigType" SG_ 2224029704 BATT_voirMod_8 0;
BA_ "GenSigType" SG_ 2224029704 BATT_vModLoad_8 0;
BA_ "GenSigType" SG_ 2224029705 BATT_resMod_9 0;
BA_ "GenSigType" SG_ 2224029705 BATT_voirMod_9 0;
BA_ "GenSigType" SG_ 2224029705 BATT_vModLoad_9 0;
BA_ "GenSigType" SG_ 2224029706 BATT_resMod_10 0;
BA_ "GenSigType" SG_ 2224029706 BATT_voirMod_10 0;
BA_ "GenSigType" SG_ 2224029706 BATT_vModLoad_10 0;
BA_ "GenSigType" SG_ 2224029707 BATT_resMod_11 0;
BA_ "GenSigType" SG_ 2224029707 BATT_voirMod_11 0;
BA_ "GenSigType" SG_ 2224029707 BATT_vModLoad_11 0;
BA_ "GenSigType" SG_ 2224291840 BATT_vBrickMax_0 0;
BA_ "GenSigType" SG_ 2224291840 BATT_tModuleMax_0 0;
BA_ "GenSigType" SG_ 2224291840 BATT_tModuleMin_0 0;
BA_ "GenSigType" SG_ 2224291840 BATT_vBrickMinID_0 0;
BA_ "GenSigType" SG_ 2224291840 BATT_vBrickMin_0 0;
BA_ "GenSigType" SG_ 2224291840 BATT_tModuleMinID_0 0;
BA_ "GenSigType" SG_ 2224291840 BATT_vBrickMaxID_0 0;
BA_ "GenSigType" SG_ 2224291840 BATT_tModuleMaxID_0 0;
BA_ "GenSigType" SG_ 2224291841 BATT_vBrickMinID_1 0;
BA_ "GenSigType" SG_ 2224291841 BATT_vBrickMax_1 0;
BA_ "GenSigType" SG_ 2224291841 BATT_vBrickMin_1 0;
BA_ "GenSigType" SG_ 2224291841 BATT_tModuleMinID_1 0;
BA_ "GenSigType" SG_ 2224291841 BATT_vBrickMaxID_1 0;
BA_ "GenSigType" SG_ 2224291841 BATT_tModuleMin_1 0;
BA_ "GenSigType" SG_ 2224291841 BATT_tModuleMaxID_1 0;
BA_ "GenSigType" SG_ 2224291841 BATT_tModuleMax_1 0;
BA_ "GenSigType" SG_ 2224291842 BATT_tModuleMaxID_2 0;
BA_ "GenSigType" SG_ 2224291842 BATT_vBrickMaxID_2 0;
BA_ "GenSigType" SG_ 2224291842 BATT_tModuleMinID_2 0;
BA_ "GenSigType" SG_ 2224291842 BATT_tModuleMin_2 0;
BA_ "GenSigType" SG_ 2224291842 BATT_vBrickMinID_2 0;
BA_ "GenSigType" SG_ 2224291842 BATT_tModuleMax_2 0;
BA_ "GenSigType" SG_ 2224291842 BATT_vBrickMin_2 0;
BA_ "GenSigType" SG_ 2224291842 BATT_vBrickMax_2 0;
BA_ "GenSigType" SG_ 2224291843 BATT_vBrickMinID_3 0;
BA_ "GenSigType" SG_ 2224291843 BATT_tModuleMaxID_3 0;
BA_ "GenSigType" SG_ 2224291843 BATT_tModuleMinID_3 0;
BA_ "GenSigType" SG_ 2224291843 BATT_tModuleMax_3 0;
BA_ "GenSigType" SG_ 2224291843 BATT_vBrickMaxID_3 0;
BA_ "GenSigType" SG_ 2224291843 BATT_vBrickMax_3 0;
BA_ "GenSigType" SG_ 2224291843 BATT_vBrickMin_3 0;
BA_ "GenSigType" SG_ 2224291843 BATT_tModuleMin_3 0;
BA_ "GenSigType" SG_ 2224291844 BATT_vBrickMax_4 0;
BA_ "GenSigType" SG_ 2224291844 BATT_vBrickMin_4 0;
BA_ "GenSigType" SG_ 2224291844 BATT_vBrickMinID_4 0;
BA_ "GenSigType" SG_ 2224291844 BATT_tModuleMaxID_4 0;
BA_ "GenSigType" SG_ 2224291844 BATT_tModuleMinID_4 0;
BA_ "GenSigType" SG_ 2224291844 BATT_vBrickMaxID_4 0;
BA_ "GenSigType" SG_ 2224291844 BATT_tModuleMax_4 0;
BA_ "GenSigType" SG_ 2224291844 BATT_tModuleMin_4 0;
BA_ "GenSigType" SG_ 2224291845 BATT_tModuleMaxID_5 0;
BA_ "GenSigType" SG_ 2224291845 BATT_tModuleMinID_5 0;
BA_ "GenSigType" SG_ 2224291845 BATT_vBrickMaxID_5 0;
BA_ "GenSigType" SG_ 2224291845 BATT_tModuleMax_5 0;
BA_ "GenSigType" SG_ 2224291845 BATT_tModuleMin_5 0;
BA_ "GenSigType" SG_ 2224291845 BATT_vBrickMinID_5 0;
BA_ "GenSigType" SG_ 2224291845 BATT_vBrickMin_5 0;
BA_ "GenSigType" SG_ 2224291845 BATT_vBrickMax_5 0;
BA_ "GenSigSNA" SG_ 260 BATT_packRemainingCap_Ah 65535;
BA_ "GenSigSNA" SG_ 260 BATT_packFullChargeCap_Ah 65535;
BA_ "GenSigSNA" SG_ 261 BATT_packUserSOC 65535;
BA_ "GenSigSNA" SG_ 261 BATT_packSOC 65535;
BA_ "GenSigSNA" SG_ 274 BATT_iPackChgLimitInst 65535;
BA_ "GenSigSNA" SG_ 274 BATT_iPackChgLimitCont 65535;
BA_ "GenSigSNA" SG_ 274 BATT_iPackChgLimit10s 65535;
BA_ "GenSigSNA" SG_ 274 BATT_vBusMax 65535;
BA_ "GenSigSNA" SG_ 275 BATT_iPackDchLimit10s 32767;
BA_ "GenSigSNA" SG_ 275 BATT_vBusMin 65535;
BA_ "GenSigSNA" SG_ 275 BATT_iPackDchLimitCont 32767;
BA_ "GenSigSNA" SG_ 275 BATT_iPackDchLimitInst 32767;
BA_ "GenSigSNA" SG_ 276 BATT_pwrPackChgLimit 65535;
BA_ "GenSigSNA" SG_ 276 BATT_pwrPackDchLimit 65535;
BA_ "GenSigSNA" SG_ 292 BATT_iPackFiltered 32767;
BA_ "GenSigSNA" SG_ 292 BATT_vPackLoad 65535;
BA_ "GenSigSNA" SG_ 292 BATT_iPack 32767;
BA_ "GenSigSNA" SG_ 292 BATT_vPack 65535;
BA_ "GenSigSNA" SG_ 293 BATT_tPackModuleMinID 15;
BA_ "GenSigSNA" SG_ 293 BATT_tPackModuleMin 2047;
BA_ "GenSigSNA" SG_ 293 BATT_vPackBrickMin 4095;
BA_ "GenSigSNA" SG_ 293 BATT_vPackBrickMax 4095;
BA_ "GenSigSNA" SG_ 293 BATT_vPackModuleMinID 15;
BA_ "GenSigSNA" SG_ 293 BATT_tPackModuleMax 2047;
BA_ "GenSigSNA" SG_ 293 BATT_vPackModuleMaxID 15;
BA_ "GenSigSNA" SG_ 293 BATT_tPackModuleMaxID 15;
BA_ "GenSigSNA" SG_ 1809 BATT_vPackConnBusBrickMax 4095;
BA_ "GenSigSNA" SG_ 1809 BATT_packConnBusSOC 65535;
BA_ "GenSigSNA" SG_ 1809 BATT_vPackConnBusBrickMin 4095;
BA_ "GenSigSNA" SG_ 2215116800 BATT_modFullChargeCap_Ah_0 65535;
BA_ "GenSigSNA" SG_ 2215116800 BATT_modRemainingCap_Ah_0 65535;
BA_ "GenSigSNA" SG_ 2215116801 BATT_modFullChargeCap_Ah_1 65535;
BA_ "GenSigSNA" SG_ 2215116801 BATT_modRemainingCap_Ah_1 65535;
BA_ "GenSigSNA" SG_ 2215116802 BATT_modFullChargeCap_Ah_2 65535;
BA_ "GenSigSNA" SG_ 2215116802 BATT_modRemainingCap_Ah_2 65535;
BA_ "GenSigSNA" SG_ 2215116803 BATT_modFullChargeCap_Ah_3 65535;
BA_ "GenSigSNA" SG_ 2215116803 BATT_modRemainingCap_Ah_3 65535;
BA_ "GenSigSNA" SG_ 2215116804 BATT_modFullChargeCap_Ah_4 65535;
BA_ "GenSigSNA" SG_ 2215116804 BATT_modRemainingCap_Ah_4 65535;
BA_ "GenSigSNA" SG_ 2215116805 BATT_modFullChargeCap_Ah_5 65535;
BA_ "GenSigSNA" SG_ 2215116805 BATT_modRemainingCap_Ah_5 65535;
BA_ "GenSigSNA" SG_ 2215116806 BATT_modFullChargeCap_Ah_6 65535;
BA_ "GenSigSNA" SG_ 2215116806 BATT_modRemainingCap_Ah_6 65535;
BA_ "GenSigSNA" SG_ 2215116807 BATT_modFullChargeCap_Ah_7 65535;
BA_ "GenSigSNA" SG_ 2215116807 BATT_modRemainingCap_Ah_7 65535;
BA_ "GenSigSNA" SG_ 2215116808 BATT_modFullChargeCap_Ah_8 65535;
BA_ "GenSigSNA" SG_ 2215116808 BATT_modRemainingCap_Ah_8 65535;
BA_ "GenSigSNA" SG_ 2215116809 BATT_modFullChargeCap_Ah_9 65535;
BA_ "GenSigSNA" SG_ 2215116809 BATT_modRemainingCap_Ah_9 65535;
BA_ "GenSigSNA" SG_ 2215116810 BATT_modFullChargeCap_Ah_10 65535;
BA_ "GenSigSNA" SG_ 2215116810 BATT_modRemainingCap_Ah_10 65535;
BA_ "GenSigSNA" SG_ 2215116811 BATT_modFullChargeCap_Ah_11 65535;
BA_ "GenSigSNA" SG_ 2215116811 BATT_modRemainingCap_Ah_11 65535;
BA_ "GenSigSNA" SG_ 2215378944 BATT_vMod_0 65535;
BA_ "GenSigSNA" SG_ 2215378944 BATT_vModSumOfCells_0 65535;
BA_ "GenSigSNA" SG_ 2215378944 BATT_iMod_0 32767;
BA_ "GenSigSNA" SG_ 2215378944 BATT_iModFiltered_0 32767;
BA_ "GenSigSNA" SG_ 2215378945 BATT_vMod_1 65535;
BA_ "GenSigSNA" SG_ 2215378945 BATT_vModSumOfCells_1 65535;
BA_ "GenSigSNA" SG_ 2215378945 BATT_iMod_1 32767;
BA_ "GenSigSNA" SG_ 2215378945 BATT_iModFiltered_1 32767;
BA_ "GenSigSNA" SG_ 2215378946 BATT_vMod_2 65535;
BA_ "GenSigSNA" SG_ 2215378946 BATT_vModSumOfCells_2 65535;
BA_ "GenSigSNA" SG_ 2215378946 BATT_iMod_2 32767;
BA_ "GenSigSNA" SG_ 2215378946 BATT_iModFiltered_2 32767;
BA_ "GenSigSNA" SG_ 2215378947 BATT_vMod_3 65535;
BA_ "GenSigSNA" SG_ 2215378947 BATT_vModSumOfCells_3 65535;
BA_ "GenSigSNA" SG_ 2215378947 BATT_iMod_3 32767;
BA_ "GenSigSNA" SG_ 2215378947 BATT_iModFiltered_3 32767;
BA_ "GenSigSNA" SG_ 2215378948 BATT_vMod_4 65535;
BA_ "GenSigSNA" SG_ 2215378948 BATT_vModSumOfCells_4 65535;
BA_ "GenSigSNA" SG_ 2215378948 BATT_iMod_4 32767;
BA_ "GenSigSNA" SG_ 2215378948 BATT_iModFiltered_4 32767;
BA_ "GenSigSNA" SG_ 2215378949 BATT_vMod_5 65535;
BA_ "GenSigSNA" SG_ 2215378949 BATT_vModSumOfCells_5 65535;
BA_ "GenSigSNA" SG_ 2215378949 BATT_iMod_5 32767;
BA_ "GenSigSNA" SG_ 2215378949 BATT_iModFiltered_5 32767;
BA_ "GenSigSNA" SG_ 2215378950 BATT_vMod_6 65535;
BA_ "GenSigSNA" SG_ 2215378950 BATT_vModSumOfCells_6 65535;
BA_ "GenSigSNA" SG_ 2215378950 BATT_iMod_6 32767;
BA_ "GenSigSNA" SG_ 2215378950 BATT_iModFiltered_6 32767;
BA_ "GenSigSNA" SG_ 2215378951 BATT_vMod_7 65535;
BA_ "GenSigSNA" SG_ 2215378951 BATT_vModSumOfCells_7 65535;
BA_ "GenSigSNA" SG_ 2215378951 BATT_iMod_7 32767;
BA_ "GenSigSNA" SG_ 2215378951 BATT_iModFiltered_7 32767;
BA_ "GenSigSNA" SG_ 2215378952 BATT_vMod_8 65535;
BA_ "GenSigSNA" SG_ 2215378952 BATT_vModSumOfCells_8 65535;
BA_ "GenSigSNA" SG_ 2215378952 BATT_iMod_8 32767;
BA_ "GenSigSNA" SG_ 2215378952 BATT_iModFiltered_8 32767;
BA_ "GenSigSNA" SG_ 2215378953 BATT_vMod_9 65535;
BA_ "GenSigSNA" SG_ 2215378953 BATT_vModSumOfCells_9 65535;
BA_ "GenSigSNA" SG_ 2215378953 BATT_iMod_9 32767;
BA_ "GenSigSNA" SG_ 2215378953 BATT_iModFiltered_9 32767;
BA_ "GenSigSNA" SG_ 2215378954 BATT_vMod_10 65535;
BA_ "GenSigSNA" SG_ 2215378954 BATT_vModSumOfCells_10 65535;
BA_ "GenSigSNA" SG_ 2215378954 BATT_iMod_10 32767;
BA_ "GenSigSNA" SG_ 2215378954 BATT_iModFiltered_10 32767;
BA_ "GenSigSNA" SG_ 2215378955 BATT_vMod_11 65535;
BA_ "GenSigSNA" SG_ 2215378955 BATT_vModSumOfCells_11 65535;
BA_ "GenSigSNA" SG_ 2215378955 BATT_iMod_11 32767;
BA_ "GenSigSNA" SG_ 2215378955 BATT_iModFiltered_11 32767;
BA_ "GenSigSNA" SG_ 2215903232 BATT_sohcMod_0 65535;
BA_ "GenSigSNA" SG_ 2215903232 BATT_socMod_0 65535;
BA_ "GenSigSNA" SG_ 2215903232 BATT_idSOCLimiting_0 15;
BA_ "GenSigSNA" SG_ 2215903232 BATT_socLimiting_0 65535;
BA_ "GenSigSNA" SG_ 2215903233 BATT_sohcMod_1 65535;
BA_ "GenSigSNA" SG_ 2215903233 BATT_socLimiting_1 65535;
BA_ "GenSigSNA" SG_ 2215903233 BATT_idSOCLimiting_1 15;
BA_ "GenSigSNA" SG_ 2215903233 BATT_socMod_1 65535;
BA_ "GenSigSNA" SG_ 2215903234 BATT_sohcMod_2 65535;
BA_ "GenSigSNA" SG_ 2215903234 BATT_socMod_2 65535;
BA_ "GenSigSNA" SG_ 2215903234 BATT_socLimiting_2 65535;
BA_ "GenSigSNA" SG_ 2215903234 BATT_idSOCLimiting_2 15;
BA_ "GenSigSNA" SG_ 2215903235 BATT_sohcMod_3 65535;
BA_ "GenSigSNA" SG_ 2215903235 BATT_socMod_3 65535;
BA_ "GenSigSNA" SG_ 2215903235 BATT_socLimiting_3 65535;
BA_ "GenSigSNA" SG_ 2215903235 BATT_idSOCLimiting_3 15;
BA_ "GenSigSNA" SG_ 2215903236 BATT_socMod_4 65535;
BA_ "GenSigSNA" SG_ 2215903236 BATT_socLimiting_4 65535;
BA_ "GenSigSNA" SG_ 2215903236 BATT_idSOCLimiting_4 15;
BA_ "GenSigSNA" SG_ 2215903236 BATT_sohcMod_4 65535;
BA_ "GenSigSNA" SG_ 2215903237 BATT_sohcMod_5 65535;
BA_ "GenSigSNA" SG_ 2215903237 BATT_socMod_5 65535;
BA_ "GenSigSNA" SG_ 2215903237 BATT_socLimiting_5 65535;
BA_ "GenSigSNA" SG_ 2215903237 BATT_idSOCLimiting_5 15;
BA_ "GenSigSNA" SG_ 2215903238 BATT_sohcMod_6 65535;
BA_ "GenSigSNA" SG_ 2215903238 BATT_socMod_6 65535;
BA_ "GenSigSNA" SG_ 2215903238 BATT_socLimiting_6 65535;
BA_ "GenSigSNA" SG_ 2215903238 BATT_idSOCLimiting_6 15;
BA_ "GenSigSNA" SG_ 2215903239 BATT_sohcMod_7 65535;
BA_ "GenSigSNA" SG_ 2215903239 BATT_socMod_7 65535;
BA_ "GenSigSNA" SG_ 2215903239 BATT_socLimiting_7 65535;
BA_ "GenSigSNA" SG_ 2215903239 BATT_idSOCLimiting_7 15;
BA_ "GenSigSNA" SG_ 2215903240 BATT_sohcMod_8 65535;
BA_ "GenSigSNA" SG_ 2215903240 BATT_socMod_8 65535;
BA_ "GenSigSNA" SG_ 2215903240 BATT_socLimiting_8 65535;
BA_ "GenSigSNA" SG_ 2215903240 BATT_idSOCLimiting_8 15;
BA_ "GenSigSNA" SG_ 2215903241 BATT_sohcMod_9 65535;
BA_ "GenSigSNA" SG_ 2215903241 BATT_socMod_9 65535;
BA_ "GenSigSNA" SG_ 2215903241 BATT_socLimiting_9 65535;
BA_ "GenSigSNA" SG_ 2215903241 BATT_idSOCLimiting_9 15;
BA_ "GenSigSNA" SG_ 2215903242 BATT_sohcMod_10 65535;
BA_ "GenSigSNA" SG_ 2215903242 BATT_socMod_10 65535;
BA_ "GenSigSNA" SG_ 2215903242 BATT_socLimiting_10 65535;
BA_ "GenSigSNA" SG_ 2215903242 BATT_idSOCLimiting_10 15;
BA_ "GenSigSNA" SG_ 2215903243 BATT_sohcMod_11 65535;
BA_ "GenSigSNA" SG_ 2215903243 BATT_socMod_11 65535;
BA_ "GenSigSNA" SG_ 2215903243 BATT_socLimiting_11 65535;
BA_ "GenSigSNA" SG_ 2215903243 BATT_idSOCLimiting_11 15;
BA_ "GenSigSNA" SG_ 2219376640 BATT_vModChgLimit_0 65535;
BA_ "GenSigSNA" SG_ 2219376640 BATT_iModChgLimitInst_0 65535;
BA_ "GenSigSNA" SG_ 2219376640 BATT_iModChgLimit10s_0 65535;
BA_ "GenSigSNA" SG_ 2219376640 BATT_iModChgLimitCont_0 65535;
BA_ "GenSigSNA" SG_ 2219376641 BATT_vModChgLimit_1 65535;
BA_ "GenSigSNA" SG_ 2219376641 BATT_iModChgLimitInst_1 65535;
BA_ "GenSigSNA" SG_ 2219376641 BATT_iModChgLimit10s_1 65535;
BA_ "GenSigSNA" SG_ 2219376641 BATT_iModChgLimitCont_1 65535;
BA_ "GenSigSNA" SG_ 2219376642 BATT_vModChgLimit_2 65535;
BA_ "GenSigSNA" SG_ 2219376642 BATT_iModChgLimitInst_2 65535;
BA_ "GenSigSNA" SG_ 2219376642 BATT_iModChgLimit10s_2 65535;
BA_ "GenSigSNA" SG_ 2219376642 BATT_iModChgLimitCont_2 65535;
BA_ "GenSigSNA" SG_ 2219376643 BATT_vModChgLimit_3 65535;
BA_ "GenSigSNA" SG_ 2219376643 BATT_iModChgLimitInst_3 65535;
BA_ "GenSigSNA" SG_ 2219376643 BATT_iModChgLimit10s_3 65535;
BA_ "GenSigSNA" SG_ 2219376643 BATT_iModChgLimitCont_3 65535;
BA_ "GenSigSNA" SG_ 2219376644 BATT_vModChgLimit_4 65535;
BA_ "GenSigSNA" SG_ 2219376644 BATT_iModChgLimitInst_4 65535;
BA_ "GenSigSNA" SG_ 2219376644 BATT_iModChgLimit10s_4 65535;
BA_ "GenSigSNA" SG_ 2219376644 BATT_iModChgLimitCont_4 65535;
BA_ "GenSigSNA" SG_ 2219376645 BATT_vModChgLimit_5 65535;
BA_ "GenSigSNA" SG_ 2219376645 BATT_iModChgLimitInst_5 65535;
BA_ "GenSigSNA" SG_ 2219376645 BATT_iModChgLimit10s_5 65535;
BA_ "GenSigSNA" SG_ 2219376645 BATT_iModChgLimitCont_5 65535;
BA_ "GenSigSNA" SG_ 2219376646 BATT_vModChgLimit_6 65535;
BA_ "GenSigSNA" SG_ 2219376646 BATT_iModChgLimitInst_6 65535;
BA_ "GenSigSNA" SG_ 2219376646 BATT_iModChgLimit10s_6 65535;
BA_ "GenSigSNA" SG_ 2219376646 BATT_iModChgLimitCont_6 65535;
BA_ "GenSigSNA" SG_ 2219376647 BATT_vModChgLimit_7 65535;
BA_ "GenSigSNA" SG_ 2219376647 BATT_iModChgLimitInst_7 65535;
BA_ "GenSigSNA" SG_ 2219376647 BATT_iModChgLimit10s_7 65535;
BA_ "GenSigSNA" SG_ 2219376647 BATT_iModChgLimitCont_7 65535;
BA_ "GenSigSNA" SG_ 2219376648 BATT_vModChgLimit_8 65535;
BA_ "GenSigSNA" SG_ 2219376648 BATT_iModChgLimitInst_8 65535;
BA_ "GenSigSNA" SG_ 2219376648 BATT_iModChgLimit10s_8 65535;
BA_ "GenSigSNA" SG_ 2219376648 BATT_iModChgLimitCont_8 65535;
BA_ "GenSigSNA" SG_ 2219376649 BATT_vModChgLimit_9 65535;
BA_ "GenSigSNA" SG_ 2219376649 BATT_iModChgLimitInst_9 65535;
BA_ "GenSigSNA" SG_ 2219376649 BATT_iModChgLimit10s_9 65535;
BA_ "GenSigSNA" SG_ 2219376649 BATT_iModChgLimitCont_9 65535;
BA_ "GenSigSNA" SG_ 2219376650 BATT_vModChgLimit_10 65535;
BA_ "GenSigSNA" SG_ 2219376650 BATT_iModChgLimitInst_10 65535;
BA_ "GenSigSNA" SG_ 2219376650 BATT_iModChgLimit10s_10 65535;
BA_ "GenSigSNA" SG_ 2219376650 BATT_iModChgLimitCont_10 65535;
BA_ "GenSigSNA" SG_ 2219376651 BATT_vModChgLimit_11 65535;
BA_ "GenSigSNA" SG_ 2219376651 BATT_iModChgLimitInst_11 65535;
BA_ "GenSigSNA" SG_ 2219376651 BATT_iModChgLimit10s_11 65535;
BA_ "GenSigSNA" SG_ 2219376651 BATT_iModChgLimitCont_11 65535;
BA_ "GenSigSNA" SG_ 2219573248 BATT_iModDchLimitInst_0 32767;
BA_ "GenSigSNA" SG_ 2219573248 BATT_iModDchLimit10s_0 32767;
BA_ "GenSigSNA" SG_ 2219573248 BATT_vModDchLimit_0 65535;
BA_ "GenSigSNA" SG_ 2219573249 BATT_iModDchLimit10s_1 32767;
BA_ "GenSigSNA" SG_ 2219573249 BATT_iModDchLimitInst_1 32767;
BA_ "GenSigSNA" SG_ 2219573249 BATT_vModDchLimit_1 65535;
BA_ "GenSigSNA" SG_ 2219573250 BATT_vModDchLimit_2 65535;
BA_ "GenSigSNA" SG_ 2219573250 BATT_iModDchLimitInst_2 32767;
BA_ "GenSigSNA" SG_ 2219573250 BATT_iModDchLimit10s_2 32767;
BA_ "GenSigSNA" SG_ 2219573251 BATT_iModDchLimit10s_3 32767;
BA_ "GenSigSNA" SG_ 2219573251 BATT_vModDchLimit_3 65535;
BA_ "GenSigSNA" SG_ 2219573251 BATT_iModDchLimitInst_3 32767;
BA_ "GenSigSNA" SG_ 2219573252 BATT_iModDchLimitInst_4 32767;
BA_ "GenSigSNA" SG_ 2219573252 BATT_iModDchLimit10s_4 32767;
BA_ "GenSigSNA" SG_ 2219573252 BATT_vModDchLimit_4 65535;
BA_ "GenSigSNA" SG_ 2219573253 BATT_vModDchLimit_5 65535;
BA_ "GenSigSNA" SG_ 2219573253 BATT_iModDchLimitInst_5 32767;
BA_ "GenSigSNA" SG_ 2219573253 BATT_iModDchLimit10s_5 32767;
BA_ "GenSigSNA" SG_ 2219573254 BATT_iModDchLimitInst_6 32767;
BA_ "GenSigSNA" SG_ 2219573254 BATT_iModDchLimit10s_6 32767;
BA_ "GenSigSNA" SG_ 2219573254 BATT_vModDchLimit_6 65535;
BA_ "GenSigSNA" SG_ 2219573255 BATT_iModDchLimit10s_7 32767;
BA_ "GenSigSNA" SG_ 2219573255 BATT_iModDchLimitInst_7 32767;
BA_ "GenSigSNA" SG_ 2219573255 BATT_vModDchLimit_7 65535;
BA_ "GenSigSNA" SG_ 2219573256 BATT_iModDchLimitInst_8 32767;
BA_ "GenSigSNA" SG_ 2219573256 BATT_iModDchLimit10s_8 32767;
BA_ "GenSigSNA" SG_ 2219573256 BATT_vModDchLimit_8 65535;
BA_ "GenSigSNA" SG_ 2219573257 BATT_vModDchLimit_9 65535;
BA_ "GenSigSNA" SG_ 2219573257 BATT_iModDchLimit10s_9 32767;
BA_ "GenSigSNA" SG_ 2219573257 BATT_iModDchLimitInst_9 32767;
BA_ "GenSigSNA" SG_ 2219573258 BATT_vModDchLimit_10 65535;
BA_ "GenSigSNA" SG_ 2219573258 BATT_iModDchLimitInst_10 32767;
BA_ "GenSigSNA" SG_ 2219573258 BATT_iModDchLimit10s_10 32767;
BA_ "GenSigSNA" SG_ 2219573259 BATT_vModDchLimit_11 65535;
BA_ "GenSigSNA" SG_ 2219573259 BATT_iModDchLimit10s_11 32767;
BA_ "GenSigSNA" SG_ 2219573259 BATT_iModDchLimitInst_11 32767;
BA_ "GenSigSNA" SG_ 2219835392 BATT_pwrModDchLimit_0 32767;
BA_ "GenSigSNA" SG_ 2219835392 BATT_pwrModChgLimit_0 65535;
BA_ "GenSigSNA" SG_ 2219835393 BATT_pwrModDchLimit_1 32767;
BA_ "GenSigSNA" SG_ 2219835393 BATT_pwrModChgLimit_1 65535;
BA_ "GenSigSNA" SG_ 2219835394 BATT_pwrModDchLimit_2 32767;
BA_ "GenSigSNA" SG_ 2219835394 BATT_pwrModChgLimit_2 65535;
BA_ "GenSigSNA" SG_ 2219835395 BATT_pwrModDchLimit_3 32767;
BA_ "GenSigSNA" SG_ 2219835395 BATT_pwrModChgLimit_3 65535;
BA_ "GenSigSNA" SG_ 2219835396 BATT_pwrModDchLimit_4 32767;
BA_ "GenSigSNA" SG_ 2219835396 BATT_pwrModChgLimit_4 65535;
BA_ "GenSigSNA" SG_ 2219835397 BATT_pwrModDchLimit_5 32767;
BA_ "GenSigSNA" SG_ 2219835397 BATT_pwrModChgLimit_5 65535;
BA_ "GenSigSNA" SG_ 2219835398 BATT_pwrModDchLimit_6 32767;
BA_ "GenSigSNA" SG_ 2219835398 BATT_pwrModChgLimit_6 65535;
BA_ "GenSigSNA" SG_ 2219835399 BATT_pwrModDchLimit_7 32767;
BA_ "GenSigSNA" SG_ 2219835399 BATT_pwrModChgLimit_7 65535;
BA_ "GenSigSNA" SG_ 2219835400 BATT_pwrModDchLimit_8 32767;
BA_ "GenSigSNA" SG_ 2219835400 BATT_pwrModChgLimit_8 65535;
BA_ "GenSigSNA" SG_ 2219835401 BATT_pwrModDchLimit_9 32767;
BA_ "GenSigSNA" SG_ 2219835401 BATT_pwrModChgLimit_9 65535;
BA_ "GenSigSNA" SG_ 2219835402 BATT_pwrModDchLimit_10 32767;
BA_ "GenSigSNA" SG_ 2219835402 BATT_pwrModChgLimit_10 65535;
BA_ "GenSigSNA" SG_ 2219835403 BATT_pwrModDchLimit_11 32767;
BA_ "GenSigSNA" SG_ 2219835403 BATT_pwrModChgLimit_11 65535;
BA_ "GenSigSNA" SG_ 2221146112 BATT_tModule2_0 32767;
BA_ "GenSigSNA" SG_ 2221146112 BATT_tModule1_0 32767;
BA_ "GenSigSNA" SG_ 2221146112 BATT_tAmbient_0 65535;
BA_ "GenSigSNA" SG_ 2221146113 BATT_tModule2_1 32767;
BA_ "GenSigSNA" SG_ 2221146113 BATT_tModule1_1 32767;
BA_ "GenSigSNA" SG_ 2221146113 BATT_tAmbient_1 65535;
BA_ "GenSigSNA" SG_ 2221146114 BATT_tModule1_2 32767;
BA_ "GenSigSNA" SG_ 2221146114 BATT_tModule2_2 32767;
BA_ "GenSigSNA" SG_ 2221146114 BATT_tAmbient_2 65535;
BA_ "GenSigSNA" SG_ 2221146115 BATT_tModule2_3 32767;
BA_ "GenSigSNA" SG_ 2221146115 BATT_tModule1_3 32767;
BA_ "GenSigSNA" SG_ 2221146115 BATT_tAmbient_3 65535;
BA_ "GenSigSNA" SG_ 2221146116 BATT_tModule2_4 32767;
BA_ "GenSigSNA" SG_ 2221146116 BATT_tModule1_4 32767;
BA_ "GenSigSNA" SG_ 2221146116 BATT_tAmbient_4 65535;
BA_ "GenSigSNA" SG_ 2221146117 BATT_tModule2_5 32767;
BA_ "GenSigSNA" SG_ 2221146117 BATT_tModule1_5 32767;
BA_ "GenSigSNA" SG_ 2221146117 BATT_tAmbient_5 65535;
BA_ "GenSigSNA" SG_ 2221146118 BATT_tAmbient_6 65535;
BA_ "GenSigSNA" SG_ 2221146118 BATT_tModule2_6 32767;
BA_ "GenSigSNA" SG_ 2221146118 BATT_tModule1_6 32767;
BA_ "GenSigSNA" SG_ 2221146119 BATT_tModule2_7 32767;
BA_ "GenSigSNA" SG_ 2221146119 BATT_tModule1_7 32767;
BA_ "GenSigSNA" SG_ 2221146119 BATT_tAmbient_7 65535;
BA_ "GenSigSNA" SG_ 2221146120 BATT_tModule2_8 32767;
BA_ "GenSigSNA" SG_ 2221146120 BATT_tModule1_8 32767;
BA_ "GenSigSNA" SG_ 2221146120 BATT_tAmbient_8 65535;
BA_ "GenSigSNA" SG_ 2221146121 BATT_tModule1_9 32767;
BA_ "GenSigSNA" SG_ 2221146121 BATT_tModule2_9 32767;
BA_ "GenSigSNA" SG_ 2221146121 BATT_tAmbient_9 65535;
BA_ "GenSigSNA" SG_ 2221146122 BATT_tAmbient_10 65535;
BA_ "GenSigSNA" SG_ 2221146122 BATT_tModule2_10 32767;
BA_ "GenSigSNA" SG_ 2221146122 BATT_tModule1_10 32767;
BA_ "GenSigSNA" SG_ 2221146123 BATT_tModule1_11 32767;
BA_ "GenSigSNA" SG_ 2221146123 BATT_tAmbient_11 65535;
BA_ "GenSigSNA" SG_ 2221146123 BATT_tModule2_11 32767;
BA_ "GenSigSNA" SG_ 2222981120 BATT_tShunt_0 65535;
BA_ "GenSigSNA" SG_ 2222981120 BATT_tFET_0 65535;
BA_ "GenSigSNA" SG_ 2222981121 BATT_tShunt_1 65535;
BA_ "GenSigSNA" SG_ 2222981121 BATT_tFET_1 65535;
BA_ "GenSigSNA" SG_ 2222981122 BATT_tShunt_2 65535;
BA_ "GenSigSNA" SG_ 2222981122 BATT_tFET_2 65535;
BA_ "GenSigSNA" SG_ 2222981123 BATT_tShunt_3 65535;
BA_ "GenSigSNA" SG_ 2222981123 BATT_tFET_3 65535;
BA_ "GenSigSNA" SG_ 2222981124 BATT_tShunt_4 65535;
BA_ "GenSigSNA" SG_ 2222981124 BATT_tFET_4 65535;
BA_ "GenSigSNA" SG_ 2222981125 BATT_tShunt_5 65535;
BA_ "GenSigSNA" SG_ 2222981125 BATT_tFET_5 65535;
BA_ "GenSigSNA" SG_ 2222981126 BATT_tShunt_6 65535;
BA_ "GenSigSNA" SG_ 2222981126 BATT_tFET_6 65535;
BA_ "GenSigSNA" SG_ 2222981127 BATT_tShunt_7 65535;
BA_ "GenSigSNA" SG_ 2222981127 BATT_tFET_7 65535;
BA_ "GenSigSNA" SG_ 2222981128 BATT_tShunt_8 65535;
BA_ "GenSigSNA" SG_ 2222981128 BATT_tFET_8 65535;
BA_ "GenSigSNA" SG_ 2222981129 BATT_tShunt_9 65535;
BA_ "GenSigSNA" SG_ 2222981129 BATT_tFET_9 65535;
BA_ "GenSigSNA" SG_ 2222981130 BATT_tShunt_10 65535;
BA_ "GenSigSNA" SG_ 2222981130 BATT_tFET_10 65535;
BA_ "GenSigSNA" SG_ 2222981131 BATT_tShunt_11 65535;
BA_ "GenSigSNA" SG_ 2222981131 BATT_tFET_11 65535;
BA_ "GenSigSNA" SG_ 2224029696 BATT_resMod_0 65535;
BA_ "GenSigSNA" SG_ 2224029696 BATT_voirMod_0 65535;
BA_ "GenSigSNA" SG_ 2224029696 BATT_vModLoad_0 65535;
BA_ "GenSigSNA" SG_ 2224029697 BATT_resMod_1 65535;
BA_ "GenSigSNA" SG_ 2224029697 BATT_voirMod_1 65535;
BA_ "GenSigSNA" SG_ 2224029697 BATT_vModLoad_1 65535;
BA_ "GenSigSNA" SG_ 2224029698 BATT_resMod_2 65535;
BA_ "GenSigSNA" SG_ 2224029698 BATT_voirMod_2 65535;
BA_ "GenSigSNA" SG_ 2224029698 BATT_vModLoad_2 65535;
BA_ "GenSigSNA" SG_ 2224029699 BATT_resMod_3 65535;
BA_ "GenSigSNA" SG_ 2224029699 BATT_voirMod_3 65535;
BA_ "GenSigSNA" SG_ 2224029699 BATT_vModLoad_3 65535;
BA_ "GenSigSNA" SG_ 2224029700 BATT_resMod_4 65535;
BA_ "GenSigSNA" SG_ 2224029700 BATT_voirMod_4 65535;
BA_ "GenSigSNA" SG_ 2224029700 BATT_vModLoad_4 65535;
BA_ "GenSigSNA" SG_ 2224029701 BATT_resMod_5 65535;
BA_ "GenSigSNA" SG_ 2224029701 BATT_voirMod_5 65535;
BA_ "GenSigSNA" SG_ 2224029701 BATT_vModLoad_5 65535;
BA_ "GenSigSNA" SG_ 2224029702 BATT_resMod_6 65535;
BA_ "GenSigSNA" SG_ 2224029702 BATT_voirMod_6 65535;
BA_ "GenSigSNA" SG_ 2224029702 BATT_vModLoad_6 65535;
BA_ "GenSigSNA" SG_ 2224029703 BATT_resMod_7 65535;
BA_ "GenSigSNA" SG_ 2224029703 BATT_voirMod_7 65535;
BA_ "GenSigSNA" SG_ 2224029703 BATT_vModLoad_7 65535;
BA_ "GenSigSNA" SG_ 2224029704 BATT_resMod_8 65535;
BA_ "GenSigSNA" SG_ 2224029704 BATT_voirMod_8 65535;
BA_ "GenSigSNA" SG_ 2224029704 BATT_vModLoad_8 65535;
BA_ "GenSigSNA" SG_ 2224029705 BATT_resMod_9 65535;
BA_ "GenSigSNA" SG_ 2224029705 BATT_voirMod_9 65535;
BA_ "GenSigSNA" SG_ 2224029705 BATT_vModLoad_9 65535;
BA_ "GenSigSNA" SG_ 2224029706 BATT_resMod_10 65535;
BA_ "GenSigSNA" SG_ 2224029706 BATT_voirMod_10 65535;
BA_ "GenSigSNA" SG_ 2224029706 BATT_vModLoad_10 65535;
BA_ "GenSigSNA" SG_ 2224029707 BATT_resMod_11 65535;
BA_ "GenSigSNA" SG_ 2224029707 BATT_voirMod_11 65535;
BA_ "GenSigSNA" SG_ 2224029707 BATT_vModLoad_11 65535;
BA_ "GenSigSNA" SG_ 2224291840 BATT_vBrickMax_0 4095;
BA_ "GenSigSNA" SG_ 2224291840 BATT_tModuleMax_0 2047;
BA_ "GenSigSNA" SG_ 2224291840 BATT_tModuleMin_0 2047;
BA_ "GenSigSNA" SG_ 2224291840 BATT_vBrickMinID_0 15;
BA_ "GenSigSNA" SG_ 2224291840 BATT_vBrickMin_0 4095;
BA_ "GenSigSNA" SG_ 2224291840 BATT_tModuleMinID_0 15;
BA_ "GenSigSNA" SG_ 2224291840 BATT_vBrickMaxID_0 15;
BA_ "GenSigSNA" SG_ 2224291840 BATT_tModuleMaxID_0 15;
BA_ "GenSigSNA" SG_ 2224291841 BATT_vBrickMinID_1 15;
BA_ "GenSigSNA" SG_ 2224291841 BATT_vBrickMax_1 4095;
BA_ "GenSigSNA" SG_ 2224291841 BATT_vBrickMin_1 4095;
BA_ "GenSigSNA" SG_ 2224291841 BATT_tModuleMinID_1 15;
BA_ "GenSigSNA" SG_ 2224291841 BATT_vBrickMaxID_1 15;
BA_ "GenSigSNA" SG_ 2224291841 BATT_tModuleMin_1 2047;
BA_ "GenSigSNA" SG_ 2224291841 BATT_tModuleMaxID_1 15;
BA_ "GenSigSNA" SG_ 2224291841 BATT_tModuleMax_1 2047;
BA_ "GenSigSNA" SG_ 2224291842 BATT_tModuleMaxID_2 15;
BA_ "GenSigSNA" SG_ 2224291842 BATT_vBrickMaxID_2 15;
BA_ "GenSigSNA" SG_ 2224291842 BATT_tModuleMinID_2 15;
BA_ "GenSigSNA" SG_ 2224291842 BATT_tModuleMin_2 2047;
BA_ "GenSigSNA" SG_ 2224291842 BATT_vBrickMinID_2 15;
BA_ "GenSigSNA" SG_ 2224291842 BATT_tModuleMax_2 2047;
BA_ "GenSigSNA" SG_ 2224291842 BATT_vBrickMin_2 4095;
BA_ "GenSigSNA" SG_ 2224291842 BATT_vBrickMax_2 4095;
BA_ "GenSigSNA" SG_ 2224291843 BATT_vBrickMinID_3 15;
BA_ "GenSigSNA" SG_ 2224291843 BATT_tModuleMaxID_3 15;
BA_ "GenSigSNA" SG_ 2224291843 BATT_tModuleMinID_3 15;
BA_ "GenSigSNA" SG_ 2224291843 BATT_tModuleMax_3 2047;
BA_ "GenSigSNA" SG_ 2224291843 BATT_vBrickMaxID_3 15;
BA_ "GenSigSNA" SG_ 2224291843 BATT_vBrickMax_3 4095;
BA_ "GenSigSNA" SG_ 2224291843 BATT_vBrickMin_3 4095;
BA_ "GenSigSNA" SG_ 2224291843 BATT_tModuleMin_3 2047;
BA_ "GenSigSNA" SG_ 2224291844 BATT_vBrickMax_4 4095;
BA_ "GenSigSNA" SG_ 2224291844 BATT_vBrickMin_4 4095;
BA_ "GenSigSNA" SG_ 2224291844 BATT_vBrickMinID_4 15;
BA_ "GenSigSNA" SG_ 2224291844 BATT_tModuleMaxID_4 15;
BA_ "GenSigSNA" SG_ 2224291844 BATT_tModuleMinID_4 15;
BA_ "GenSigSNA" SG_ 2224291844 BATT_vBrickMaxID_4 15;
BA_ "GenSigSNA" SG_ 2224291844 BATT_tModuleMax_4 2047;
BA_ "GenSigSNA" SG_ 2224291844 BATT_tModuleMin_4 2047;
BA_ "GenSigSNA" SG_ 2224291845 BATT_tModuleMaxID_5 15;
BA_ "GenSigSNA" SG_ 2224291845 BATT_tModuleMinID_5 15;
BA_ "GenSigSNA" SG_ 2224291845 BATT_vBrickMaxID_5 15;
BA_ "GenSigSNA" SG_ 2224291845 BATT_tModuleMax_5 2047;
BA_ "GenSigSNA" SG_ 2224291845 BATT_tModuleMin_5 2047;
BA_ "GenSigSNA" SG_ 2224291845 BATT_vBrickMinID_5 15;
BA_ "GenSigSNA" SG_ 2224291845 BATT_vBrickMin_5 4095;
BA_ "GenSigSNA" SG_ 2224291845 BATT_vBrickMax_5 4095;
BA_ "Access" SG_ 257 BATT_chargingVoltage 1;
BA_ "Access" SG_ 257 BATT_chargingCurrent 1;
BA_ "Access" SG_ 2147500032 NODE_ID_CLAIM_SN 1;
BA_ "Access" SG_ 2147500032 NODE_ID_CLAIM_RND 1;
BA_ "Access" SG_ 2147549184 BATT_nodeIdSerialNumber 1;

VAL_ 257 BATT_chargeMode  2 "CV"  1 "CC"  0 "Not Active"  ;
VAL_ 257 BATT_chargerMode  1 "Generic"  0 "Delta Q"  ;
VAL_ 257 BATT_chargeStatus  5 "Error"  4 "Complete"  3 "In Progress"  2 "Charge Needed"  1 "Charge Not Needed"  0 "Unknown"  ;
VAL_ 259 BATT_packState  10 "Disconnect"  9 "ConnectCharge"  8 "ConnectDrive"  7 "SelectCharge"  6 "SelectDrive"  5 "ChargeStandbyConnect"  4 "Reserved"  3 "Charge"  2 "Drive"  1 "StandbyReady"  0 "StandbyNotReady"  ;
VAL_ 260 BATT_packRemainingCap_Ah  65535 "SNA"  ;
VAL_ 260 BATT_packFullChargeCap_Ah  65535 "SNA"  ;
VAL_ 261 BATT_packUserSOC  65535 "SNA"  ;
VAL_ 261 BATT_packSOC  65535 "SNA"  ;
VAL_ 274 BATT_iPackChgLimitInst  65535 "SNA"  ;
VAL_ 274 BATT_iPackChgLimitCont  65535 "SNA"  ;
VAL_ 274 BATT_iPackChgLimit10s  65535 "SNA"  ;
VAL_ 274 BATT_vBusMax  65535 "SNA"  ;
VAL_ 275 BATT_iPackDchLimit10s  32767 "SNA"  ;
VAL_ 275 BATT_vBusMin  65535 "SNA"  ;
VAL_ 275 BATT_iPackDchLimitCont  32767 "SNA"  ;
VAL_ 275 BATT_iPackDchLimitInst  32767 "SNA"  ;
VAL_ 276 BATT_pwrPackChgLimit  65535 "SNA"  ;
VAL_ 276 BATT_pwrPackDchLimit  65535 "SNA"  ;
VAL_ 292 BATT_iPackFiltered  32767 "SNA"  ;
VAL_ 292 BATT_vPackLoad  65535 "SNA"  ;
VAL_ 292 BATT_iPack  32767 "SNA"  ;
VAL_ 292 BATT_vPack  65535 "SNA"  ;
VAL_ 293 BATT_tPackModuleMinID  15 "SNA"  ;
VAL_ 293 BATT_tPackModuleMin  2047 "SNA"  ;
VAL_ 293 BATT_vPackBrickMin  4095 "SNA"  ;
VAL_ 293 BATT_vPackBrickMax  4095 "SNA"  ;
VAL_ 293 BATT_vPackModuleMinID  15 "SNA"  ;
VAL_ 293 BATT_tPackModuleMax  2047 "SNA"  ;
VAL_ 293 BATT_vPackModuleMaxID  15 "SNA"  ;
VAL_ 293 BATT_tPackModuleMaxID  15 "SNA"  ;
VAL_ 1282 HOST_stateRequest  3 "Sleep"  2 "Charge"  1 "Drive"  0 "None"  ;
VAL_ 1809 BATT_vPackConnBusBrickMax  4095 "SNA"  ;
VAL_ 1809 BATT_packConnBusSOC  65535 "SNA"  ;
VAL_ 1809 BATT_vPackConnBusBrickMin  4095 "SNA"  ;
VAL_ 1904 BATT_debugSeverity_0  3 "Severity Level Info"  2 "Severity Level Warning"  1 "Severity Level Error"  0 "Severity Level None"  ;
VAL_ 1905 BATT_debugSeverity_1  3 "Severity Level Info"  2 "Severity Level Warning"  1 "Severity Level Error"  0 "Severity Level None"  ;
VAL_ 1906 BATT_debugSeverity_2  3 "Severity Level Info"  2 "Severity Level Warning"  1 "Severity Level Error"  0 "Severity Level None"  ;
VAL_ 1907 BATT_debugSeverity_3  3 "Severity Level Info"  2 "Severity Level Warning"  1 "Severity Level Error"  0 "Severity Level None"  ;
VAL_ 1908 BATT_debugSeverity_4  3 "Severity Level Info"  2 "Severity Level Warning"  1 "Severity Level Error"  0 "Severity Level None"  ;
VAL_ 1909 BATT_debugSeverity_5  3 "Severity Level Info"  2 "Severity Level Warning"  1 "Severity Level Error"  0 "Severity Level None"  ;
VAL_ 1910 BATT_debugSeverity_6  3 "Severity Level Info"  2 "Severity Level Warning"  1 "Severity Level Error"  0 "Severity Level None"  ;
VAL_ 1911 BATT_debugSeverity_7  3 "Severity Level Info"  2 "Severity Level Warning"  1 "Severity Level Error"  0 "Severity Level None"  ;
VAL_ 1912 BATT_debugSeverity_8  3 "Severity Level Info"  2 "Severity Level Warning"  1 "Severity Level Error"  0 "Severity Level None"  ;
VAL_ 1913 BATT_debugSeverity_9  3 "Severity Level Info"  2 "Severity Level Warning"  1 "Severity Level Error"  0 "Severity Level None"  ;
VAL_ 1914 BATT_debugSeverity_10  3 "Severity Level Info"  2 "Severity Level Warning"  1 "Severity Level Error"  0 "Severity Level None"  ;
VAL_ 1915 BATT_debugSeverity_11  3 "Severity Level Info"  2 "Severity Level Warning"  1 "Severity Level Error"  0 "Severity Level None"  ;
VAL_ 2147549184 BATT_stateRequest  3 "Sleep"  2 "Charge"  1 "Drive"  0 "None"  ;
VAL_ 2215116800 BATT_modFullChargeCap_Ah_0  65535 "SNA"  ;
VAL_ 2215116800 BATT_modRemainingCap_Ah_0  65535 "SNA"  ;
VAL_ 2215116801 BATT_modFullChargeCap_Ah_1  65535 "SNA"  ;
VAL_ 2215116801 BATT_modRemainingCap_Ah_1  65535 "SNA"  ;
VAL_ 2215116802 BATT_modFullChargeCap_Ah_2  65535 "SNA"  ;
VAL_ 2215116802 BATT_modRemainingCap_Ah_2  65535 "SNA"  ;
VAL_ 2215116803 BATT_modFullChargeCap_Ah_3  65535 "SNA"  ;
VAL_ 2215116803 BATT_modRemainingCap_Ah_3  65535 "SNA"  ;
VAL_ 2215116804 BATT_modFullChargeCap_Ah_4  65535 "SNA"  ;
VAL_ 2215116804 BATT_modRemainingCap_Ah_4  65535 "SNA"  ;
VAL_ 2215116805 BATT_modFullChargeCap_Ah_5  65535 "SNA"  ;
VAL_ 2215116805 BATT_modRemainingCap_Ah_5  65535 "SNA"  ;
VAL_ 2215116806 BATT_modFullChargeCap_Ah_6  65535 "SNA"  ;
VAL_ 2215116806 BATT_modRemainingCap_Ah_6  65535 "SNA"  ;
VAL_ 2215116807 BATT_modFullChargeCap_Ah_7  65535 "SNA"  ;
VAL_ 2215116807 BATT_modRemainingCap_Ah_7  65535 "SNA"  ;
VAL_ 2215116808 BATT_modFullChargeCap_Ah_8  65535 "SNA"  ;
VAL_ 2215116808 BATT_modRemainingCap_Ah_8  65535 "SNA"  ;
VAL_ 2215116809 BATT_modFullChargeCap_Ah_9  65535 "SNA"  ;
VAL_ 2215116809 BATT_modRemainingCap_Ah_9  65535 "SNA"  ;
VAL_ 2215116810 BATT_modFullChargeCap_Ah_10  65535 "SNA"  ;
VAL_ 2215116810 BATT_modRemainingCap_Ah_10  65535 "SNA"  ;
VAL_ 2215116811 BATT_modFullChargeCap_Ah_11  65535 "SNA"  ;
VAL_ 2215116811 BATT_modRemainingCap_Ah_11  65535 "SNA"  ;
VAL_ 2215378944 BATT_vMod_0  65535 "SNA"  ;
VAL_ 2215378944 BATT_vModSumOfCells_0  65535 "SNA"  ;
VAL_ 2215378944 BATT_iMod_0  32767 "SNA"  ;
VAL_ 2215378944 BATT_iModFiltered_0  32767 "SNA"  ;
VAL_ 2215378945 BATT_vMod_1  65535 "SNA"  ;
VAL_ 2215378945 BATT_vModSumOfCells_1  65535 "SNA"  ;
VAL_ 2215378945 BATT_iMod_1  32767 "SNA"  ;
VAL_ 2215378945 BATT_iModFiltered_1  32767 "SNA"  ;
VAL_ 2215378946 BATT_vMod_2  65535 "SNA"  ;
VAL_ 2215378946 BATT_vModSumOfCells_2  65535 "SNA"  ;
VAL_ 2215378946 BATT_iMod_2  32767 "SNA"  ;
VAL_ 2215378946 BATT_iModFiltered_2  32767 "SNA"  ;
VAL_ 2215378947 BATT_vMod_3  65535 "SNA"  ;
VAL_ 2215378947 BATT_vModSumOfCells_3  65535 "SNA"  ;
VAL_ 2215378947 BATT_iMod_3  32767 "SNA"  ;
VAL_ 2215378947 BATT_iModFiltered_3  32767 "SNA"  ;
VAL_ 2215378948 BATT_vMod_4  65535 "SNA"  ;
VAL_ 2215378948 BATT_vModSumOfCells_4  65535 "SNA"  ;
VAL_ 2215378948 BATT_iMod_4  32767 "SNA"  ;
VAL_ 2215378948 BATT_iModFiltered_4  32767 "SNA"  ;
VAL_ 2215378949 BATT_vMod_5  65535 "SNA"  ;
VAL_ 2215378949 BATT_vModSumOfCells_5  65535 "SNA"  ;
VAL_ 2215378949 BATT_iMod_5  32767 "SNA"  ;
VAL_ 2215378949 BATT_iModFiltered_5  32767 "SNA"  ;
VAL_ 2215378950 BATT_vMod_6  65535 "SNA"  ;
VAL_ 2215378950 BATT_vModSumOfCells_6  65535 "SNA"  ;
VAL_ 2215378950 BATT_iMod_6  32767 "SNA"  ;
VAL_ 2215378950 BATT_iModFiltered_6  32767 "SNA"  ;
VAL_ 2215378951 BATT_vMod_7  65535 "SNA"  ;
VAL_ 2215378951 BATT_vModSumOfCells_7  65535 "SNA"  ;
VAL_ 2215378951 BATT_iMod_7  32767 "SNA"  ;
VAL_ 2215378951 BATT_iModFiltered_7  32767 "SNA"  ;
VAL_ 2215378952 BATT_vMod_8  65535 "SNA"  ;
VAL_ 2215378952 BATT_vModSumOfCells_8  65535 "SNA"  ;
VAL_ 2215378952 BATT_iMod_8  32767 "SNA"  ;
VAL_ 2215378952 BATT_iModFiltered_8  32767 "SNA"  ;
VAL_ 2215378953 BATT_vMod_9  65535 "SNA"  ;
VAL_ 2215378953 BATT_vModSumOfCells_9  65535 "SNA"  ;
VAL_ 2215378953 BATT_iMod_9  32767 "SNA"  ;
VAL_ 2215378953 BATT_iModFiltered_9  32767 "SNA"  ;
VAL_ 2215378954 BATT_vMod_10  65535 "SNA"  ;
VAL_ 2215378954 BATT_vModSumOfCells_10  65535 "SNA"  ;
VAL_ 2215378954 BATT_iMod_10  32767 "SNA"  ;
VAL_ 2215378954 BATT_iModFiltered_10  32767 "SNA"  ;
VAL_ 2215378955 BATT_vMod_11  65535 "SNA"  ;
VAL_ 2215378955 BATT_vModSumOfCells_11  65535 "SNA"  ;
VAL_ 2215378955 BATT_iMod_11  32767 "SNA"  ;
VAL_ 2215378955 BATT_iModFiltered_11  32767 "SNA"  ;
VAL_ 2215903232 BATT_sohcMod_0  65535 "SNA"  ;
VAL_ 2215903232 BATT_socMod_0  65535 "SNA"  ;
VAL_ 2215903232 BATT_idSOCLimiting_0  15 "SNA"  ;
VAL_ 2215903232 BATT_socLimiting_0  65535 "SNA"  ;
VAL_ 2215903233 BATT_sohcMod_1  65535 "SNA"  ;
VAL_ 2215903233 BATT_socLimiting_1  65535 "SNA"  ;
VAL_ 2215903233 BATT_idSOCLimiting_1  15 "SNA"  ;
VAL_ 2215903233 BATT_socMod_1  65535 "SNA"  ;
VAL_ 2215903234 BATT_sohcMod_2  65535 "SNA"  ;
VAL_ 2215903234 BATT_socMod_2  65535 "SNA"  ;
VAL_ 2215903234 BATT_socLimiting_2  65535 "SNA"  ;
VAL_ 2215903234 BATT_idSOCLimiting_2  15 "SNA"  ;
VAL_ 2215903235 BATT_sohcMod_3  65535 "SNA"  ;
VAL_ 2215903235 BATT_socMod_3  65535 "SNA"  ;
VAL_ 2215903235 BATT_socLimiting_3  65535 "SNA"  ;
VAL_ 2215903235 BATT_idSOCLimiting_3  15 "SNA"  ;
VAL_ 2215903236 BATT_socMod_4  65535 "SNA"  ;
VAL_ 2215903236 BATT_socLimiting_4  65535 "SNA"  ;
VAL_ 2215903236 BATT_idSOCLimiting_4  15 "SNA"  ;
VAL_ 2215903236 BATT_sohcMod_4  65535 "SNA"  ;
VAL_ 2215903237 BATT_sohcMod_5  65535 "SNA"  ;
VAL_ 2215903237 BATT_socMod_5  65535 "SNA"  ;
VAL_ 2215903237 BATT_socLimiting_5  65535 "SNA"  ;
VAL_ 2215903237 BATT_idSOCLimiting_5  15 "SNA"  ;
VAL_ 2215903238 BATT_sohcMod_6  65535 "SNA"  ;
VAL_ 2215903238 BATT_socMod_6  65535 "SNA"  ;
VAL_ 2215903238 BATT_socLimiting_6  65535 "SNA"  ;
VAL_ 2215903238 BATT_idSOCLimiting_6  15 "SNA"  ;
VAL_ 2215903239 BATT_sohcMod_7  65535 "SNA"  ;
VAL_ 2215903239 BATT_socMod_7  65535 "SNA"  ;
VAL_ 2215903239 BATT_socLimiting_7  65535 "SNA"  ;
VAL_ 2215903239 BATT_idSOCLimiting_7  15 "SNA"  ;
VAL_ 2215903240 BATT_sohcMod_8  65535 "SNA"  ;
VAL_ 2215903240 BATT_socMod_8  65535 "SNA"  ;
VAL_ 2215903240 BATT_socLimiting_8  65535 "SNA"  ;
VAL_ 2215903240 BATT_idSOCLimiting_8  15 "SNA"  ;
VAL_ 2215903241 BATT_sohcMod_9  65535 "SNA"  ;
VAL_ 2215903241 BATT_socMod_9  65535 "SNA"  ;
VAL_ 2215903241 BATT_socLimiting_9  65535 "SNA"  ;
VAL_ 2215903241 BATT_idSOCLimiting_9  15 "SNA"  ;
VAL_ 2215903242 BATT_sohcMod_10  65535 "SNA"  ;
VAL_ 2215903242 BATT_socMod_10  65535 "SNA"  ;
VAL_ 2215903242 BATT_socLimiting_10  65535 "SNA"  ;
VAL_ 2215903242 BATT_idSOCLimiting_10  15 "SNA"  ;
VAL_ 2215903243 BATT_sohcMod_11  65535 "SNA"  ;
VAL_ 2215903243 BATT_socMod_11  65535 "SNA"  ;
VAL_ 2215903243 BATT_socLimiting_11  65535 "SNA"  ;
VAL_ 2215903243 BATT_idSOCLimiting_11  15 "SNA"  ;
VAL_ 2219376640 BATT_vModChgLimit_0  65535 "SNA"  ;
VAL_ 2219376640 BATT_iModChgLimitInst_0  65535 "SNA"  ;
VAL_ 2219376640 BATT_iModChgLimit10s_0  65535 "SNA"  ;
VAL_ 2219376640 BATT_iModChgLimitCont_0  65535 "SNA"  ;
VAL_ 2219376641 BATT_vModChgLimit_1  65535 "SNA"  ;
VAL_ 2219376641 BATT_iModChgLimitInst_1  65535 "SNA"  ;
VAL_ 2219376641 BATT_iModChgLimit10s_1  65535 "SNA"  ;
VAL_ 2219376641 BATT_iModChgLimitCont_1  65535 "SNA"  ;
VAL_ 2219376642 BATT_vModChgLimit_2  65535 "SNA"  ;
VAL_ 2219376642 BATT_iModChgLimitInst_2  65535 "SNA"  ;
VAL_ 2219376642 BATT_iModChgLimit10s_2  65535 "SNA"  ;
VAL_ 2219376642 BATT_iModChgLimitCont_2  65535 "SNA"  ;
VAL_ 2219376643 BATT_vModChgLimit_3  65535 "SNA"  ;
VAL_ 2219376643 BATT_iModChgLimitInst_3  65535 "SNA"  ;
VAL_ 2219376643 BATT_iModChgLimit10s_3  65535 "SNA"  ;
VAL_ 2219376643 BATT_iModChgLimitCont_3  65535 "SNA"  ;
VAL_ 2219376644 BATT_vModChgLimit_4  65535 "SNA"  ;
VAL_ 2219376644 BATT_iModChgLimitInst_4  65535 "SNA"  ;
VAL_ 2219376644 BATT_iModChgLimit10s_4  65535 "SNA"  ;
VAL_ 2219376644 BATT_iModChgLimitCont_4  65535 "SNA"  ;
VAL_ 2219376645 BATT_vModChgLimit_5  65535 "SNA"  ;
VAL_ 2219376645 BATT_iModChgLimitInst_5  65535 "SNA"  ;
VAL_ 2219376645 BATT_iModChgLimit10s_5  65535 "SNA"  ;
VAL_ 2219376645 BATT_iModChgLimitCont_5  65535 "SNA"  ;
VAL_ 2219376646 BATT_vModChgLimit_6  65535 "SNA"  ;
VAL_ 2219376646 BATT_iModChgLimitInst_6  65535 "SNA"  ;
VAL_ 2219376646 BATT_iModChgLimit10s_6  65535 "SNA"  ;
VAL_ 2219376646 BATT_iModChgLimitCont_6  65535 "SNA"  ;
VAL_ 2219376647 BATT_vModChgLimit_7  65535 "SNA"  ;
VAL_ 2219376647 BATT_iModChgLimitInst_7  65535 "SNA"  ;
VAL_ 2219376647 BATT_iModChgLimit10s_7  65535 "SNA"  ;
VAL_ 2219376647 BATT_iModChgLimitCont_7  65535 "SNA"  ;
VAL_ 2219376648 BATT_vModChgLimit_8  65535 "SNA"  ;
VAL_ 2219376648 BATT_iModChgLimitInst_8  65535 "SNA"  ;
VAL_ 2219376648 BATT_iModChgLimit10s_8  65535 "SNA"  ;
VAL_ 2219376648 BATT_iModChgLimitCont_8  65535 "SNA"  ;
VAL_ 2219376649 BATT_vModChgLimit_9  65535 "SNA"  ;
VAL_ 2219376649 BATT_iModChgLimitInst_9  65535 "SNA"  ;
VAL_ 2219376649 BATT_iModChgLimit10s_9  65535 "SNA"  ;
VAL_ 2219376649 BATT_iModChgLimitCont_9  65535 "SNA"  ;
VAL_ 2219376650 BATT_vModChgLimit_10  65535 "SNA"  ;
VAL_ 2219376650 BATT_iModChgLimitInst_10  65535 "SNA"  ;
VAL_ 2219376650 BATT_iModChgLimit10s_10  65535 "SNA"  ;
VAL_ 2219376650 BATT_iModChgLimitCont_10  65535 "SNA"  ;
VAL_ 2219376651 BATT_vModChgLimit_11  65535 "SNA"  ;
VAL_ 2219376651 BATT_iModChgLimitInst_11  65535 "SNA"  ;
VAL_ 2219376651 BATT_iModChgLimit10s_11  65535 "SNA"  ;
VAL_ 2219376651 BATT_iModChgLimitCont_11  65535 "SNA"  ;
VAL_ 2219573248 BATT_iModDchLimitCont_0  32767 "SNA"  ;
VAL_ 2219573248 BATT_iModDchLimitInst_0  32767 "SNA"  ;
VAL_ 2219573248 BATT_iModDchLimit10s_0  32767 "SNA"  ;
VAL_ 2219573248 BATT_vModDchLimit_0  65535 "SNA"  ;
VAL_ 2219573249 BATT_iModDchLimit10s_1  32767 "SNA"  ;
VAL_ 2219573249 BATT_iModDchLimitInst_1  32767 "SNA"  ;
VAL_ 2219573249 BATT_vModDchLimit_1  65535 "SNA"  ;
VAL_ 2219573249 BATT_iModDchLimitCont_1  32767 "SNA"  ;
VAL_ 2219573250 BATT_vModDchLimit_2  65535 "SNA"  ;
VAL_ 2219573250 BATT_iModDchLimitInst_2  32767 "SNA"  ;
VAL_ 2219573250 BATT_iModDchLimit10s_2  32767 "SNA"  ;
VAL_ 2219573250 BATT_iModDchLimitCont_2  32767 "SNA"  ;
VAL_ 2219573251 BATT_iModDchLimit10s_3  32767 "SNA"  ;
VAL_ 2219573251 BATT_vModDchLimit_3  65535 "SNA"  ;
VAL_ 2219573251 BATT_iModDchLimitCont_3  32767 "SNA"  ;
VAL_ 2219573251 BATT_iModDchLimitInst_3  32767 "SNA"  ;
VAL_ 2219573252 BATT_iModDchLimitInst_4  32767 "SNA"  ;
VAL_ 2219573252 BATT_iModDchLimit10s_4  32767 "SNA"  ;
VAL_ 2219573252 BATT_vModDchLimit_4  65535 "SNA"  ;
VAL_ 2219573252 BATT_iModDchLimitCont_4  32767 "SNA"  ;
VAL_ 2219573253 BATT_vModDchLimit_5  65535 "SNA"  ;
VAL_ 2219573253 BATT_iModDchLimitInst_5  32767 "SNA"  ;
VAL_ 2219573253 BATT_iModDchLimit10s_5  32767 "SNA"  ;
VAL_ 2219573253 BATT_iModDchLimitCont_5  32767 "SNA"  ;
VAL_ 2219573254 BATT_iModDchLimitInst_6  32767 "SNA"  ;
VAL_ 2219573254 BATT_iModDchLimit10s_6  32767 "SNA"  ;
VAL_ 2219573254 BATT_iModDchLimitCont_6  32767 "SNA"  ;
VAL_ 2219573254 BATT_vModDchLimit_6  65535 "SNA"  ;
VAL_ 2219573255 BATT_iModDchLimit10s_7  32767 "SNA"  ;
VAL_ 2219573255 BATT_iModDchLimitCont_7  32767 "SNA"  ;
VAL_ 2219573255 BATT_iModDchLimitInst_7  32767 "SNA"  ;
VAL_ 2219573255 BATT_vModDchLimit_7  65535 "SNA"  ;
VAL_ 2219573256 BATT_iModDchLimitInst_8  32767 "SNA"  ;
VAL_ 2219573256 BATT_iModDchLimitCont_8  32767 "SNA"  ;
VAL_ 2219573256 BATT_iModDchLimit10s_8  32767 "SNA"  ;
VAL_ 2219573256 BATT_vModDchLimit_8  65535 "SNA"  ;
VAL_ 2219573257 BATT_vModDchLimit_9  65535 "SNA"  ;
VAL_ 2219573257 BATT_iModDchLimit10s_9  32767 "SNA"  ;
VAL_ 2219573257 BATT_iModDchLimitInst_9  32767 "SNA"  ;
VAL_ 2219573257 BATT_iModDchLimitCont_9  32767 "SNA"  ;
VAL_ 2219573258 BATT_vModDchLimit_10  65535 "SNA"  ;
VAL_ 2219573258 BATT_iModDchLimitInst_10  32767 "SNA"  ;
VAL_ 2219573258 BATT_iModDchLimit10s_10  32767 "SNA"  ;
VAL_ 2219573258 BATT_iModDchLimitCont_10  32767 "SNA"  ;
VAL_ 2219573259 BATT_vModDchLimit_11  65535 "SNA"  ;
VAL_ 2219573259 BATT_iModDchLimitCont_11  32767 "SNA"  ;
VAL_ 2219573259 BATT_iModDchLimit10s_11  32767 "SNA"  ;
VAL_ 2219573259 BATT_iModDchLimitInst_11  32767 "SNA"  ;
VAL_ 2219835392 BATT_pwrModDchLimit_0  32767 "SNA"  ;
VAL_ 2219835392 BATT_pwrModChgLimit_0  65535 "SNA"  ;
VAL_ 2219835393 BATT_pwrModDchLimit_1  32767 "SNA"  ;
VAL_ 2219835393 BATT_pwrModChgLimit_1  65535 "SNA"  ;
VAL_ 2219835394 BATT_pwrModDchLimit_2  32767 "SNA"  ;
VAL_ 2219835394 BATT_pwrModChgLimit_2  65535 "SNA"  ;
VAL_ 2219835395 BATT_pwrModDchLimit_3  32767 "SNA"  ;
VAL_ 2219835395 BATT_pwrModChgLimit_3  65535 "SNA"  ;
VAL_ 2219835396 BATT_pwrModDchLimit_4  32767 "SNA"  ;
VAL_ 2219835396 BATT_pwrModChgLimit_4  65535 "SNA"  ;
VAL_ 2219835397 BATT_pwrModDchLimit_5  32767 "SNA"  ;
VAL_ 2219835397 BATT_pwrModChgLimit_5  65535 "SNA"  ;
VAL_ 2219835398 BATT_pwrModDchLimit_6  32767 "SNA"  ;
VAL_ 2219835398 BATT_pwrModChgLimit_6  65535 "SNA"  ;
VAL_ 2219835399 BATT_pwrModDchLimit_7  32767 "SNA"  ;
VAL_ 2219835399 BATT_pwrModChgLimit_7  65535 "SNA"  ;
VAL_ 2219835400 BATT_pwrModDchLimit_8  32767 "SNA"  ;
VAL_ 2219835400 BATT_pwrModChgLimit_8  65535 "SNA"  ;
VAL_ 2219835401 BATT_pwrModDchLimit_9  32767 "SNA"  ;
VAL_ 2219835401 BATT_pwrModChgLimit_9  65535 "SNA"  ;
VAL_ 2219835402 BATT_pwrModDchLimit_10  32767 "SNA"  ;
VAL_ 2219835402 BATT_pwrModChgLimit_10  65535 "SNA"  ;
VAL_ 2219835403 BATT_pwrModDchLimit_11  32767 "SNA"  ;
VAL_ 2219835403 BATT_pwrModChgLimit_11  65535 "SNA"  ;
VAL_ 2221146112 BATT_tModule2_0  32767 "SNA"  ;
VAL_ 2221146112 BATT_tModule1_0  32767 "SNA"  ;
VAL_ 2221146112 BATT_tAmbient_0  65535 "SNA"  ;
VAL_ 2221146113 BATT_tModule2_1  32767 "SNA"  ;
VAL_ 2221146113 BATT_tModule1_1  32767 "SNA"  ;
VAL_ 2221146113 BATT_tAmbient_1  65535 "SNA"  ;
VAL_ 2221146114 BATT_tModule1_2  32767 "SNA"  ;
VAL_ 2221146114 BATT_tModule2_2  32767 "SNA"  ;
VAL_ 2221146114 BATT_tAmbient_2  65535 "SNA"  ;
VAL_ 2221146115 BATT_tModule2_3  32767 "SNA"  ;
VAL_ 2221146115 BATT_tModule1_3  32767 "SNA"  ;
VAL_ 2221146115 BATT_tAmbient_3  65535 "SNA"  ;
VAL_ 2221146116 BATT_tModule2_4  32767 "SNA"  ;
VAL_ 2221146116 BATT_tModule1_4  32767 "SNA"  ;
VAL_ 2221146116 BATT_tAmbient_4  65535 "SNA"  ;
VAL_ 2221146117 BATT_tModule2_5  32767 "SNA"  ;
VAL_ 2221146117 BATT_tModule1_5  32767 "SNA"  ;
VAL_ 2221146117 BATT_tAmbient_5  65535 "SNA"  ;
VAL_ 2221146118 BATT_tAmbient_6  65535 "SNA"  ;
VAL_ 2221146118 BATT_tModule2_6  32767 "SNA"  ;
VAL_ 2221146118 BATT_tModule1_6  32767 "SNA"  ;
VAL_ 2221146119 BATT_tModule2_7  32767 "SNA"  ;
VAL_ 2221146119 BATT_tModule1_7  32767 "SNA"  ;
VAL_ 2221146119 BATT_tAmbient_7  65535 "SNA"  ;
VAL_ 2221146120 BATT_tModule2_8  32767 "SNA"  ;
VAL_ 2221146120 BATT_tModule1_8  32767 "SNA"  ;
VAL_ 2221146120 BATT_tAmbient_8  65535 "SNA"  ;
VAL_ 2221146121 BATT_tModule1_9  32767 "SNA"  ;
VAL_ 2221146121 BATT_tModule2_9  32767 "SNA"  ;
VAL_ 2221146121 BATT_tAmbient_9  65535 "SNA"  ;
VAL_ 2221146122 BATT_tAmbient_10  65535 "SNA"  ;
VAL_ 2221146122 BATT_tModule2_10  32767 "SNA"  ;
VAL_ 2221146122 BATT_tModule1_10  32767 "SNA"  ;
VAL_ 2221146123 BATT_tModule1_11  32767 "SNA"  ;
VAL_ 2221146123 BATT_tAmbient_11  65535 "SNA"  ;
VAL_ 2221146123 BATT_tModule2_11  32767 "SNA"  ;
VAL_ 2222981120 BATT_tShunt_0  65535 "SNA"  ;
VAL_ 2222981120 BATT_tFET_0  65535 "SNA"  ;
VAL_ 2222981121 BATT_tShunt_1  65535 "SNA"  ;
VAL_ 2222981121 BATT_tFET_1  65535 "SNA"  ;
VAL_ 2222981122 BATT_tShunt_2  65535 "SNA"  ;
VAL_ 2222981122 BATT_tFET_2  65535 "SNA"  ;
VAL_ 2222981123 BATT_tShunt_3  65535 "SNA"  ;
VAL_ 2222981123 BATT_tFET_3  65535 "SNA"  ;
VAL_ 2222981124 BATT_tShunt_4  65535 "SNA"  ;
VAL_ 2222981124 BATT_tFET_4  65535 "SNA"  ;
VAL_ 2222981125 BATT_tShunt_5  65535 "SNA"  ;
VAL_ 2222981125 BATT_tFET_5  65535 "SNA"  ;
VAL_ 2222981126 BATT_tShunt_6  65535 "SNA"  ;
VAL_ 2222981126 BATT_tFET_6  65535 "SNA"  ;
VAL_ 2222981127 BATT_tShunt_7  65535 "SNA"  ;
VAL_ 2222981127 BATT_tFET_7  65535 "SNA"  ;
VAL_ 2222981128 BATT_tShunt_8  65535 "SNA"  ;
VAL_ 2222981128 BATT_tFET_8  65535 "SNA"  ;
VAL_ 2222981129 BATT_tShunt_9  65535 "SNA"  ;
VAL_ 2222981129 BATT_tFET_9  65535 "SNA"  ;
VAL_ 2222981130 BATT_tShunt_10  65535 "SNA"  ;
VAL_ 2222981130 BATT_tFET_10  65535 "SNA"  ;
VAL_ 2222981131 BATT_tShunt_11  65535 "SNA"  ;
VAL_ 2222981131 BATT_tFET_11  65535 "SNA"  ;
VAL_ 2224029696 BATT_resMod_0  65535 "SNA"  ;
VAL_ 2224029696 BATT_voirMod_0  65535 "SNA"  ;
VAL_ 2224029696 BATT_vModLoad_0  65535 "SNA"  ;
VAL_ 2224029697 BATT_resMod_1  65535 "SNA"  ;
VAL_ 2224029697 BATT_voirMod_1  65535 "SNA"  ;
VAL_ 2224029697 BATT_vModLoad_1  65535 "SNA"  ;
VAL_ 2224029698 BATT_resMod_2  65535 "SNA"  ;
VAL_ 2224029698 BATT_voirMod_2  65535 "SNA"  ;
VAL_ 2224029698 BATT_vModLoad_2  65535 "SNA"  ;
VAL_ 2224029699 BATT_resMod_3  65535 "SNA"  ;
VAL_ 2224029699 BATT_voirMod_3  65535 "SNA"  ;
VAL_ 2224029699 BATT_vModLoad_3  65535 "SNA"  ;
VAL_ 2224029700 BATT_resMod_4  65535 "SNA"  ;
VAL_ 2224029700 BATT_voirMod_4  65535 "SNA"  ;
VAL_ 2224029700 BATT_vModLoad_4  65535 "SNA"  ;
VAL_ 2224029701 BATT_resMod_5  65535 "SNA"  ;
VAL_ 2224029701 BATT_voirMod_5  65535 "SNA"  ;
VAL_ 2224029701 BATT_vModLoad_5  65535 "SNA"  ;
VAL_ 2224029702 BATT_resMod_6  65535 "SNA"  ;
VAL_ 2224029702 BATT_voirMod_6  65535 "SNA"  ;
VAL_ 2224029702 BATT_vModLoad_6  65535 "SNA"  ;
VAL_ 2224029703 BATT_resMod_7  65535 "SNA"  ;
VAL_ 2224029703 BATT_voirMod_7  65535 "SNA"  ;
VAL_ 2224029703 BATT_vModLoad_7  65535 "SNA"  ;
VAL_ 2224029704 BATT_resMod_8  65535 "SNA"  ;
VAL_ 2224029704 BATT_voirMod_8  65535 "SNA"  ;
VAL_ 2224029704 BATT_vModLoad_8  65535 "SNA"  ;
VAL_ 2224029705 BATT_resMod_9  65535 "SNA"  ;
VAL_ 2224029705 BATT_voirMod_9  65535 "SNA"  ;
VAL_ 2224029705 BATT_vModLoad_9  65535 "SNA"  ;
VAL_ 2224029706 BATT_resMod_10  65535 "SNA"  ;
VAL_ 2224029706 BATT_voirMod_10  65535 "SNA"  ;
VAL_ 2224029706 BATT_vModLoad_10  65535 "SNA"  ;
VAL_ 2224029707 BATT_resMod_11  65535 "SNA"  ;
VAL_ 2224029707 BATT_voirMod_11  65535 "SNA"  ;
VAL_ 2224029707 BATT_vModLoad_11  65535 "SNA"  ;
VAL_ 2224291840 BATT_vBrickMax_0  4095 "SNA"  ;
VAL_ 2224291840 BATT_tModuleMax_0  2047 "SNA"  ;
VAL_ 2224291840 BATT_tModuleMin_0  2047 "SNA"  ;
VAL_ 2224291840 BATT_vBrickMinID_0  15 "SNA"  ;
VAL_ 2224291840 BATT_vBrickMin_0  4095 "SNA"  ;
VAL_ 2224291840 BATT_tModuleMinID_0  15 "SNA"  ;
VAL_ 2224291840 BATT_vBrickMaxID_0  15 "SNA"  ;
VAL_ 2224291840 BATT_tModuleMaxID_0  15 "SNA"  ;
VAL_ 2224291841 BATT_vBrickMinID_1  15 "SNA"  ;
VAL_ 2224291841 BATT_vBrickMax_1  4095 "SNA"  ;
VAL_ 2224291841 BATT_vBrickMin_1  4095 "SNA"  ;
VAL_ 2224291841 BATT_tModuleMinID_1  15 "SNA"  ;
VAL_ 2224291841 BATT_vBrickMaxID_1  15 "SNA"  ;
VAL_ 2224291841 BATT_tModuleMin_1  2047 "SNA"  ;
VAL_ 2224291841 BATT_tModuleMaxID_1  15 "SNA"  ;
VAL_ 2224291841 BATT_tModuleMax_1  2047 "SNA"  ;
VAL_ 2224291842 BATT_tModuleMaxID_2  15 "SNA"  ;
VAL_ 2224291842 BATT_vBrickMaxID_2  15 "SNA"  ;
VAL_ 2224291842 BATT_tModuleMinID_2  15 "SNA"  ;
VAL_ 2224291842 BATT_tModuleMin_2  2047 "SNA"  ;
VAL_ 2224291842 BATT_vBrickMinID_2  15 "SNA"  ;
VAL_ 2224291842 BATT_tModuleMax_2  2047 "SNA"  ;
VAL_ 2224291842 BATT_vBrickMin_2  4095 "SNA"  ;
VAL_ 2224291842 BATT_vBrickMax_2  4095 "SNA"  ;
VAL_ 2224291843 BATT_vBrickMinID_3  15 "SNA"  ;
VAL_ 2224291843 BATT_tModuleMaxID_3  15 "SNA"  ;
VAL_ 2224291843 BATT_tModuleMinID_3  15 "SNA"  ;
VAL_ 2224291843 BATT_tModuleMax_3  2047 "SNA"  ;
VAL_ 2224291843 BATT_vBrickMaxID_3  15 "SNA"  ;
VAL_ 2224291843 BATT_vBrickMax_3  4095 "SNA"  ;
VAL_ 2224291843 BATT_vBrickMin_3  4095 "SNA"  ;
VAL_ 2224291843 BATT_tModuleMin_3  2047 "SNA"  ;
VAL_ 2224291844 BATT_vBrickMax_4  4095 "SNA"  ;
VAL_ 2224291844 BATT_vBrickMin_4  4095 "SNA"  ;
VAL_ 2224291844 BATT_vBrickMinID_4  15 "SNA"  ;
VAL_ 2224291844 BATT_tModuleMaxID_4  15 "SNA"  ;
VAL_ 2224291844 BATT_tModuleMinID_4  15 "SNA"  ;
VAL_ 2224291844 BATT_vBrickMaxID_4  15 "SNA"  ;
VAL_ 2224291844 BATT_tModuleMax_4  2047 "SNA"  ;
VAL_ 2224291844 BATT_tModuleMin_4  2047 "SNA"  ;
VAL_ 2224291845 BATT_tModuleMaxID_5  15 "SNA"  ;
VAL_ 2224291845 BATT_tModuleMinID_5  15 "SNA"  ;
VAL_ 2224291845 BATT_vBrickMaxID_5  15 "SNA"  ;
VAL_ 2224291845 BATT_tModuleMax_5  2047 "SNA"  ;
VAL_ 2224291845 BATT_tModuleMin_5  2047 "SNA"  ;
VAL_ 2224291845 BATT_vBrickMinID_5  15 "SNA"  ;
VAL_ 2224291845 BATT_vBrickMin_5  4095 "SNA"  ;
VAL_ 2224291845 BATT_vBrickMax_5  4095 "SNA"  ;
